VERSION "HNNBNNNYNNNNNNNNNNNNNNNNNNNNNNNNNNNNNNNNNN/4/%%%/4/'%**4NNN///"

NS_ :

BS_ :

BU_:  Airbag BAP_Tester ICAS1_Gateway ICAS1_KommunikationsServer LE1 LE2 Motor_BEV Schaltbetaetigung

BO_ 319 PreCrash_02: 8 Airbag
 SG_ PreCrash_Charisma_FahrPr  : 12|4@1+ (1.000000,0.000000) [0.000000|15.000000] "" ICAS1_Gateway
 SG_ PreCrash_Charisma_Status  : 16|2@1+ (1.000000,0.000000) [0.000000|3.000000] "" ICAS1_Gateway
 SG_ PreCrash_Schiebedach_schliessen  : 18|1@1+ (1.000000,0.000000) [0.000000|1.000000] "" ICAS1_Gateway
 SG_ PreCrash_Fenster_schliessen  : 19|1@1+ (1.000000,0.000000) [0.000000|1.000000] "" ICAS1_Gateway
 SG_ PreCrash_Blinken  : 20|3@1+ (1.000000,0.000000) [0.000000|7.000000] "" ICAS1_Gateway
 SG_ SC_PreSense_FCWP  : 23|1@1+ (1.000000,0.000000) [0.000000|1.000000] "" ICAS1_Gateway
 SG_ PreCrash_Tueren_Verriegeln  : 24|1@1+ (1.000000,0.000000) [0.000000|1.000000] "" ICAS1_Gateway
 SG_ PreCrash_FS_Laengsverstellung  : 25|1@1+ (1.000000,0.000000) [0.000000|1.000000] "" ICAS1_Gateway
 SG_ PreCrash_Anforderung_AFR  : 26|3@1+ (1.000000,0.000000) [0.000000|7.000000] "" ICAS1_Gateway
 SG_ SC_PreCrash_LED  : 29|2@1+ (1.000000,0.000000) [0.000000|3.000000] "" ICAS1_Gateway
 SG_ PreCrash_FS_Pneumatik_ansteuern  : 31|1@1+ (1.000000,0.000000) [0.000000|1.000000] "" ICAS1_Gateway
 SG_ PreCrash_BFS_Pneumatik_ansteuern  : 32|1@1+ (1.000000,0.000000) [0.000000|1.000000] "" ICAS1_Gateway
 SG_ PreCrash_Fo_Pneumatik_ansteuern  : 33|1@1+ (1.000000,0.000000) [0.000000|1.000000] "" ICAS1_Gateway
 SG_ PreCrash_FS_Sitzlehne_verfahren  : 34|3@1+ (1.000000,0.000000) [0.000000|7.000000] "" ICAS1_Gateway
 SG_ PreCrash_BFS_Sitzlehne_verfahren  : 37|3@1+ (1.000000,0.000000) [0.000000|7.000000] "" ICAS1_Gateway
 SG_ PreCrash_Fo_Sitzlehne_verfahren  : 40|3@1+ (1.000000,0.000000) [0.000000|7.000000] "" ICAS1_Gateway
 SG_ PreCrash_FS_KSV_verfahren  : 43|4@1+ (1.000000,0.000000) [0.000000|15.000000] "" ICAS1_Gateway
 SG_ PreCrash_BFS_KSV_verfahren  : 47|4@1+ (1.000000,0.000000) [0.000000|15.000000] "" ICAS1_Gateway
 SG_ PreCrash_Fo_KSV_verfahren  : 51|4@1+ (1.000000,0.000000) [0.000000|15.000000] "" ICAS1_Gateway
 SG_ PreCrash_BFS_Laengsverstellung  : 55|1@1+ (1.000000,0.000000) [0.000000|1.000000] "" ICAS1_Gateway
 SG_ SC_PreCrash_Warnung  : 56|4@1+ (1.000000,0.000000) [0.000000|15.000000] "" ICAS1_Gateway ICAS1_KommunikationsServer
 SG_ SC_PreCrash_Texte  : 60|4@1+ (1.000000,0.000000) [0.000000|15.000000] "" ICAS1_Gateway ICAS1_KommunikationsServer

BO_ 1122 PSD_04: 8 ICAS1_Gateway
 SG_ PSD_Segment_ID  : 0|6@1+ (1.000000,0.000000) [2.000000|63.000000] "" Motor_BEV
 SG_ PSD_Vorgaenger_Segment_ID  : 6|6@1+ (1.000000,0.000000) [2.000000|63.000000] "" Motor_BEV
 SG_ PSD_Segmentlaenge  : 12|7@1+ (2.000000,0.000000) [0.000000|254.000000] "Unit_Meter" Motor_BEV
 SG_ PSD_Strassenkategorie  : 19|3@1+ (1.000000,0.000000) [0.000000|7.000000] "" Motor_BEV
 SG_ PSD_Endkruemmung  : 22|8@1+ (1.000000,0.000000) [0.000000|254.000000] "Unit_None" Motor_BEV
 SG_ PSD_Endkruemmung_Vorz  : 30|1@1+ (1.000000,0.000000) [0.000000|1.000000] "" Motor_BEV
 SG_ PSD_Idenditaets_ID  : 31|6@1+ (1.000000,0.000000) [2.000000|63.000000] "" Vector__XXX
 SG_ PSD_ADAS_Qualitaet  : 37|1@1+ (1.000000,0.000000) [0.000000|1.000000] "" Motor_BEV
 SG_ PSD_wahrscheinlichster_Pfad  : 38|1@1+ (1.000000,0.000000) [0.000000|1.000000] "" Motor_BEV
 SG_ PSD_Geradester_Pfad  : 39|1@1+ (1.000000,0.000000) [0.000000|1.000000] "" Motor_BEV
 SG_ PSD_Fahrspuren_Anzahl  : 40|3@1+ (1.000000,0.000000) [0.000000|7.000000] "" Motor_BEV
 SG_ PSD_Bebauung  : 43|1@1+ (1.000000,0.000000) [0.000000|1.000000] "" Motor_BEV
 SG_ PSD_Segment_Komplett  : 44|1@1+ (1.000000,0.000000) [0.000000|1.000000] "" Motor_BEV
 SG_ PSD_Rampe  : 45|2@1+ (1.000000,0.000000) [0.000000|3.000000] "" Motor_BEV
 SG_ PSD_Anfangskruemmung  : 47|8@1+ (1.000000,0.000000) [0.000000|254.000000] "" Motor_BEV
 SG_ PSD_Anfangskruemmung_Vorz  : 55|1@1+ (1.000000,0.000000) [0.000000|1.000000] "" Motor_BEV
 SG_ PSD_Abzweigerichtung  : 56|1@1+ (1.000000,0.000000) [0.000000|1.000000] "" Motor_BEV
 SG_ PSD_Abzweigewinkel  : 57|7@1+ (1.417323,0.000000) [0.000000|180.000021] "" Motor_BEV

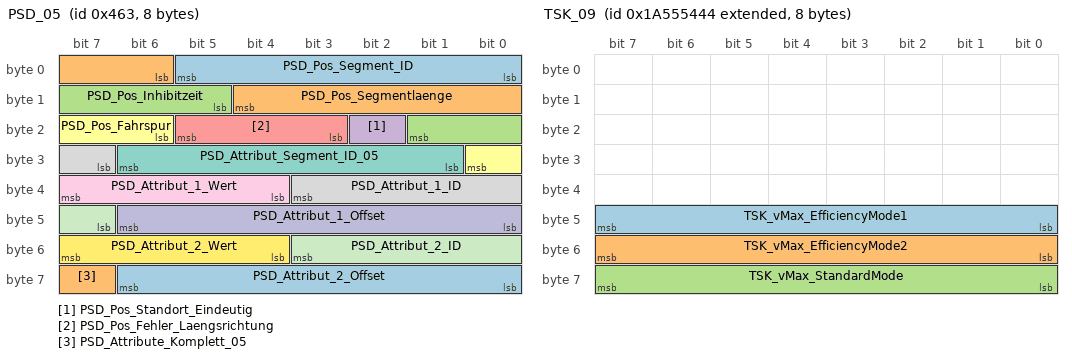
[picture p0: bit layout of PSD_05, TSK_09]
BO_ 1123 PSD_05: 8 ICAS1_Gateway
 SG_ PSD_Pos_Segment_ID  : 0|6@1+ (1.000000,0.000000) [2.000000|63.000000] "" Motor_BEV
 SG_ PSD_Pos_Segmentlaenge  : 6|7@1+ (2.000000,0.000000) [0.000000|254.000000] "Unit_Meter" Motor_BEV
 SG_ PSD_Pos_Inhibitzeit  : 13|5@1+ (10.000000,0.000000) [0.000000|310.000000] "Unit_MilliSecon" Motor_BEV
 SG_ PSD_Pos_Standort_Eindeutig  : 18|1@1+ (1.000000,0.000000) [0.000000|1.000000] "" Motor_BEV
 SG_ PSD_Pos_Fehler_Laengsrichtung  : 19|3@1+ (1.000000,0.000000) [0.000000|7.000000] "" Motor_BEV
 SG_ PSD_Pos_Fahrspur  : 22|3@1+ (1.000000,0.000000) [0.000000|7.000000] "" Motor_BEV
 SG_ PSD_Attribut_Segment_ID_05  : 25|6@1+ (1.000000,0.000000) [2.000000|63.000000] "" Motor_BEV
 SG_ PSD_Attribut_1_ID  : 31|5@1+ (1.000000,0.000000) [1.000000|31.000000] "" Motor_BEV
 SG_ PSD_Attribut_1_Wert  : 36|4@1+ (1.000000,0.000000) [0.000000|15.000000] "" Motor_BEV
 SG_ PSD_Attribut_1_Offset  : 40|7@1+ (2.000000,0.000000) [0.000000|254.000000] "Unit_Meter" Motor_BEV
 SG_ PSD_Attribut_2_ID  : 47|5@1+ (1.000000,0.000000) [1.000000|31.000000] "" Motor_BEV
 SG_ PSD_Attribut_2_Wert  : 52|4@1+ (1.000000,0.000000) [0.000000|15.000000] "" Motor_BEV
 SG_ PSD_Attribut_2_Offset  : 56|7@1+ (2.000000,0.000000) [0.000000|254.000000] "Unit_Meter" Motor_BEV
 SG_ PSD_Attribute_Komplett_05  : 63|1@1+ (1.000000,0.000000) [0.000000|1.000000] "" Motor_BEV

BO_ 1124 PSD_06: 8 ICAS1_Gateway
 SG_ PSD_06_Mux M : 0|3@1+ (1.000000,0.000000) [0.000000|7.000000] "" Motor_BEV
 SG_ PSD_Sys_Segment_ID m0 : 3|6@1+ (1.000000,0.000000) [2.000000|63.000000] "" Motor_BEV
 SG_ PSD_Attribut_Segment_ID m1 : 3|6@1+ (1.000000,0.000000) [2.000000|63.000000] "" Motor_BEV
 SG_ PSD_Ges_Segment_ID m2 : 3|6@1+ (1.000000,0.000000) [2.000000|63.000000] "" Motor_BEV
 SG_ PSD_Baum_Laenge_VZ m3 : 3|1@1+ (1.000000,0.000000) [0.000000|1.000000] "" Motor_BEV
 SG_ PSD_Steigung_1_Segment_ID m4 : 3|6@1+ (1.000000,0.000000) [2.000000|63.000000] "" Motor_BEV
 SG_ PSD_Baum_Laenge m3 : 4|25@1+ (0.000010,0.000000) [0.000000|180.000000] "Unit_DegreOfArc" Motor_BEV
 SG_ PSD_Sys_Laendercode m0 : 9|8@1+ (1.000000,0.000000) [0.000000|255.000000] "" Motor_BEV
 SG_ PSD_Attribut_3_ID m1 : 9|5@1+ (1.000000,0.000000) [1.000000|31.000000] "" Motor_BEV
 SG_ PSD_Ges_Offset m2 : 9|7@1+ (2.000000,0.000000) [0.000000|254.000000] "Unit_Meter" Motor_BEV
 SG_ PSD_Steigung_1_A_Steigung m4 : 9|7@1+ (0.120000,0.000000) [0.000000|15.000000] "Unit_PerCent" Motor_BEV
 SG_ PSD_Attribut_3_Offset m1 : 14|7@1+ (2.000000,0.000000) [0.000000|254.000000] "Unit_Meter" Motor_BEV
 SG_ PSD_Ges_Geschwindigkeit m2 : 16|5@1+ (1.000000,0.000000) [0.000000|31.000000] "" Motor_BEV
 SG_ PSD_Steigung_1_A_Vorz m4 : 16|1@1+ (1.000000,0.000000) [0.000000|1.000000] "" Motor_BEV
 SG_ PSD_Sys_Geschwindigkeit_Einheit m0 : 17|1@1+ (1.000000,0.000000) [0.000000|1.000000] "" Motor_BEV
 SG_ PSD_Steigung_1_A_Offset m4 : 17|7@1+ (2.000000,0.000000) [0.000000|254.000000] "Unit_Meter" Motor_BEV
 SG_ PSD_Sys_Verkehrsrichtung m0 : 18|1@1+ (1.000000,0.000000) [0.000000|1.000000] "" Motor_BEV
 SG_ PSD_Sys_Geometrieguete m0 : 19|2@1+ (1.000000,0.000000) [0.000000|3.000000] "" Motor_BEV
 SG_ PSD_Sys_Mapmatchingguete m0 : 21|2@1+ (1.000000,0.000000) [0.000000|3.000000] "" Motor_BEV
 SG_ PSD_Attribut_3_Wert m1 : 21|4@1+ (1.000000,0.000000) [0.000000|15.000000] "" Motor_BEV
 SG_ PSD_Ges_Typ m2 : 21|2@1+ (1.000000,0.000000) [0.000000|3.000000] "" Motor_BEV
 SG_ PSD_Sys_Alter_Karte m0 : 23|3@1+ (1.000000,0.000000) [0.000000|7.000000] "" Motor_BEV
 SG_ PSD_Ges_Spur_Geschw_Begrenzung m2 : 23|6@1+ (1.000000,0.000000) [0.000000|63.000000] "" Motor_BEV
 SG_ PSD_Steigung_1_B_Steigung m4 : 24|7@1+ (0.120000,0.000000) [0.000000|15.000000] "Unit_PerCent" Motor_BEV
 SG_ PSD_Attribut_4_ID m1 : 25|5@1+ (1.000000,0.000000) [1.000000|31.000000] "" Motor_BEV
 SG_ PSD_Sys_Zielfuehrung m0 : 26|1@1+ (1.000000,0.000000) [0.000000|1.000000] "" Motor_BEV
 SG_ PSD_Sys_US_State m0 : 27|6@1+ (1.000000,0.000000) [0.000000|63.000000] "" Motor_BEV
 SG_ PSD_Ges_Geschwindigkeit_Gespann m2 : 29|2@1+ (1.000000,0.000000) [0.000000|3.000000] "" Motor_BEV
 SG_ PSD_Baum_Breite_VZ m3 : 29|1@1+ (1.000000,0.000000) [0.000000|1.000000] "" Motor_BEV
 SG_ PSD_Attribut_4_Wert m1 : 30|4@1+ (1.000000,0.000000) [0.000000|15.000000] "" Motor_BEV
 SG_ PSD_Baum_Breite m3 : 30|24@1+ (0.000010,0.000000) [0.000000|90.000000] "Unit_DegreOfArc" Motor_BEV
 SG_ PSD_Ges_Geschwindigkeit_Witter m2 : 31|2@1+ (1.000000,0.000000) [0.000000|3.000000] "" Motor_BEV
 SG_ PSD_Steigung_1_B_Vorz m4 : 31|1@1+ (1.000000,0.000000) [0.000000|1.000000] "" Motor_BEV
 SG_ PSD_Steigung_1_B_Offset m4 : 32|7@1+ (2.000000,0.000000) [0.000000|254.000000] "Unit_Meter" Motor_BEV
 SG_ PSD_Sys_Quali_Geometrien m0 : 33|3@1+ (1.000000,0.000000) [0.000000|7.000000] "Unit_None" Vector__XXX
 SG_ PSD_Ges_Geschwindigkeit_Tag_Anf m2 : 33|3@1+ (1.000000,0.000000) [0.000000|7.000000] "" Motor_BEV
 SG_ PSD_Attribut_4_Offset m1 : 34|7@1+ (2.000000,0.000000) [0.000000|254.000000] "Unit_Meter" Motor_BEV
 SG_ PSD_Sys_Quali_Ortsinfo m0 : 36|2@1+ (1.000000,0.000000) [0.000000|3.000000] "Unit_None" Vector__XXX
 SG_ PSD_Ges_Geschwindigkeit_Tag_Ende m2 : 36|3@1+ (1.000000,0.000000) [0.000000|7.000000] "" Motor_BEV
 SG_ PSD_Sys_Quali_verfuegbar m0 : 38|1@1+ (1.000000,0.000000) [0.000000|1.000000] "" Vector__XXX
 SG_ PSD_Sys_Zielfuehrung_geaendert m0 : 39|1@1+ (1.000000,0.000000) [0.000000|1.000000] "" Motor_BEV
 SG_ PSD_Ges_Geschwindigkeit_Std_Anf m2 : 39|5@1+ (1.000000,0.000000) [0.000000|24.000000] "Unit_Hours" Motor_BEV
 SG_ PSD_Steigung_1_Attribute_kompl m4 : 39|1@1+ (1.000000,0.000000) [0.000000|1.000000] "" Motor_BEV
 SG_ PSD_Sys_Geometrieguete_erweitert m0 : 40|8@1+ (1.000000,0.000000) [0.000000|255.000000] "" Vector__XXX
 SG_ PSD_Steigung_2_Segment_ID m4 : 40|6@1+ (1.000000,0.000000) [2.000000|63.000000] "" Motor_BEV
 SG_ PSD_Attribut_5_ID m1 : 41|5@1+ (1.000000,0.000000) [1.000000|31.000000] "" Motor_BEV
 SG_ PSD_Ges_Geschwindigkeit_Std_Ende m2 : 44|5@1+ (1.000000,0.000000) [0.000000|24.000000] "Unit_Hours" Motor_BEV
 SG_ PSD_Attribut_5_Offset m1 : 46|7@1+ (2.000000,0.000000) [0.000000|254.000000] "Unit_Meter" Motor_BEV
 SG_ PSD_Steigung_2_Steigung m4 : 46|7@1+ (0.120000,0.000000) [0.000000|15.000000] "Unit_PerCent" Motor_BEV
 SG_ PSD_Sys_Quali_sonstige_Attribute m0 : 48|3@1+ (1.000000,0.000000) [0.000000|7.000000] "Unit_None" Vector__XXX
 SG_ PSD_Ges_Ueberholverbot m2 : 49|2@1+ (1.000000,0.000000) [0.000000|3.000000] "" Vector__XXX
 SG_ PSD_Sys_Quali_Steigungen m0 : 51|3@1+ (1.000000,0.000000) [0.000000|7.000000] "" Vector__XXX
 SG_ PSD_Ges_Wechselverkehrszeichen m2 : 51|3@1+ (1.000000,0.000000) [0.000000|7.000000] "" Vector__XXX
 SG_ PSD_Attribut_5_Wert m1 : 53|4@1+ (1.000000,0.000000) [0.000000|15.000000] "" Motor_BEV
 SG_ PSD_Steigung_2_Vorz m4 : 53|1@1+ (1.000000,0.000000) [0.000000|1.000000] "" Motor_BEV
 SG_ PSD_Sys_Quali_Strassenkennz m0 : 54|3@1+ (1.000000,0.000000) [0.000000|7.000000] "Unit_None" Vector__XXX
 SG_ PSD_Wechselverkehrszeichen_Typ m2 : 54|2@1+ (1.000000,0.000000) [0.000000|3.000000] "" Vector__XXX
 SG_ PSD_Baum_Ausrichtung m3 : 54|10@1+ (0.351562,0.000000) [0.000000|359.648438] "Unit_DegreOfArc" Vector__XXX
 SG_ PSD_Steigung_2_Offset m4 : 54|7@1+ (2.000000,0.000000) [0.000000|254.000000] "Unit_Meter" Motor_BEV
 SG_ PSD_Ges_Gesetzlich_Kategorie m2 : 56|3@1+ (1.000000,0.000000) [0.000000|7.000000] "" Motor_BEV
 SG_ PSD_Sys_Quali_Tempolimits m0 : 57|3@1+ (1.000000,0.000000) [0.000000|7.000000] "Unit_None" Vector__XXX
 SG_ PSD_Attribute_Komplett_06 m1 : 57|1@1+ (1.000000,0.000000) [0.000000|1.000000] "" Motor_BEV
 SG_ PSD_Ges_Gesetzlich_Zusatz m2 : 59|2@1+ (1.000000,0.000000) [0.000000|3.000000] "" Motor_BEV
 SG_ PSD_Sys_Quali_Vorfahrtsregelung m0 : 60|3@1+ (1.000000,0.000000) [0.000000|7.000000] "Unit_None" Vector__XXX
 SG_ PSD_Ges_Verkehrszeichen_Quelle m2 : 61|2@1+ (1.000000,0.000000) [0.000000|3.000000] "" Motor_BEV
 SG_ PSD_Steigung_2_Attribute_kompl m4 : 61|1@1+ (1.000000,0.000000) [0.000000|1.000000] "" Motor_BEV
 SG_ PSD_Ges_Attribute_Komplett m2 : 63|1@1+ (1.000000,0.000000) [0.000000|1.000000] "" Motor_BEV

BO_ 591 RDR1_Objekte_02: 64 ICAS1_Gateway
 SG_ RDR1_relevanter_Fehler  : 12|1@1+ (1.000000,0.000000) [0.000000|1.000000] "" Motor_BEV
 SG_ RDR1_Blindheit_erkannt  : 13|1@1+ (1.000000,0.000000) [0.000000|1.000000] "" Motor_BEV
 SG_ RDR1_relev_Nichtverfuegbarkeit  : 14|1@1+ (1.000000,0.000000) [0.000000|1.000000] "" Motor_BEV
 SG_ RDR1_Obj_01_Nummer  : 16|6@1+ (1.000000,0.000000) [0.000000|63.000000] "" Vector__XXX
 SG_ RDR1_Obj_02_Nummer  : 22|6@1+ (1.000000,0.000000) [0.000000|63.000000] "" Vector__XXX
 SG_ RDR1_Obj_03_Nummer  : 28|6@1+ (1.000000,0.000000) [0.000000|63.000000] "" Vector__XXX
 SG_ RDR1_Obj_04_Nummer  : 34|6@1+ (1.000000,0.000000) [0.000000|63.000000] "" Vector__XXX
 SG_ RDR1_Obj_05_Nummer  : 40|6@1+ (1.000000,0.000000) [0.000000|63.000000] "" Vector__XXX
 SG_ RDR1_Obj_06_Nummer  : 46|6@1+ (1.000000,0.000000) [0.000000|63.000000] "" Vector__XXX
 SG_ RDR1_Verkehrssinn  : 52|2@1+ (1.000000,0.000000) [0.000000|3.000000] "" Vector__XXX
 SG_ RDR1_Objekte_02_Datenalter  : 54|10@1+ (0.000977,0.000000) [0.000000|0.998047] "Unit_Secon" Vector__XXX
 SG_ RDR1_Obj_01_dx_v  : 64|12@1+ (0.062500,0.000000) [0.000000|255.937500] "Unit_Meter" Motor_BEV
 SG_ RDR1_Obj_01_dy_v  : 76|10@1+ (0.062500,-32.000000) [-32.000000|31.937500] "Unit_Meter" Motor_BEV
 SG_ RDR1_Obj_01_vx_v  : 86|10@1+ (0.250000,-128.000000) [-128.000000|127.750000] "Unit_MeterPerSecon" Motor_BEV
 SG_ RDR1_Obj_02_dx_v  : 96|12@1+ (0.062500,0.000000) [0.000000|255.937500] "Unit_Meter" Vector__XXX
 SG_ RDR1_Obj_02_dy_v  : 108|10@1+ (0.062500,-32.000000) [-32.000000|31.937500] "Unit_Meter" Vector__XXX
 SG_ RDR1_Obj_02_vx_v  : 118|10@1+ (0.250000,-128.000000) [-128.000000|127.750000] "Unit_MeterPerSecon" Vector__XXX
 SG_ RDR1_Obj_03_dx_v  : 128|12@1+ (0.062500,0.000000) [0.000000|255.937500] "Unit_Meter" Vector__XXX
 SG_ RDR1_Obj_03_dy_v  : 140|10@1+ (0.062500,-32.000000) [-32.000000|31.937500] "Unit_Meter" Vector__XXX
 SG_ RDR1_Obj_03_vx_v  : 150|10@1+ (0.250000,-128.000000) [-128.000000|127.750000] "Unit_MeterPerSecon" Vector__XXX
 SG_ RDR1_Obj_04_dx_v  : 160|12@1+ (0.062500,0.000000) [0.000000|255.937500] "Unit_Meter" Motor_BEV
 SG_ RDR1_Obj_04_dy_v  : 172|10@1+ (0.062500,-32.000000) [-32.000000|31.937500] "Unit_Meter" Vector__XXX
 SG_ RDR1_Obj_04_vx_v  : 182|10@1+ (0.250000,-128.000000) [-128.000000|127.750000] "Unit_MeterPerSecon" Motor_BEV
 SG_ RDR1_Obj_05_dx_v  : 192|12@1+ (0.062500,0.000000) [0.000000|255.937500] "Unit_Meter" Vector__XXX
 SG_ RDR1_Obj_05_dy_v  : 204|10@1+ (0.062500,-32.000000) [-32.000000|31.937500] "Unit_Meter" Vector__XXX
 SG_ RDR1_Obj_05_vx_v  : 214|10@1+ (0.250000,-128.000000) [-128.000000|127.750000] "Unit_MeterPerSecon" Vector__XXX
 SG_ RDR1_Obj_06_dx_v  : 224|12@1+ (0.062500,0.000000) [0.000000|255.937500] "Unit_Meter" Vector__XXX
 SG_ RDR1_Obj_06_dy_v  : 236|10@1+ (0.062500,-32.000000) [-32.000000|31.937500] "Unit_Meter" Vector__XXX
 SG_ RDR1_Obj_06_vx_v  : 246|10@1+ (0.250000,-128.000000) [-128.000000|127.750000] "Unit_MeterPerSecon" Vector__XXX
 SG_ RDR1_Obj_01_ax_v  : 256|8@1+ (0.125000,-16.000000) [-16.000000|15.750000] "Unit_MeterPerSeconSquar" Motor_BEV
 SG_ RDR1_Obj_01_ax_StdA  : 264|6@1+ (0.125000,0.000000) [0.000000|7.750000] "Unit_MeterPerSeconSquar" Motor_BEV
 SG_ RDR1_Obj_01_vx_StdA  : 270|7@1+ (0.031250,0.000000) [0.000000|3.937500] "Unit_MeterPerSecon" Motor_BEV
 SG_ RDR1_Obj_01_dx_StdA  : 277|7@1+ (0.050000,0.000000) [0.000000|6.300000] "Unit_Meter" Motor_BEV
 SG_ RDR1_Obj_01_dy_StdA  : 284|7@1+ (0.062500,0.000000) [0.000000|7.875000] "Unit_Meter" Motor_BEV

BO_ 2033 Request_Airbag_Deployment: 8 ICAS1_Gateway
 SG_ Request_Airbag_Deployment  : 0|64@1+ (1.000000,0.000000) [0.000000|18446744073709551616.000000] "" Airbag

BO_ 2041 Response_Airbag_Deployment: 8 Airbag
 SG_ Response_Airbag_Deployment  : 0|64@1+ (1.000000,0.000000) [0.000000|18446744073709551616.000000] "" ICAS1_Gateway

BO_ 980 SMLS_01: 8 ICAS1_Gateway
 SG_ SMLS_01_CRC  : 0|8@1+ (1.000000,0.000000) [0.000000|255.000000] "" Vector__XXX
 SG_ SMLS_01_BZ  : 8|4@1+ (1.000000,0.000000) [0.000000|15.000000] "" Vector__XXX
 SG_ BH_Blinker_li  : 12|1@1+ (1.000000,0.000000) [0.000000|1.000000] "" Motor_BEV
 SG_ BH_Blinker_re  : 13|1@1+ (1.000000,0.000000) [0.000000|1.000000] "" Motor_BEV
 SG_ BH_Lichthupe  : 14|1@1+ (1.000000,0.000000) [0.000000|1.000000] "" Vector__XXX
 SG_ BH_Fernlicht  : 15|1@1+ (1.000000,0.000000) [0.000000|1.000000] "" Vector__XXX
 SG_ WH_Tipwischen  : 16|1@1+ (1.000000,0.000000) [0.000000|1.000000] "" Vector__XXX
 SG_ WH_Intervall  : 17|1@1+ (1.000000,0.000000) [0.000000|1.000000] "" Vector__XXX
 SG_ WH_WischerStufe1  : 18|1@1+ (1.000000,0.000000) [0.000000|1.000000] "" Vector__XXX
 SG_ WH_WischerStufe2  : 19|1@1+ (1.000000,0.000000) [0.000000|1.000000] "" Vector__XXX
 SG_ WH_Frontwaschen  : 20|1@1+ (1.000000,0.000000) [0.000000|1.000000] "" Vector__XXX
 SG_ WH_Heckintervall  : 21|1@1+ (1.000000,0.000000) [0.000000|1.000000] "" Vector__XXX
 SG_ WH_Heckwaschen  : 22|1@1+ (1.000000,0.000000) [0.000000|1.000000] "" Vector__XXX
 SG_ WH_Intervallstufen  : 23|4@1+ (1.000000,0.000000) [0.000000|15.000000] "" Vector__XXX
 SG_ FAS_Taster  : 27|1@1+ (1.000000,0.000000) [0.000000|1.000000] "" Vector__XXX
 SG_ FAS_Taster_Fehler  : 28|1@1+ (1.000000,0.000000) [0.000000|1.000000] "" Vector__XXX
 SG_ SMLS_Hupe  : 29|1@1+ (1.000000,0.000000) [0.000000|1.000000] "" Vector__XXX
 SG_ LRH_on_off  : 30|2@1+ (1.000000,0.000000) [0.000000|3.000000] "" Vector__XXX
 SG_ LSS_Tastencode  : 32|8@1+ (1.000000,0.000000) [0.000000|255.000000] "" Vector__XXX
 SG_ LRH_aktiv  : 40|1@1+ (1.000000,0.000000) [0.000000|1.000000] "" Vector__XXX
 SG_ SMLS_P_verriegelt  : 41|2@1+ (1.000000,0.000000) [0.000000|3.000000] "" Vector__XXX
 SG_ SMLS_P_verriegelt_plausibel  : 43|1@1+ (1.000000,0.000000) [0.000000|1.000000] "" Vector__XXX
 SG_ WH_SRA  : 44|1@1+ (1.000000,0.000000) [0.000000|1.000000] "" Vector__XXX
 SG_ WH_Wischer_Fehler  : 45|1@1+ (1.000000,0.000000) [0.000000|1.000000] "" Vector__XXX
 SG_ BH_Blinker_Fehler  : 46|1@1+ (1.000000,0.000000) [0.000000|1.000000] "" Vector__XXX
 SG_ SMLS_PTT  : 47|1@1+ (1.000000,0.000000) [0.000000|1.000000] "" Vector__XXX
 SG_ WH_Tipwischen_lang  : 48|1@1+ (1.000000,0.000000) [0.000000|1.000000] "" Vector__XXX

BO_ 2464153718 SOK_FoD_MO_01_Req_Chal_01: 8 Motor_BEV
 SG_ SOK_FoD_MO_01_Req_Challenge  : 0|64@1+ (1.000000,0.000000) [0.000000|18446744073709551616.000000] "Unit_None" ICAS1_Gateway

BO_ 2464284790 SOK_FoD_MO_01_Resp_Chal_01: 8 ICAS1_Gateway
 SG_ SOK_FoD_MO_01_Resp_Challenge  : 0|64@1+ (1.000000,0.000000) [0.000000|18446744073709551616.000000] "Unit_None" Motor_BEV

BO_ 1413 Systeminfo_01: 8 ICAS1_Gateway
 SG_ SI_Sammel_SG_Fehler  : 0|6@1+ (1.000000,0.000000) [0.000000|60.000000] "" Vector__XXX
 SG_ SI_P_Mode_gueltig  : 6|1@1+ (1.000000,0.000000) [0.000000|1.000000] "" Vector__XXX
 SG_ SI_Diagnose_Aktiv  : 7|1@1+ (1.000000,0.000000) [0.000000|1.000000] "" Vector__XXX
 SG_ SI_QRS_Mode  : 8|1@1+ (1.000000,0.000000) [0.000000|1.000000] "" Airbag Motor_BEV
 SG_ SI_T_Mode  : 9|1@1+ (1.000000,0.000000) [0.000000|1.000000] "" Motor_BEV
 SG_ SI_NWDF  : 10|1@1+ (1.000000,0.000000) [0.000000|1.000000] "" Vector__XXX
 SG_ SI_NWDF_gueltig  : 11|1@1+ (1.000000,0.000000) [0.000000|1.000000] "" Vector__XXX
 SG_ SI_Sammelfehler  : 12|1@1+ (1.000000,0.000000) [0.000000|1.000000] "" Vector__XXX
 SG_ GW_KD_Fehler  : 13|1@1+ (1.000000,0.000000) [0.000000|1.000000] "" Vector__XXX
 SG_ SI_T_Schutz  : 14|1@1+ (1.000000,0.000000) [0.000000|1.000000] "" Motor_BEV
 SG_ SI_P_Mode  : 15|1@1+ (1.000000,0.000000) [0.000000|1.000000] "" Vector__XXX
 SG_ SI_BUS_01  : 16|1@1+ (1.000000,0.000000) [0.000000|1.000000] "" Vector__XXX
 SG_ SI_BUS_02  : 17|1@1+ (1.000000,0.000000) [0.000000|1.000000] "" Vector__XXX
 SG_ SI_BUS_03  : 18|1@1+ (1.000000,0.000000) [0.000000|1.000000] "" Vector__XXX
 SG_ SI_BUS_04  : 19|1@1+ (1.000000,0.000000) [0.000000|1.000000] "" Vector__XXX
 SG_ SI_BUS_05  : 20|1@1+ (1.000000,0.000000) [0.000000|1.000000] "" Vector__XXX
 SG_ SI_BUS_06  : 21|1@1+ (1.000000,0.000000) [0.000000|1.000000] "" Vector__XXX
 SG_ SI_BUS_07  : 22|1@1+ (1.000000,0.000000) [0.000000|1.000000] "" Vector__XXX
 SG_ SI_BUS_08  : 23|1@1+ (1.000000,0.000000) [0.000000|1.000000] "" Vector__XXX
 SG_ SI_BUS_09  : 24|1@1+ (1.000000,0.000000) [0.000000|1.000000] "" Vector__XXX
 SG_ SI_BUS_10  : 25|1@1+ (1.000000,0.000000) [0.000000|1.000000] "" Vector__XXX
 SG_ SI_BUS_11  : 26|1@1+ (1.000000,0.000000) [0.000000|1.000000] "" Vector__XXX
 SG_ SI_BUS_12  : 27|1@1+ (1.000000,0.000000) [0.000000|1.000000] "" Vector__XXX
 SG_ SI_BUS_13  : 28|1@1+ (1.000000,0.000000) [0.000000|1.000000] "" Vector__XXX
 SG_ SI_BUS_14  : 29|1@1+ (1.000000,0.000000) [0.000000|1.000000] "" Vector__XXX
 SG_ SI_BUS_15  : 30|1@1+ (1.000000,0.000000) [0.000000|1.000000] "" Vector__XXX
 SG_ SI_Bus_Identifikation  : 32|8@1+ (1.000000,0.000000) [0.000000|255.000000] "" Vector__XXX
 SG_ SI_CAB_V10  : 40|24@1+ (1.000000,0.000000) [0.000000|16777215.000000] "" Vector__XXX

BO_ 2589283396 TSK_09: 8 Motor_BEV
 SG_ TSK_vMax_EfficiencyMode1  : 40|8@1+ (1.000000,0.000000) [0.000000|253.000000] "Unit_KiloMeterPerHour" ICAS1_Gateway
 SG_ TSK_vMax_EfficiencyMode2  : 48|8@1+ (1.000000,0.000000) [0.000000|253.000000] "Unit_KiloMeterPerHour" ICAS1_Gateway
 SG_ TSK_vMax_StandardMode  : 56|8@1+ (1.000000,0.000000) [0.000000|253.000000] "Unit_KiloMeterPerHour" ICAS1_Gateway

BO_ 1019 TSK_Ausrollkurve_01: 8 Motor_BEV
 SG_ TSK_Ausrollkurve_Schub_Reku_01 m0 : 0|7@1+ (2.000000,0.000000) [0.000000|252.000000] "Unit_KiloMeterPerHour" ICAS1_Gateway
 SG_ TSK_Ausrollkurve_Schub_Reku_05 m1 : 0|7@1+ (2.000000,0.000000) [0.000000|252.000000] "Unit_KiloMeterPerHour" ICAS1_Gateway
 SG_ TSK_Ausrollkurve_Schub_Reku_09 m2 : 0|7@1+ (2.000000,0.000000) [0.000000|252.000000] "Unit_KiloMeterPerHour" ICAS1_Gateway
 SG_ TSK_Ausrollkurve_Schub_Reku_13 m3 : 0|7@1+ (2.000000,0.000000) [0.000000|252.000000] "Unit_KiloMeterPerHour" ICAS1_Gateway
 SG_ TSK_Ausrollkurve_Schub_Reku_17 m4 : 0|7@1+ (2.000000,0.000000) [0.000000|252.000000] "Unit_KiloMeterPerHour" ICAS1_Gateway
 SG_ TSK_Ausrollkurve_Schub_Reku_02 m0 : 7|7@1+ (2.000000,0.000000) [0.000000|252.000000] "Unit_KiloMeterPerHour" ICAS1_Gateway
 SG_ TSK_Ausrollkurve_Schub_Reku_06 m1 : 7|7@1+ (2.000000,0.000000) [0.000000|252.000000] "Unit_KiloMeterPerHour" ICAS1_Gateway
 SG_ TSK_Ausrollkurve_Schub_Reku_10 m2 : 7|7@1+ (2.000000,0.000000) [0.000000|252.000000] "Unit_KiloMeterPerHour" ICAS1_Gateway
 SG_ TSK_Ausrollkurve_Schub_Reku_14 m3 : 7|7@1+ (2.000000,0.000000) [0.000000|252.000000] "Unit_KiloMeterPerHour" ICAS1_Gateway
 SG_ TSK_Ausrollkurve_Schub_Reku_18 m4 : 7|7@1+ (2.000000,0.000000) [0.000000|252.000000] "Unit_KiloMeterPerHour" ICAS1_Gateway
 SG_ TSK_Ausrollkurve_Schub_Reku_03 m0 : 14|7@1+ (2.000000,0.000000) [0.000000|252.000000] "Unit_KiloMeterPerHour" ICAS1_Gateway
 SG_ TSK_Ausrollkurve_Schub_Reku_07 m1 : 14|7@1+ (2.000000,0.000000) [0.000000|252.000000] "Unit_KiloMeterPerHour" ICAS1_Gateway
 SG_ TSK_Ausrollkurve_Schub_Reku_11 m2 : 14|7@1+ (2.000000,0.000000) [0.000000|252.000000] "Unit_KiloMeterPerHour" ICAS1_Gateway
 SG_ TSK_Ausrollkurve_Schub_Reku_15 m3 : 14|7@1+ (2.000000,0.000000) [0.000000|252.000000] "Unit_KiloMeterPerHour" ICAS1_Gateway
 SG_ TSK_Ausrollkurve_Schub_Reku_19 m4 : 14|7@1+ (2.000000,0.000000) [0.000000|252.000000] "Unit_KiloMeterPerHour" ICAS1_Gateway
 SG_ TSK_Ausrollkurve_Schub_Reku_04 m0 : 21|7@1+ (2.000000,0.000000) [0.000000|252.000000] "Unit_KiloMeterPerHour" ICAS1_Gateway
 SG_ TSK_Ausrollkurve_Schub_Reku_08 m1 : 21|7@1+ (2.000000,0.000000) [0.000000|252.000000] "Unit_KiloMeterPerHour" ICAS1_Gateway
 SG_ TSK_Ausrollkurve_Schub_Reku_12 m2 : 21|7@1+ (2.000000,0.000000) [0.000000|252.000000] "Unit_KiloMeterPerHour" ICAS1_Gateway
 SG_ TSK_Ausrollkurve_Schub_Reku_16 m3 : 21|7@1+ (2.000000,0.000000) [0.000000|252.000000] "Unit_KiloMeterPerHour" ICAS1_Gateway
 SG_ TSK_Ausrollkurve_Schub_Reku_20 m4 : 21|7@1+ (2.000000,0.000000) [0.000000|252.000000] "Unit_KiloMeterPerHour" ICAS1_Gateway
 SG_ TSK_Ausrollkurve_Segeln_01 m0 : 28|7@1+ (2.000000,0.000000) [0.000000|252.000000] "Unit_KiloMeterPerHour" ICAS1_Gateway
 SG_ TSK_Ausrollkurve_Segeln_05 m1 : 28|7@1+ (2.000000,0.000000) [0.000000|252.000000] "Unit_KiloMeterPerHour" ICAS1_Gateway
 SG_ TSK_Ausrollkurve_Segeln_09 m2 : 28|7@1+ (2.000000,0.000000) [0.000000|252.000000] "Unit_KiloMeterPerHour" ICAS1_Gateway
 SG_ TSK_Ausrollkurve_Segeln_13 m3 : 28|7@1+ (2.000000,0.000000) [0.000000|252.000000] "Unit_KiloMeterPerHour" ICAS1_Gateway
 SG_ TSK_Ausrollkurve_Segeln_17 m4 : 28|7@1+ (2.000000,0.000000) [0.000000|252.000000] "Unit_KiloMeterPerHour" ICAS1_Gateway
 SG_ TSK_Ausrollkurve_Segeln_02 m0 : 35|7@1+ (2.000000,0.000000) [0.000000|252.000000] "Unit_KiloMeterPerHour" ICAS1_Gateway
 SG_ TSK_Ausrollkurve_Segeln_06 m1 : 35|7@1+ (2.000000,0.000000) [0.000000|252.000000] "Unit_KiloMeterPerHour" ICAS1_Gateway
 SG_ TSK_Ausrollkurve_Segeln_10 m2 : 35|7@1+ (2.000000,0.000000) [0.000000|252.000000] "Unit_KiloMeterPerHour" ICAS1_Gateway
 SG_ TSK_Ausrollkurve_Segeln_14 m3 : 35|7@1+ (2.000000,0.000000) [0.000000|252.000000] "Unit_KiloMeterPerHour" ICAS1_Gateway
 SG_ TSK_Ausrollkurve_Segeln_18 m4 : 35|7@1+ (2.000000,0.000000) [0.000000|252.000000] "Unit_KiloMeterPerHour" ICAS1_Gateway
 SG_ TSK_Ausrollkurve_Segeln_03 m0 : 42|7@1+ (2.000000,0.000000) [0.000000|252.000000] "Unit_KiloMeterPerHour" ICAS1_Gateway
 SG_ TSK_Ausrollkurve_Segeln_07 m1 : 42|7@1+ (2.000000,0.000000) [0.000000|252.000000] "Unit_KiloMeterPerHour" ICAS1_Gateway
 SG_ TSK_Ausrollkurve_Segeln_11 m2 : 42|7@1+ (2.000000,0.000000) [0.000000|252.000000] "Unit_KiloMeterPerHour" ICAS1_Gateway
 SG_ TSK_Ausrollkurve_Segeln_15 m3 : 42|7@1+ (2.000000,0.000000) [0.000000|252.000000] "Unit_KiloMeterPerHour" ICAS1_Gateway
 SG_ TSK_Ausrollkurve_Segeln_19 m4 : 42|7@1+ (2.000000,0.000000) [0.000000|252.000000] "Unit_KiloMeterPerHour" ICAS1_Gateway
 SG_ TSK_Ausrollkurve_Segeln_04 m0 : 49|7@1+ (2.000000,0.000000) [0.000000|252.000000] "Unit_KiloMeterPerHour" ICAS1_Gateway
 SG_ TSK_Ausrollkurve_Segeln_08 m1 : 49|7@1+ (2.000000,0.000000) [0.000000|252.000000] "Unit_KiloMeterPerHour" ICAS1_Gateway
 SG_ TSK_Ausrollkurve_Segeln_12 m2 : 49|7@1+ (2.000000,0.000000) [0.000000|252.000000] "Unit_KiloMeterPerHour" ICAS1_Gateway
 SG_ TSK_Ausrollkurve_Segeln_16 m3 : 49|7@1+ (2.000000,0.000000) [0.000000|252.000000] "Unit_KiloMeterPerHour" ICAS1_Gateway
 SG_ TSK_Ausrollkurve_Segeln_20 m4 : 49|7@1+ (2.000000,0.000000) [0.000000|252.000000] "Unit_KiloMeterPerHour" ICAS1_Gateway
 SG_ TSK_Ausrollkurve_Mux M : 56|3@1+ (1.000000,0.000000) [0.000000|7.000000] "" ICAS1_Gateway
 SG_ TSK_Ausrollkurve_Reku  : 59|1@1+ (1.000000,0.000000) [0.000000|1.000000] "" ICAS1_Gateway
 SG_ TSK_Ausrollkurve_Schrittweite  : 60|1@1+ (1.000000,0.000000) [0.000000|1.000000] "" ICAS1_Gateway
 SG_ TSK_Ausrollkurve_Zaehler  : 61|2@1+ (1.000000,0.000000) [0.000000|3.000000] "" ICAS1_Gateway

BO_ 1716 VIN_01: 8 ICAS1_Gateway
 SG_ VIN_01_MUX M : 0|2@1+ (1.000000,0.000000) [0.000000|3.000000] "" Airbag Motor_BEV
 SG_ KS_Geheimnis_1 m0 : 8|8@1+ (1.000000,0.000000) [0.000000|255.000000] "" Airbag
 SG_ VIN_4 m1 : 8|8@1+ (1.000000,0.000000) [0.000000|255.000000] "" Airbag Motor_BEV
 SG_ VIN_11 m2 : 8|8@1+ (1.000000,0.000000) [0.000000|255.000000] "" Airbag Motor_BEV
 SG_ KS_Geheimnis_2 m0 : 16|8@1+ (1.000000,0.000000) [0.000000|255.000000] "" Airbag
 SG_ VIN_5 m1 : 16|8@1+ (1.000000,0.000000) [0.000000|255.000000] "" Airbag Motor_BEV
 SG_ VIN_12 m2 : 16|8@1+ (1.000000,0.000000) [0.000000|255.000000] "" Airbag Motor_BEV
 SG_ KS_Geheimnis_3 m0 : 24|8@1+ (1.000000,0.000000) [0.000000|255.000000] "" Airbag
 SG_ VIN_6 m1 : 24|8@1+ (1.000000,0.000000) [0.000000|255.000000] "" Airbag Motor_BEV
 SG_ VIN_13 m2 : 24|8@1+ (1.000000,0.000000) [0.000000|255.000000] "" Airbag Motor_BEV
 SG_ KS_Geheimnis_4 m0 : 32|8@1+ (1.000000,0.000000) [0.000000|255.000000] "" Airbag
 SG_ VIN_7 m1 : 32|8@1+ (1.000000,0.000000) [0.000000|255.000000] "" Airbag Motor_BEV
 SG_ VIN_14 m2 : 32|8@1+ (1.000000,0.000000) [0.000000|255.000000] "" Airbag Motor_BEV
 SG_ VIN_1 m0 : 40|8@1+ (1.000000,0.000000) [0.000000|255.000000] "" Airbag Motor_BEV
 SG_ VIN_8 m1 : 40|8@1+ (1.000000,0.000000) [0.000000|255.000000] "" Airbag Motor_BEV
 SG_ VIN_15 m2 : 40|8@1+ (1.000000,0.000000) [0.000000|255.000000] "" Airbag Motor_BEV
 SG_ VIN_2 m0 : 48|8@1+ (1.000000,0.000000) [0.000000|255.000000] "" Airbag Motor_BEV
 SG_ VIN_9 m1 : 48|8@1+ (1.000000,0.000000) [0.000000|255.000000] "" Airbag Motor_BEV
 SG_ VIN_16 m2 : 48|8@1+ (1.000000,0.000000) [0.000000|255.000000] "" Airbag Motor_BEV
 SG_ VIN_3 m0 : 56|8@1+ (1.000000,0.000000) [0.000000|255.000000] "" Airbag Motor_BEV
 SG_ VIN_10 m1 : 56|8@1+ (1.000000,0.000000) [0.000000|255.000000] "" Airbag Motor_BEV
 SG_ VIN_17 m2 : 56|8@1+ (1.000000,0.000000) [0.000000|255.000000] "" Airbag Motor_BEV

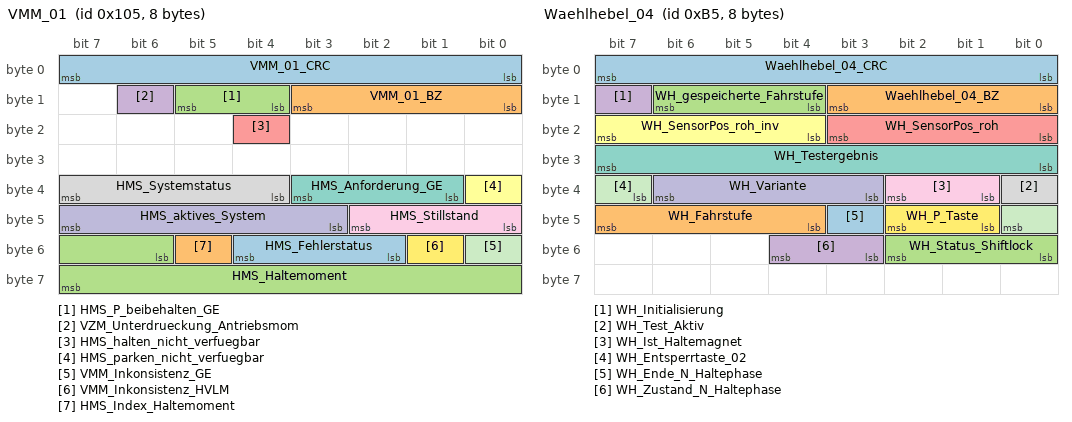
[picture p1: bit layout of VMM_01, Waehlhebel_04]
BO_ 261 VMM_01: 8 ICAS1_Gateway
 SG_ VMM_01_CRC  : 0|8@1+ (1.000000,0.000000) [0.000000|255.000000] "" Motor_BEV
 SG_ VMM_01_BZ  : 8|4@1+ (1.000000,0.000000) [0.000000|15.000000] "" Motor_BEV
 SG_ HMS_P_beibehalten_GE  : 12|2@1+ (1.000000,0.000000) [0.000000|3.000000] "" Vector__XXX
 SG_ VZM_Unterdrueckung_Antriebsmom  : 14|1@1+ (1.000000,0.000000) [0.000000|1.000000] "" Airbag Motor_BEV
 SG_ HMS_halten_nicht_verfuegbar  : 20|1@1+ (1.000000,0.000000) [0.000000|1.000000] "" Vector__XXX
 SG_ HMS_parken_nicht_verfuegbar  : 32|1@1+ (1.000000,0.000000) [0.000000|1.000000] "" Vector__XXX
 SG_ HMS_Anforderung_GE  : 33|3@1+ (1.000000,0.000000) [0.000000|7.000000] "" Vector__XXX
 SG_ HMS_Systemstatus  : 36|4@1+ (1.000000,0.000000) [0.000000|15.000000] "" Motor_BEV
 SG_ HMS_Stillstand  : 40|3@1+ (1.000000,0.000000) [0.000000|7.000000] "" Motor_BEV
 SG_ HMS_aktives_System  : 43|5@1+ (1.000000,0.000000) [0.000000|31.000000] "" Motor_BEV
 SG_ VMM_Inkonsistenz_GE  : 48|1@1+ (1.000000,0.000000) [0.000000|1.000000] "" Motor_BEV
 SG_ VMM_Inkonsistenz_HVLM  : 49|1@1+ (1.000000,0.000000) [0.000000|1.000000] "" Motor_BEV
 SG_ HMS_Fehlerstatus  : 50|3@1+ (1.000000,0.000000) [0.000000|7.000000] "" Vector__XXX
 SG_ HMS_Index_Haltemoment  : 53|1@1+ (1.000000,0.000000) [0.000000|1.000000] "" Motor_BEV
 SG_ HMS_Haltemoment  : 54|10@1+ (10.000000,0.000000) [0.000000|10210.000000] "Unit_NewtoMeter" Motor_BEV

BO_ 313 VMM_02: 32 ICAS1_Gateway
 SG_ VMM_02_CRC  : 0|8@1+ (1.000000,0.000000) [0.000000|255.000000] "" Motor_BEV
 SG_ VMM_02_BZ  : 8|4@1+ (1.000000,0.000000) [0.000000|15.000000] "" Motor_BEV
 SG_ VZM_aktiver_Basisservice  : 12|3@1+ (1.000000,0.000000) [0.000000|7.000000] "" Motor_BEV
 SG_ VZM_Anhalteweg_nicht_verfuegbar  : 15|1@1+ (1.000000,0.000000) [0.000000|1.000000] "" Motor_BEV
 SG_ VZM_Fahrer_bremst  : 16|1@1+ (1.000000,0.000000) [0.000000|1.000000] "" Motor_BEV
 SG_ VZM_QBit_Fahrer_bremst  : 17|1@1+ (1.000000,0.000000) [0.000000|1.000000] "" Motor_BEV
 SG_ VMM_MKB_codiert  : 18|1@1+ (1.000000,0.000000) [0.000000|1.000000] "" Airbag
 SG_ VMM_Inkonsistenz_EBKV  : 19|1@1+ (1.000000,0.000000) [0.000000|1.000000] "" Vector__XXX
 SG_ VMM_Notstopp_Status  : 20|3@1+ (1.000000,0.000000) [0.000000|7.000000] "" Motor_BEV
 SG_ VZM_Warnruck_nicht_verfuegbar  : 23|1@1+ (1.000000,0.000000) [0.000000|1.000000] "" Motor_BEV
 SG_ VZM_Warnruckeln_nicht_verfuegbar  : 24|1@1+ (1.000000,0.000000) [0.000000|1.000000] "" Motor_BEV
 SG_ VZM_Bkd_nicht_verfuegbar  : 25|1@1+ (1.000000,0.000000) [0.000000|1.000000] "" Motor_BEV
 SG_ VMM_Bremslicht_defekt  : 26|1@1+ (1.000000,0.000000) [0.000000|1.000000] "" Motor_BEV
 SG_ VZM_Fahrer_bremst_deutlich  : 27|1@1+ (1.000000,0.000000) [0.000000|1.000000] "" Airbag Motor_BEV
 SG_ VZM_TSK_SRBM_Anf  : 28|1@1+ (1.000000,0.000000) [0.000000|1.000000] "" Motor_BEV
 SG_ VZM_TSK_SRBM_nicht_verfuegbar  : 29|1@1+ (1.000000,0.000000) [0.000000|1.000000] "" Motor_BEV
 SG_ VZM_Verz_Reg_aktiv  : 30|5@1+ (1.000000,0.000000) [0.000000|31.000000] "" Motor_BEV
 SG_ VZM_Verz_Reg_nicht_verfuegbar  : 35|1@1+ (1.000000,0.000000) [0.000000|1.000000] "" Motor_BEV
 SG_ VMM_Inkonsistenz_KAS  : 36|1@1+ (1.000000,0.000000) [0.000000|1.000000] "" Motor_BEV
 SG_ VMM_Bremslicht_unplausibel  : 37|1@1+ (1.000000,0.000000) [0.000000|1.000000] "" Motor_BEV
 SG_ VMM_Inkonsistenz_ACC  : 38|1@1+ (1.000000,0.000000) [0.000000|1.000000] "" Motor_BEV
 SG_ VMM_Inkonsistenz_AWV_PCF  : 39|1@1+ (1.000000,0.000000) [0.000000|1.000000] "" Motor_BEV
 SG_ VMM_Inkonsistenz_ARA  : 40|1@1+ (1.000000,0.000000) [0.000000|1.000000] "" Motor_BEV
 SG_ VMM_Inkonsistenz_ParkAssist  : 41|1@1+ (1.000000,0.000000) [0.000000|1.000000] "" Motor_BEV
 SG_ VMM_Inkonsistenz_FAS_VK  : 42|1@1+ (1.000000,0.000000) [0.000000|1.000000] "" Motor_BEV
 SG_ VMM_Inkonsistenz_NV  : 43|1@1+ (1.000000,0.000000) [0.000000|1.000000] "" Motor_BEV
 SG_ VMM_Inkonsistenz_RCTA  : 44|1@1+ (1.000000,0.000000) [0.000000|1.000000] "" Motor_BEV
 SG_ VMM_Inkonsistenz_TSK  : 45|1@1+ (1.000000,0.000000) [0.000000|1.000000] "" Motor_BEV
 SG_ VMM_Inkonsistenz_MO  : 46|1@1+ (1.000000,0.000000) [0.000000|1.000000] "" Motor_BEV
 SG_ VMM_Inkonsistenz_AEB  : 47|1@1+ (1.000000,0.000000) [0.000000|1.000000] "" Vector__XXX
 SG_ VMM_Fahrer_Bremskraft_bestimmend  : 48|1@1+ (1.000000,0.000000) [0.000000|1.000000] "" Motor_BEV
 SG_ VMM_Inkonsistenz_EA  : 49|1@1+ (1.000000,0.000000) [0.000000|1.000000] "" Motor_BEV
 SG_ VZM_Status_Wegregelung  : 50|2@1+ (1.000000,0.000000) [0.000000|3.000000] "" Motor_BEV
 SG_ VZM_Verz_ASIL_Verfuegbarkeit  : 52|3@1+ (1.000000,0.000000) [0.000000|7.000000] "" Motor_BEV
 SG_ VZM_aktives_System  : 55|5@1+ (1.000000,0.000000) [0.000000|31.000000] "" Airbag Motor_BEV
 SG_ VZM_Verz_Begrenzung  : 60|1@1+ (1.000000,0.000000) [0.000000|1.000000] "" Motor_BEV
 SG_ VZM_Systemstatus  : 61|3@1+ (1.000000,0.000000) [0.000000|7.000000] "" Motor_BEV
 SG_ VZM_SRBM_Soll  : 64|12@1+ (8.000000,0.000000) [0.000000|32744.000000] "Unit_NewtoMeter" Motor_BEV
 SG_ VZM_SRBM_Ist  : 76|12@1+ (8.000000,0.000000) [0.000000|32744.000000] "Unit_NewtoMeter" Motor_BEV
 SG_ VZM_SRBM_max_Gradient  : 88|7@1+ (50.000000,0.000000) [0.000000|6250.000000] "Unit_NewtoMeterPerSecon" Motor_BEV
 SG_ VMM_Inkonsistenz_KAM  : 95|1@1+ (1.000000,0.000000) [0.000000|1.000000] "" Vector__XXX

BO_ 2463978663 VZE_04: 32 ICAS1_Gateway
 SG_ VZE_Anzeigemodus  : 0|2@1+ (1.000000,0.000000) [0.000000|3.000000] "" Vector__XXX
 SG_ VZE_Hinweistext  : 2|3@1+ (1.000000,0.000000) [1.000000|7.000000] "" Motor_BEV
 SG_ VZE_Verkehrszeichen_Einheit  : 8|1@1+ (1.000000,0.000000) [0.000000|1.000000] "" Vector__XXX
 SG_ VZE_Anzeigeunterdrueck_Zeichen_3  : 9|1@1+ (1.000000,0.000000) [0.000000|1.000000] "" Vector__XXX
 SG_ VZE_Anzeigeunterdrueck_Zeichen_2  : 10|1@1+ (1.000000,0.000000) [0.000000|1.000000] "" Vector__XXX
 SG_ VZE_Verkehrszeichen_1  : 11|8@1+ (1.000000,0.000000) [1.000000|255.000000] "" Motor_BEV
 SG_ VZE_Verkehrszeichen_2  : 19|8@1+ (1.000000,0.000000) [1.000000|255.000000] "" Vector__XXX
 SG_ VZE_Verkehrszeichen_3  : 27|8@1+ (1.000000,0.000000) [1.000000|255.000000] "" Vector__XXX
 SG_ VZE_Warnung_Verkehrszeichen_1  : 35|1@1+ (1.000000,0.000000) [0.000000|1.000000] "" Vector__XXX
 SG_ VZE_Warnung_Verkehrszeichen_2  : 36|1@1+ (1.000000,0.000000) [0.000000|1.000000] "" Vector__XXX
 SG_ VZE_Warnung_Verkehrszeichen_3  : 37|1@1+ (1.000000,0.000000) [0.000000|1.000000] "" Vector__XXX
 SG_ VZE_Zusatzschild_1  : 38|4@1+ (1.000000,0.000000) [1.000000|15.000000] "" Vector__XXX
 SG_ VZE_Zusatzschild_2  : 42|4@1+ (1.000000,0.000000) [1.000000|15.000000] "" Vector__XXX
 SG_ VZE_Zusatzschild_3  : 46|4@1+ (1.000000,0.000000) [1.000000|15.000000] "" Vector__XXX
 SG_ VZE_Anzeigeunterdrueck_Zeichen_1  : 50|1@1+ (1.000000,0.000000) [0.000000|1.000000] "" Vector__XXX
 SG_ VZE_Zeichen_01_KameraWied  : 51|1@1+ (1.000000,0.000000) [0.000000|1.000000] "" Motor_BEV
 SG_ VZE_Zeichen_02_KameraWied  : 52|1@1+ (1.000000,0.000000) [0.000000|1.000000] "" Vector__XXX
 SG_ VZE_Zeichen_03_KameraWied  : 53|1@1+ (1.000000,0.000000) [0.000000|1.000000] "" Vector__XXX
 SG_ VZE_Zeichen_01_Kamera  : 54|1@1+ (1.000000,0.000000) [0.000000|1.000000] "" Motor_BEV
 SG_ VZE_Zeichen_01_Karte  : 55|1@1+ (1.000000,0.000000) [0.000000|1.000000] "" Vector__XXX
 SG_ VZE_Zeichen_01_Gesetz  : 56|1@1+ (1.000000,0.000000) [0.000000|1.000000] "" Vector__XXX
 SG_ VZE_Zeichen_02_Kamera  : 57|1@1+ (1.000000,0.000000) [0.000000|1.000000] "" Vector__XXX
 SG_ VZE_Zeichen_02_Karte  : 58|1@1+ (1.000000,0.000000) [0.000000|1.000000] "" Vector__XXX
 SG_ VZE_Zeichen_02_Gesetz  : 59|1@1+ (1.000000,0.000000) [0.000000|1.000000] "" Vector__XXX
 SG_ VZE_Zeichen_03_Kamera  : 60|1@1+ (1.000000,0.000000) [0.000000|1.000000] "" Vector__XXX
 SG_ VZE_Zeichen_03_Karte  : 61|1@1+ (1.000000,0.000000) [0.000000|1.000000] "" Vector__XXX
 SG_ VZE_Zeichen_03_Gesetz  : 62|1@1+ (1.000000,0.000000) [0.000000|1.000000] "" Vector__XXX
 SG_ VZE_Gong  : 63|1@1+ (1.000000,0.000000) [0.000000|1.000000] "" Vector__XXX
 SG_ VZE_Anzeigeunterdrueck_Zeichen_5  : 72|1@1+ (1.000000,0.000000) [0.000000|1.000000] "" Vector__XXX
 SG_ VZE_Zeichen_05_KameraWied  : 73|1@1+ (1.000000,0.000000) [0.000000|1.000000] "" Vector__XXX
 SG_ VZE_Zeichen_05_Kamera  : 74|1@1+ (1.000000,0.000000) [0.000000|1.000000] "" Vector__XXX
 SG_ VZE_Verkehrszeichen_4  : 75|8@1+ (1.000000,0.000000) [1.000000|255.000000] "" Motor_BEV
 SG_ VZE_Verkehrszeichen_5  : 83|8@1+ (1.000000,0.000000) [1.000000|255.000000] "" Motor_BEV
 SG_ VZE_Anhaenger_Vmax  : 91|4@1+ (10.000000,10.000000) [10.000000|140.000000] "Unit_KiloMeterPerHour" Vector__XXX
 SG_ VZE_Zeichen_04_Gesetz  : 95|1@1+ (1.000000,0.000000) [0.000000|1.000000] "" Vector__XXX
 SG_ VZE_Zeichen_04_Kamera  : 96|1@1+ (1.000000,0.000000) [0.000000|1.000000] "" Vector__XXX
 SG_ VZE_Zeichen_04_KameraWied  : 97|1@1+ (1.000000,0.000000) [0.000000|1.000000] "" Vector__XXX
 SG_ VZE_Zeichen_04_Karte  : 98|1@1+ (1.000000,0.000000) [0.000000|1.000000] "" Vector__XXX
 SG_ VZE_Warnung_Verkehrszeichen_4  : 99|1@1+ (1.000000,0.000000) [0.000000|1.000000] "" Vector__XXX
 SG_ VZE_Warnung_Verkehrszeichen_5  : 100|1@1+ (1.000000,0.000000) [0.000000|1.000000] "" Vector__XXX
 SG_ VZE_Zeichen_05_Gesetz  : 101|1@1+ (1.000000,0.000000) [0.000000|1.000000] "" Vector__XXX
 SG_ VZE_Zusatzschild_4  : 102|4@1+ (1.000000,0.000000) [1.000000|15.000000] "" Vector__XXX
 SG_ VZE_Zusatzschild_5  : 106|4@1+ (1.000000,0.000000) [1.000000|15.000000] "" Vector__XXX
 SG_ VZE_Baustelle  : 110|2@1+ (1.000000,0.000000) [0.000000|3.000000] "" Vector__XXX
 SG_ VZE_Zeichen_05_Karte  : 112|1@1+ (1.000000,0.000000) [0.000000|1.000000] "" Vector__XXX
 SG_ VZE_Zeichen_05_Entfernung  : 113|7@1+ (1.000000,0.000000) [1.000000|127.000000] "Unit_Meter" Motor_BEV
 SG_ VZE_Zeichen_05_Entfernung_StdA  : 120|7@1+ (1.000000,0.000000) [1.000000|127.000000] "Unit_Meter" Motor_BEV
 SG_ VZE_Anzeigeunterdrueck_Zeichen_4  : 127|1@1+ (1.000000,0.000000) [0.000000|1.000000] "" Vector__XXX
 SG_ VZE_Verkehrszeichen_6  : 128|8@1+ (1.000000,0.000000) [1.000000|255.000000] "Unit_None" Motor_BEV
 SG_ VZE_Zusatzschild_6  : 136|4@1+ (1.000000,0.000000) [1.000000|15.000000] "" Vector__XXX
 SG_ VZE_Zeichen_06_Entfernung  : 140|7@1+ (1.000000,0.000000) [1.000000|127.000000] "Unit_Meter" Motor_BEV
 SG_ VZE_Zeichen_06_Entfernung_StdA  : 147|7@1+ (1.000000,0.000000) [1.000000|127.000000] "Unit_Meter" Motor_BEV
 SG_ VZE_Umweltinfo_Naesse  : 154|1@1+ (1.000000,0.000000) [0.000000|1.000000] "" Motor_BEV
 SG_ VZE_Umweltinfo_Nebel  : 155|1@1+ (1.000000,0.000000) [0.000000|1.000000] "" Motor_BEV
 SG_ VZE_Umweltinfo_Anhaengerbetrieb  : 156|1@1+ (1.000000,0.000000) [0.000000|1.000000] "" Vector__XXX
 SG_ VZE_Erweiterte_Information  : 157|8@1+ (1.000000,0.000000) [1.000000|255.000000] "Unit_None" Vector__XXX
 SG_ VZE_Tempowarnung_Status  : 165|1@1+ (1.000000,0.000000) [0.000000|1.000000] "" Vector__XXX
 SG_ VZE_Tempowarnung_Einheit  : 166|1@1+ (1.000000,0.000000) [0.000000|1.000000] "" Vector__XXX
 SG_ VZE_Tempowarnung_Offset  : 167|5@1+ (1.000000,0.000000) [1.000000|31.000000] "" Vector__XXX
 SG_ VZE_FoD_Status  : 206|2@1+ (1.000000,0.000000) [0.000000|3.000000] "" Vector__XXX
 SG_ VZE_Anzeige_ZS_1  : 208|4@1+ (1.000000,0.000000) [1.000000|15.000000] "Unit_None" Vector__XXX
 SG_ VZE_Anzeige_ZS_2  : 212|4@1+ (1.000000,0.000000) [1.000000|15.000000] "Unit_None" Vector__XXX
 SG_ VZE_Anzeige_ZS_3  : 216|4@1+ (1.000000,0.000000) [1.000000|15.000000] "Unit_None" Vector__XXX
 SG_ VZE_Hinweistext_03  : 220|4@1+ (1.000000,0.000000) [1.000000|15.000000] "" Vector__XXX
 SG_ VZE_Land  : 224|5@1+ (1.000000,0.000000) [1.000000|31.000000] "" Vector__XXX
 SG_ VZE_Warnung_VZ_1  : 229|1@1+ (1.000000,0.000000) [0.000000|1.000000] "" Vector__XXX
 SG_ VZE_Warnung_VZ_2  : 230|1@1+ (1.000000,0.000000) [0.000000|1.000000] "" Vector__XXX
 SG_ VZE_Warnung_VZ_3  : 231|1@1+ (1.000000,0.000000) [0.000000|1.000000] "" Vector__XXX
 SG_ VZE_Anzeige_VZ_1  : 232|8@1+ (1.000000,0.000000) [1.000000|255.000000] "" Vector__XXX
 SG_ VZE_Anzeige_VZ_2  : 240|8@1+ (1.000000,0.000000) [1.000000|255.000000] "Unit_None" Vector__XXX
 SG_ VZE_Anzeige_VZ_3  : 248|8@1+ (1.000000,0.000000) [1.000000|255.000000] "Unit_None" Vector__XXX

BO_ 181 Waehlhebel_04: 8 ICAS1_Gateway
 SG_ Waehlhebel_04_CRC  : 0|8@1+ (1.000000,0.000000) [0.000000|255.000000] "" Motor_BEV
 SG_ Waehlhebel_04_BZ  : 8|4@1+ (1.000000,0.000000) [0.000000|15.000000] "" Motor_BEV
 SG_ WH_gespeicherte_Fahrstufe  : 12|3@1+ (1.000000,0.000000) [0.000000|7.000000] "" Vector__XXX
 SG_ WH_Initialisierung  : 15|1@1+ (1.000000,0.000000) [0.000000|1.000000] "" Motor_BEV
 SG_ WH_SensorPos_roh  : 16|4@1+ (1.000000,0.000000) [0.000000|15.000000] "" Motor_BEV
 SG_ WH_SensorPos_roh_inv  : 20|4@1+ (1.000000,0.000000) [0.000000|15.000000] "" Motor_BEV
 SG_ WH_Testergebnis  : 24|8@1+ (1.000000,0.000000) [0.000000|255.000000] "" Vector__XXX
 SG_ WH_Test_Aktiv  : 32|1@1+ (1.000000,0.000000) [0.000000|1.000000] "" Vector__XXX
 SG_ WH_Ist_Haltemagnet  : 33|2@1+ (1.000000,0.000000) [0.000000|3.000000] "" Motor_BEV
 SG_ WH_Variante  : 35|4@1+ (1.000000,0.000000) [0.000000|15.000000] "" Motor_BEV
 SG_ WH_Entsperrtaste_02  : 39|2@1+ (1.000000,0.000000) [0.000000|3.000000] "" Motor_BEV
 SG_ WH_P_Taste  : 41|2@1+ (1.000000,0.000000) [0.000000|3.000000] "" Motor_BEV
 SG_ WH_Ende_N_Haltephase  : 43|1@1+ (1.000000,0.000000) [0.000000|1.000000] "" Vector__XXX
 SG_ WH_Fahrstufe  : 44|4@1+ (1.000000,0.000000) [0.000000|15.000000] "" Motor_BEV
 SG_ WH_Status_Shiftlock  : 48|3@1+ (1.000000,0.000000) [0.000000|7.000000] "" Motor_BEV
 SG_ WH_Zustand_N_Haltephase  : 51|2@1+ (1.000000,0.000000) [0.000000|3.000000] "" Vector__XXX

BO_ 2463978687 Waehlhebel_06: 8 ICAS1_Gateway
 SG_ WH_Fehler_Haltemagnet_Status  : 41|1@1+ (1.000000,0.000000) [0.000000|1.000000] "" Motor_BEV
 SG_ WH_Fehler_CRC_SBM  : 42|1@1+ (1.000000,0.000000) [0.000000|1.000000] "" Motor_BEV
 SG_ WH_Fehler_CRC_SBM_Status  : 43|1@1+ (1.000000,0.000000) [0.000000|1.000000] "" Motor_BEV
 SG_ WH_Fehler_Timeout_SBM  : 44|1@1+ (1.000000,0.000000) [0.000000|1.000000] "" Motor_BEV
 SG_ WH_Fehler_Timeout_SBM_Status  : 45|1@1+ (1.000000,0.000000) [0.000000|1.000000] "" Motor_BEV
 SG_ WH_Fehler_Ueberspannung  : 46|1@1+ (1.000000,0.000000) [0.000000|1.000000] "" Motor_BEV
 SG_ WH_Fehler_Ueberspannung_Status  : 47|1@1+ (1.000000,0.000000) [0.000000|1.000000] "" Motor_BEV
 SG_ WH_Fehler_BZ_SBM  : 48|1@1+ (1.000000,0.000000) [0.000000|1.000000] "" Motor_BEV
 SG_ WH_Fehler_BZ_SBM_Status  : 49|1@1+ (1.000000,0.000000) [0.000000|1.000000] "" Motor_BEV
 SG_ WH_Fehler_Unterspannung  : 50|1@1+ (1.000000,0.000000) [0.000000|1.000000] "" Motor_BEV
 SG_ WH_Fehler_Unterspannung_Status  : 51|1@1+ (1.000000,0.000000) [0.000000|1.000000] "" Motor_BEV
 SG_ WH_Fehler_Ausleuchtung  : 52|1@1+ (1.000000,0.000000) [0.000000|1.000000] "" Motor_BEV
 SG_ WH_Fehler_Ausleuchtung_Status  : 53|1@1+ (1.000000,0.000000) [0.000000|1.000000] "" Motor_BEV
 SG_ WH_Fehler_Entsperrtaste  : 54|1@1+ (1.000000,0.000000) [0.000000|1.000000] "" Motor_BEV
 SG_ WH_Fehler_Entsperrtaste_Status  : 55|1@1+ (1.000000,0.000000) [0.000000|1.000000] "" Motor_BEV
 SG_ WH_Fehler_P_Taste  : 56|1@1+ (1.000000,0.000000) [0.000000|1.000000] "" Motor_BEV
 SG_ WH_Fehler_P_Taste_Status  : 57|1@1+ (1.000000,0.000000) [0.000000|1.000000] "" Motor_BEV
 SG_ WH_Fehler_Sensor_einfach  : 58|1@1+ (1.000000,0.000000) [0.000000|1.000000] "" Motor_BEV
 SG_ WH_Fehler_Sensor_einfach_Status  : 59|1@1+ (1.000000,0.000000) [0.000000|1.000000] "" Motor_BEV
 SG_ WH_Fehler_Sensor_mehrfach  : 60|1@1+ (1.000000,0.000000) [0.000000|1.000000] "" Motor_BEV
 SG_ WH_Fehler_Sensor_mehrfach_Status  : 61|1@1+ (1.000000,0.000000) [0.000000|1.000000] "" Motor_BEV
 SG_ WH_Fehler_Shiftlock  : 62|1@1+ (1.000000,0.000000) [0.000000|1.000000] "" Motor_BEV
 SG_ WH_Fehler_Shiftlock_Status  : 63|1@1+ (1.000000,0.000000) [0.000000|1.000000] "" Motor_BEV

BO_ 916 WBA_03: 8 Motor_BEV
 SG_ WBA_03_CRC  : 0|8@1+ (1.000000,0.000000) [0.000000|255.000000] "" ICAS1_Gateway
 SG_ WBA_03_BZ  : 8|4@1+ (1.000000,0.000000) [0.000000|15.000000] "" ICAS1_Gateway
 SG_ WBA_Fahrstufe_02  : 12|4@1+ (1.000000,0.000000) [0.000000|15.000000] "" ICAS1_Gateway ICAS1_KommunikationsServer
 SG_ WBA_ZielFahrstufe  : 16|4@1+ (1.000000,0.000000) [0.000000|15.000000] "" ICAS1_Gateway
 SG_ WBA_GE_Warnung_02  : 20|4@1+ (1.000000,0.000000) [0.000000|15.000000] "" ICAS1_Gateway
 SG_ WBA_eing_Gang_02  : 24|4@1+ (1.000000,0.000000) [0.000000|15.000000] "" ICAS1_Gateway
 SG_ WBA_GE_Texte  : 28|3@1+ (1.000000,0.000000) [0.000000|7.000000] "" ICAS1_Gateway
 SG_ WBA_Segeln_aktiv  : 31|1@1+ (1.000000,0.000000) [0.000000|1.000000] "" ICAS1_Gateway
 SG_ WBA_Schaltschema_02  : 32|3@1+ (1.000000,0.000000) [0.000000|7.000000] "" ICAS1_Gateway
 SG_ WBA_Schaltschema_FS_inaktiv  : 35|2@1+ (1.000000,0.000000) [0.000000|3.000000] "" ICAS1_Gateway
 SG_ WBA_GE_Zusatzwarnungen  : 37|3@1+ (1.000000,0.000000) [0.000000|7.000000] "" ICAS1_Gateway
 SG_ GE_Sollgang  : 40|4@1+ (1.000000,0.000000) [0.000000|15.000000] "" ICAS1_Gateway
 SG_ GE_Tipschaltempf_verfuegbar  : 44|1@1+ (1.000000,0.000000) [0.000000|1.000000] "" ICAS1_Gateway
 SG_ WBA_GE_Texte_02  : 45|3@1+ (1.000000,0.000000) [0.000000|7.000000] "" ICAS1_Gateway
 SG_ WBA_Schaltschema_Tippgasse  : 48|1@1+ (1.000000,0.000000) [0.000000|1.000000] "" ICAS1_Gateway
 SG_ WBA_Schaltschema_Fahreraktion  : 49|1@1+ (1.000000,0.000000) [0.000000|1.000000] "" ICAS1_Gateway
 SG_ WBA_Schaltschema_FS_vorwaerts  : 50|2@1+ (1.000000,0.000000) [0.000000|3.000000] "" ICAS1_Gateway
 SG_ WBA_Shiftlock_Lampe  : 52|1@1+ (1.000000,0.000000) [0.000000|1.000000] "" ICAS1_Gateway
 SG_ WBA_Anforderung_Akustik  : 53|1@1+ (1.000000,0.000000) [0.000000|1.000000] "" ICAS1_Gateway
 SG_ WBA_Blinken  : 54|1@1+ (1.000000,0.000000) [0.000000|1.000000] "" ICAS1_Gateway
 SG_ GE_Wiederstart_Anz_Std  : 55|1@1+ (1.000000,0.000000) [0.000000|1.000000] "" ICAS1_Gateway
 SG_ GE_Stoppverbot_Anz_01  : 56|1@1+ (1.000000,0.000000) [0.000000|1.000000] "" ICAS1_Gateway
 SG_ GE_Stoppverbot_Anz_02  : 57|1@1+ (1.000000,0.000000) [0.000000|1.000000] "" ICAS1_Gateway
 SG_ GE_Stoppverbot_Anz_03  : 58|1@1+ (1.000000,0.000000) [0.000000|1.000000] "" ICAS1_Gateway
 SG_ GE_Stoppverbot_Anz_04  : 59|1@1+ (1.000000,0.000000) [0.000000|1.000000] "" ICAS1_Gateway
 SG_ GE_Stoppverbot_Anz_05  : 60|1@1+ (1.000000,0.000000) [0.000000|1.000000] "" ICAS1_Gateway
 SG_ GE_Stoppverbot_Anz_06  : 61|1@1+ (1.000000,0.000000) [0.000000|1.000000] "" ICAS1_Gateway
 SG_ GE_Stoppverbot_Anz_07  : 62|1@1+ (1.000000,0.000000) [0.000000|1.000000] "" ICAS1_Gateway
 SG_ GE_Stoppverbot_Anz_Std  : 63|1@1+ (1.000000,0.000000) [0.000000|1.000000] "" ICAS1_Gateway

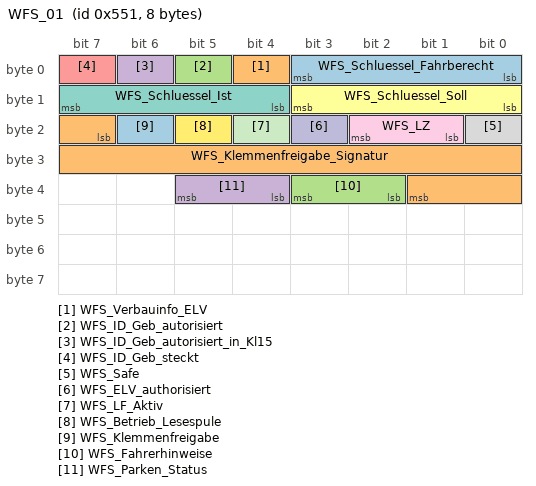
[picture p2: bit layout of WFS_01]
BO_ 1361 WFS_01: 8 ICAS1_Gateway
 SG_ WFS_Schluessel_Fahrberecht  : 0|4@1+ (1.000000,0.000000) [0.000000|15.000000] "" Vector__XXX
 SG_ WFS_Verbauinfo_ELV  : 4|1@1+ (1.000000,0.000000) [0.000000|1.000000] "" Vector__XXX
 SG_ WFS_ID_Geb_autorisiert  : 5|1@1+ (1.000000,0.000000) [0.000000|1.000000] "" Vector__XXX
 SG_ WFS_ID_Geb_autorisiert_in_Kl15  : 6|1@1+ (1.000000,0.000000) [0.000000|1.000000] "" Vector__XXX
 SG_ WFS_ID_Geb_steckt  : 7|1@1+ (1.000000,0.000000) [0.000000|1.000000] "" Vector__XXX
 SG_ WFS_Schluessel_Soll  : 8|4@1+ (1.000000,0.000000) [0.000000|15.000000] "" Vector__XXX
 SG_ WFS_Schluessel_Ist  : 12|4@1+ (1.000000,0.000000) [0.000000|15.000000] "" Vector__XXX
 SG_ WFS_Safe  : 16|1@1+ (1.000000,0.000000) [0.000000|1.000000] "" Vector__XXX
 SG_ WFS_LZ  : 17|2@1+ (1.000000,0.000000) [0.000000|3.000000] "" Vector__XXX
 SG_ WFS_ELV_authorisiert  : 19|1@1+ (1.000000,0.000000) [0.000000|1.000000] "" Vector__XXX
 SG_ WFS_LF_Aktiv  : 20|1@1+ (1.000000,0.000000) [0.000000|1.000000] "" Vector__XXX
 SG_ WFS_Betrieb_Lesespule  : 21|1@1+ (1.000000,0.000000) [0.000000|1.000000] "" Vector__XXX
 SG_ WFS_Klemmenfreigabe  : 22|1@1+ (1.000000,0.000000) [0.000000|1.000000] "" Motor_BEV
 SG_ WFS_Klemmenfreigabe_Signatur  : 23|11@1+ (1.000000,0.000000) [0.000000|2047.000000] "" Vector__XXX
 SG_ WFS_Fahrerhinweise  : 34|2@1+ (1.000000,0.000000) [0.000000|3.000000] "" Vector__XXX
 SG_ WFS_Parken_Status  : 36|2@1+ (1.000000,0.000000) [0.000000|3.000000] "" Vector__XXX

BO_ 2617028096 XCP_Airbag_CRO_01: 64 Vector__XXX
 SG_ XCP_Airbag_CRO_01_Data  : 0|512@1+ (1.000000,0.000000) [0.000000|13407807929942597099574024998205846127479365820592393377723561443721764030073546976801874298166903427690031858186486050853753882811946569946433649006084096.000000] "" Airbag

BO_ 2617028097 XCP_Airbag_DTO_01: 64 Airbag
 SG_ XCP_Airbag_DTO_01_Data  : 0|512@1+ (1.000000,0.000000) [0.000000|13407807929942597099574024998205846127479365820592393377723561443721764030073546976801874298166903427690031858186486050853753882811946569946433649006084096.000000] "" Vector__XXX

BO_ 2617239040 XCP_EMotor_01_CRO_01: 64 Vector__XXX
 SG_ XCP_EMotor_01_CRO_01_Data  : 0|64@1+ (1.000000,0.000000) [0.000000|18446744073709551616.000000] "" LE1

BO_ 2617239041 XCP_EMotor_01_DTO_01: 64 LE1
 SG_ XCP_EMotor_01_DTO_01_Data  : 0|64@1+ (1.000000,0.000000) [0.000000|18446744073709551616.000000] "" Vector__XXX

BO_ 2617239042 XCP_EMotor_01_DTO_02: 64 LE1
 SG_ XCP_EMotor_01_DTO_02_Data  : 0|64@1+ (1.000000,0.000000) [0.000000|18446744073709551616.000000] "" Vector__XXX

BO_ 2617239043 XCP_EMotor_01_DTO_03: 64 LE1
 SG_ XCP_EMotor_01_DTO_03_Data  : 0|64@1+ (1.000000,0.000000) [0.000000|18446744073709551616.000000] "" Vector__XXX

BO_ 2617239044 XCP_EMotor_01_DTO_04: 64 LE1
 SG_ XCP_EMotor_01_DTO_04_Data  : 0|64@1+ (1.000000,0.000000) [0.000000|18446744073709551616.000000] "" Vector__XXX

BO_ 2617122304 XCP_EMotor_02_CRO_01: 64 Vector__XXX
 SG_ XCP_EMotor_02_CRO_01_Data  : 0|64@1+ (1.000000,0.000000) [0.000000|18446744073709551616.000000] "" LE2

BO_ 2617122305 XCP_EMotor_02_DTO_01: 64 LE2
 SG_ XCP_EMotor_02_DTO_01_Data  : 0|64@1+ (1.000000,0.000000) [0.000000|18446744073709551616.000000] "" Vector__XXX

BO_ 2617122306 XCP_EMotor_02_DTO_02: 64 LE2
 SG_ XCP_EMotor_02_DTO_02_Data  : 0|64@1+ (1.000000,0.000000) [0.000000|18446744073709551616.000000] "" Vector__XXX

BO_ 2617122307 XCP_EMotor_02_DTO_03: 64 LE2
 SG_ XCP_EMotor_02_DTO_03_Data  : 0|64@1+ (1.000000,0.000000) [0.000000|18446744073709551616.000000] "" Vector__XXX

BO_ 2617122308 XCP_EMotor_02_DTO_04: 64 LE2
 SG_ XCP_EMotor_02_DTO_04_Data  : 0|64@1+ (1.000000,0.000000) [0.000000|18446744073709551616.000000] "" Vector__XXX

BO_ 2617226768 XCP_Motor_CRO_01: 64 Vector__XXX
 SG_ XCP_Motor_CRO_01_Data  : 0|64@1+ (1.000000,0.000000) [0.000000|18446744073709551616.000000] "" Motor_BEV

BO_ 2617226769 XCP_Motor_DTO_01: 64 Motor_BEV
 SG_ XCP_Motor_DTO_01_Data  : 0|64@1+ (1.000000,0.000000) [0.000000|18446744073709551616.000000] "" Vector__XXX

BO_ 1411 ZV_02: 8 ICAS1_Gateway
 SG_ ZV_verriegeln_Anf  : 0|1@1+ (1.000000,0.000000) [0.000000|1.000000] "" Vector__XXX
 SG_ ZV_STSG_HFS_Anf  : 1|1@1+ (1.000000,0.000000) [0.000000|1.000000] "" Vector__XXX
 SG_ ZV_STSG_HBFS_Anf  : 2|1@1+ (1.000000,0.000000) [0.000000|1.000000] "" Vector__XXX
 SG_ ZV_Anf_Challenge_Auth  : 3|1@1+ (1.000000,0.000000) [0.000000|1.000000] "" Vector__XXX
 SG_ BCM_FH_Freigabe  : 12|1@1+ (1.000000,0.000000) [0.000000|1.000000] "" Vector__XXX
 SG_ BCM_Komfortfkt_Freigabe  : 13|1@1+ (1.000000,0.000000) [0.000000|1.000000] "" Vector__XXX
 SG_ BCM_HSK_Freigabe  : 14|1@1+ (1.000000,0.000000) [0.000000|1.000000] "" Vector__XXX
 SG_ BCM_Verdeck_Freigabe  : 15|1@1+ (1.000000,0.000000) [0.000000|1.000000] "" Vector__XXX
 SG_ ZV_verriegelt_intern_ist  : 16|1@1+ (1.000000,0.000000) [0.000000|1.000000] "" Vector__XXX
 SG_ ZV_verriegelt_extern_ist  : 17|1@1+ (1.000000,0.000000) [0.000000|1.000000] "" Airbag
 SG_ ZV_verriegelt_intern_soll  : 18|1@1+ (1.000000,0.000000) [0.000000|1.000000] "" Vector__XXX
 SG_ ZV_verriegelt_extern_soll  : 19|1@1+ (1.000000,0.000000) [0.000000|1.000000] "" Airbag
 SG_ ZV_gesafet_extern_ist  : 20|1@1+ (1.000000,0.000000) [0.000000|1.000000] "" Vector__XXX
 SG_ ZV_gesafet_extern_soll  : 21|1@1+ (1.000000,0.000000) [0.000000|1.000000] "" Vector__XXX
 SG_ ZV_Einzeltuerentriegelung  : 22|1@1+ (1.000000,0.000000) [0.000000|1.000000] "" Vector__XXX
 SG_ ZV_Heckeinzelentriegelung  : 23|1@1+ (1.000000,0.000000) [0.000000|1.000000] "" Vector__XXX
 SG_ ZV_FT_offen  : 24|1@1+ (1.000000,0.000000) [0.000000|1.000000] "" Motor_BEV
 SG_ ZV_BT_offen  : 25|1@1+ (1.000000,0.000000) [0.000000|1.000000] "" Motor_BEV
 SG_ ZV_HFS_offen  : 26|1@1+ (1.000000,0.000000) [0.000000|1.000000] "" Motor_BEV
 SG_ ZV_HBFS_offen  : 27|1@1+ (1.000000,0.000000) [0.000000|1.000000] "" Motor_BEV
 SG_ ZV_HD_offen  : 28|1@1+ (1.000000,0.000000) [0.000000|1.000000] "" Motor_BEV
 SG_ ZV_HS_offen  : 29|1@1+ (1.000000,0.000000) [0.000000|1.000000] "" Vector__XXX
 SG_ IRUE_aktiv  : 30|1@1+ (1.000000,0.000000) [0.000000|1.000000] "" Vector__XXX
 SG_ DWA_aktiv  : 31|1@1+ (1.000000,0.000000) [0.000000|1.000000] "" Vector__XXX
 SG_ FFB_HDF_Taste  : 34|1@1+ (1.000000,0.000000) [0.000000|1.000000] "" Vector__XXX
 SG_ FFB_Panik_Taste  : 35|1@1+ (1.000000,0.000000) [0.000000|1.000000] "" Vector__XXX
 SG_ FFB_Auf_Taste  : 36|1@1+ (1.000000,0.000000) [0.000000|1.000000] "" Vector__XXX
 SG_ FFB_Zu_Taste  : 37|1@1+ (1.000000,0.000000) [0.000000|1.000000] "" Vector__XXX
 SG_ FFB_CarFinder  : 38|1@1+ (1.000000,0.000000) [0.000000|1.000000] "" Vector__XXX
 SG_ FFB_Komfortoeffnen  : 39|1@1+ (1.000000,0.000000) [0.000000|1.000000] "" Vector__XXX
 SG_ FFB_Komfortschliessen  : 40|1@1+ (1.000000,0.000000) [0.000000|1.000000] "" Vector__XXX
 SG_ FBS_IDG_in_Reichweite  : 41|1@1+ (1.000000,0.000000) [0.000000|1.000000] "" Vector__XXX
 SG_ ZV_Schluessel_Zugang  : 42|4@1+ (1.000000,0.000000) [0.000000|15.000000] "" Vector__XXX
 SG_ ZV_SafeFunktion_aktiv  : 46|1@1+ (1.000000,0.000000) [0.000000|1.000000] "" Vector__XXX
 SG_ FBS_Warn_Schluessel_Batt  : 47|1@1+ (1.000000,0.000000) [0.000000|1.000000] "" Vector__XXX
 SG_ ZV_Oeffnungsmodus  : 48|2@1+ (1.000000,0.000000) [0.000000|3.000000] "" Vector__XXX
 SG_ ZV_ist_Zustand_verfuegbar  : 54|1@1+ (1.000000,0.000000) [0.000000|1.000000] "" Vector__XXX
 SG_ IRUE_Taster_Fkts_LED  : 55|1@1+ (1.000000,0.000000) [0.000000|1.000000] "" Vector__XXX
 SG_ ZV_Tankklappe_offen  : 56|1@1+ (1.000000,0.000000) [0.000000|1.000000] "" Vector__XXX
 SG_ ZV_Rollo_auf  : 57|1@1+ (1.000000,0.000000) [0.000000|1.000000] "" Vector__XXX
 SG_ ZV_Rollo_zu  : 58|1@1+ (1.000000,0.000000) [0.000000|1.000000] "" Vector__XXX
 SG_ ZV_SAD_auf  : 59|1@1+ (1.000000,0.000000) [0.000000|1.000000] "" Vector__XXX
 SG_ ZV_SAD_zu  : 60|1@1+ (1.000000,0.000000) [0.000000|1.000000] "" Vector__XXX
 SG_ ZV_verriegelt_soll  : 62|2@1+ (1.000000,0.000000) [0.000000|3.000000] "" Vector__XXX

CM_ BO_ 980 "AbMQB7.2";
CM_ BO_ 1413 "MQB,MLBevo";
CM_ BO_ 1716 "200msbeiD4undfolgende";
CM_ BO_ 916 "ersetztWBA_02";
CM_ BO_ 2617239042 "abMQB";
CM_ BO_ 2617239043 "abMQB";
CM_ BO_ 2617239044 "abMQB";
CM_ SG_ 319 PreCrash_Charisma_FahrPr "AktuelleingestelltesFahrprogrammderFunktionPreCrash";
CM_ SG_ 319 PreCrash_Charisma_Status "VerfügbarkeitderFunktionPreCrashfürdieAnsteuerungdurchdenCharisma_Koordinator";
CM_ SG_ 319 PreCrash_Schiebedach_schliessen "AnforderungSchiebedachschließendurchdieFunktionPreCrash";
CM_ SG_ 319 PreCrash_Fenster_schliessen "AnforderungSeitenscheibenschließendurchdieFunktionPreCrash";
CM_ SG_ 319 PreCrash_Blinken "SafetyComputerübermitteltBlinkverhaltenbeieinerPreCrash-AuslösungandenBCM2";
CM_ SG_ 319 SC_PreSense_FCWP "MitteilungandasNightVision,aufwelcheArtvonObjekteineWarnungangefordertwird";
CM_ SG_ 319 PreCrash_Tueren_Verriegeln "AnforderungTürenVerriegelndurchdieFunktionPreCrash";
CM_ SG_ 319 PreCrash_FS_Laengsverstellung "AnsteuerungderLaengsverstellungdesFahrersitzesdurchdiePreCrash-Funktionen";
CM_ SG_ 319 PreCrash_Anforderung_AFR "AnforderungenderFunktionPrecrashSeiteanFahrwerksregelung";
CM_ SG_ 319 SC_PreCrash_LED "AnsteuerungLED-LeisteimKombidurchSC";
CM_ SG_ 319 PreCrash_FS_Pneumatik_ansteuern "AnsteuerungdesFahrersitzesdurchdiePreCrash-Funktionen";
CM_ SG_ 319 PreCrash_BFS_Pneumatik_ansteuern "AnsteuerungdesBeifahrersitzesdurchdiePreCrash-Funktionen";
CM_ SG_ 319 PreCrash_Fo_Pneumatik_ansteuern "AnsteuerungderFondsitzedurchdiePreCrash-Funktionen";
CM_ SG_ 319 PreCrash_FS_Sitzlehne_verfahren "AnsteuerungdesFahrersitzesdurchdiePreCrash-Funktionen

Wert 0x06 und 0x07 für vereinfachte Ansteuerung Sitzlehne";
CM_ SG_ 319 PreCrash_BFS_Sitzlehne_verfahren "AnsteuerungdesBeifahrersitzesdurchdiePreCrash-Funktionen

Wert 0x06 und 0x07 für vereinfachte Ansteuerung Sitzlehne";
CM_ SG_ 319 PreCrash_Fo_Sitzlehne_verfahren "AnsteuerungdesFondsitzesdurchdiePreCrash-Funktionen";
CM_ SG_ 319 PreCrash_FS_KSV_verfahren "AnsteuerungderKopfstuetzeFahrerseitedurchdiePreCrash-Funktionen

Signalwert 0x09 für vereinfachte Ansteuerung mit Logik im Sitz-SG (MQB37W)";
CM_ SG_ 319 PreCrash_BFS_KSV_verfahren "AnsteuerungderKopfstuetzeBeifahrerseitedurchdieFunktionPreCrash

Signalwert 0x09 für vereinfachte Ansteuerung mit Logik im Sitz-SG (MQB37W)";
CM_ SG_ 319 PreCrash_Fo_KSV_verfahren "AnsteuerungderKopfstuetzenimFonddurchdiePreCrash-Funktionen";
CM_ SG_ 319 PreCrash_BFS_Laengsverstellung "AnsteuerungderLaengsverstellungdesBeifahrersitzesdurchdiePreCrash-Funktionen";
CM_ SG_ 319 SC_PreCrash_Warnung "SafetyComputerübermitteltWarnungderPreCrashFunktionenanKombi";
CM_ SG_ 319 SC_PreCrash_Texte "SafetyComputerübermitteltSystemstatusderPreCrashFunktionenanKombi";
CM_ SG_ 1122 PSD_Segment_ID "IdentifierdesprädiktivenStreckensegments
";
CM_ SG_ 1122 PSD_Vorgaenger_Segment_ID "AndemStreckensegmentmitdiesemIdentifierschließtsichdasneueSegmentmitderID'PSD_01_Segment_ID'an.
";
CM_ SG_ 1122 PSD_Segmentlaenge "GesamtlängedesprädiktivenStreckensegments";
CM_ SG_ 1122 PSD_Strassenkategorie "KlassifizierungderStraßedesbeschriebenenSegments
";
CM_ SG_ 1122 PSD_Endkruemmung "'EndkrümmungderKlotoidedesübermitteltenStreckensegments.DieAnfangskrümmungdesfolgendenStreckensegmentsentsprichtderEndkrümmungdiesesSegments.Krümmung=1/(1+0.155*x²)[1/m]

";
CM_ SG_ 1122 PSD_Idenditaets_ID "IdentifieraufeinStreckensegment,dassmitdemaktuellübertragenengeometrischidentischist.";
CM_ SG_ 1122 PSD_ADAS_Qualitaet "ADASQualtitätdesStreckensegments.";
CM_ SG_ 1122 PSD_wahrscheinlichster_Pfad "IdentifiziertdenvomNavigationssystemberechnetenwahrscheinlichstenPfaddesFahrzeuges.";
CM_ SG_ 1122 PSD_Geradester_Pfad "SegmentistTeildesgeradestenPfades";
CM_ SG_ 1122 PSD_Fahrspuren_Anzahl "AnzahlderFahrspureninFahrtrichtung
";
CM_ SG_ 1122 PSD_Bebauung "SegementbefindetsichinnerhalbbebautenGebietes";
CM_ SG_ 1122 PSD_Segment_Komplett "Zeigt,oballeAttributefürdasSegmentübertragenwordensind
";
CM_ SG_ 1122 PSD_Anfangskruemmung "StartkrümmungderKlothoidedesübermitteltenabzweigendenStreckensegments.
1/(1+0.155 * x^2) {1/m}'
";
CM_ SG_ 1122 PSD_Anfangskruemmung_Vorz "VorzeichenfürdieStartkrümmungbeiAbzweigungen
";
CM_ SG_ 1122 PSD_Abzweigerichtung "Richtung,inderdieAbzweigungvonderHauptrouteabzweigt
";
CM_ SG_ 1122 PSD_Abzweigewinkel "Winkel,unterdemdieAbzweigungvonderHauptrouteabzweigt.
";
CM_ SG_ 1123 PSD_Pos_Segment_ID "IdentifierdesStreckensegments,aufdemsichdasFahrzeugaktuellbefindet
";
CM_ SG_ 1123 PSD_Pos_Segmentlaenge "VerbleibendeLängedesStreckensegments,aufdemsichdasFahrzeugaktuellbefindet
";
CM_ SG_ 1123 PSD_Pos_Inhibitzeit "ZeitspannezwischenGenerierungderPSDDatenimNavigationssystemundVersandderDatenaufdenMost
";
CM_ SG_ 1123 PSD_Pos_Standort_Eindeutig "IstdiePositiondesFahrzeugseindeutigdemaktuelleSegmentzugeordnet,odergibtesfahrbarealternativeSegmente,diebeiaktellerGPS-PositionebenfallsalsaktuellesSegmentmöglichwären.";
CM_ SG_ 1123 PSD_Pos_Fehler_Laengsrichtung "LaengsfehlerderPositionierung";
CM_ SG_ 1123 PSD_Pos_Fahrspur "Spur,aufdersichdasFahrzeugaktuellbefindet";
CM_ SG_ 1123 PSD_Attribut_Segment_ID_05 "IdentifierdesStreckensegments,fürdasdieweiterenAttributeinderBotschaftgültigsind";
CM_ SG_ 1123 PSD_Attribut_1_ID "IdentifierdeserstenAttributes";
CM_ SG_ 1123 PSD_Attribut_1_Wert "WertdeserstenAttributes";
CM_ SG_ 1123 PSD_Attribut_1_Offset "PositionsoffsetimSegmentfürdiePositiondesAttributs";
CM_ SG_ 1123 PSD_Attribut_2_ID "IdentifierdeszweitenAttributes";
CM_ SG_ 1123 PSD_Attribut_2_Wert "WertdeszweitenAttributes";
CM_ SG_ 1123 PSD_Attribut_2_Offset "PositionsoffsetimSegmentfürdiePositiondesAttributs";
CM_ SG_ 1123 PSD_Attribute_Komplett_05 "Zeigt,oballeAttributefürdasSegmentübertragenwordensind";
CM_ SG_ 1124 PSD_06_Mux "MultiplexZählerfürdiePSD_06-Botschaft.
Die unterschiedlichen Muxe folgen keiner festen Reihenfolge. Je nach Inhalt des PSD-Protokolls an der aktuellen Position werden jeweils die notwendigen PSD6-Botschaften gesendet.";
CM_ SG_ 1124 PSD_Sys_Segment_ID "IdentifierdesprädiktivenStreckensegmentsabdemdieSysteminformationengültigsind.
";
CM_ SG_ 1124 PSD_Attribut_Segment_ID "IdentifierdesStreckensegments,fürdasdieweiterenAttributeinderBotschaftgültigsind";
CM_ SG_ 1124 PSD_Ges_Segment_ID "IdentifierdesprädiktivenStreckensegmentsabdemdieGeschwindigkeitsbegrenzungenundmöglicheEinschränkungengelten.
";
CM_ SG_ 1124 PSD_Baum_Laenge_VZ "VorzeichenWGS84LaengedesFahrzeugsegments";
CM_ SG_ 1124 PSD_Steigung_1_Segment_ID "IdentifierdesprädiktivenStreckensegments,zudemdieerstenbeidenSteigungswertedieserBotschaftgehören";
CM_ SG_ 1124 PSD_Baum_Laenge "WGS84LaengedesFahrzeugsegments";
CM_ SG_ 1124 PSD_Sys_Laendercode "Ländercode
";
CM_ SG_ 1124 PSD_Attribut_3_ID "IdentifierdesdrittenAttributes";
CM_ SG_ 1124 PSD_Ges_Offset "PositionsoffsetimSegmentfürdiePositiondesAttributs";
CM_ SG_ 1124 PSD_Steigung_1_A_Steigung "SteigungdesSegmentsabOffset1A";
CM_ SG_ 1124 PSD_Attribut_3_Offset "PositionsoffsetimSegmentfürdiePositiondesAttributs";
CM_ SG_ 1124 PSD_Steigung_1_A_Vorz "VorzeichenfürSteigung1A";
CM_ SG_ 1124 PSD_Sys_Geschwindigkeit_Einheit "Unterscheidungzwischenkm/hundmiles/h";
CM_ SG_ 1124 PSD_Steigung_1_A_Offset "PositionsoffsetimSegmentfürdiePositionderSteigung1A";
CM_ SG_ 1124 PSD_Sys_Verkehrsrichtung "UnterscheidungzwischenLinksverkehrundRechtsverkehr";
CM_ SG_ 1124 PSD_Sys_Geometrieguete "MaßfürdieGütederKlothoidengeometrie.";
CM_ SG_ 1124 PSD_Sys_Mapmatchingguete "GütedesMapmatchings";
CM_ SG_ 1124 PSD_Attribut_3_Wert "WertdesdrittenAttributes";
CM_ SG_ 1124 PSD_Ges_Typ "TypderGeschwindigkeitsbegrenzung
";
CM_ SG_ 1124 PSD_Sys_Alter_Karte "AlterderKarte";
CM_ SG_ 1124 PSD_Ges_Spur_Geschw_Begrenzung "DefinitionderSpuren,fürdiedasübertrageneGebotgilt";
CM_ SG_ 1124 PSD_Steigung_1_B_Steigung "SteigungdesSegmentsabOffset1B";
CM_ SG_ 1124 PSD_Attribut_4_ID "TypvonAttribut4";
CM_ SG_ 1124 PSD_Sys_Zielfuehrung "ZielfuehrungimNavigationssystem.DamitlässtsichderwahrscheinlichstePfaddesFahrzeugeszuverlässigangeben.";
CM_ SG_ 1124 PSD_Sys_US_State "NamedesUSA-State";
CM_ SG_ 1124 PSD_Ges_Geschwindigkeit_Gespann "GiltdieseEinschränkungderGeschwindigkeitfüralleFahrzeugeoderausschließlichfürPKWmitGespannoderfürLKW,Buss,etc.";
CM_ SG_ 1124 PSD_Baum_Breite_VZ "VorzeichenWGS84BreitedesFahrzeugsegments";
CM_ SG_ 1124 PSD_Attribut_4_Wert "WertvonAttribut4";
CM_ SG_ 1124 PSD_Baum_Breite "WGS84BreitedesFahrzeugsegments";
CM_ SG_ 1124 PSD_Ges_Geschwindigkeit_Witter "WitterungsabhängigkeitderGeschwindigkeitsbegrenzung";
CM_ SG_ 1124 PSD_Steigung_1_B_Vorz "VorzeichenfürSteigung1B";
CM_ SG_ 1124 PSD_Steigung_1_B_Offset "PositionsoffsetimSegmentfürdiePositionderSteigung1B";
CM_ SG_ 1124 PSD_Sys_Quali_Geometrien "QualitätderGeometrienindieserRegion";
CM_ SG_ 1124 PSD_Ges_Geschwindigkeit_Tag_Anf "Wochentag,andemdietäglicheGeschwindigkeitsbegrenzungbeginnt";
CM_ SG_ 1124 PSD_Attribut_4_Offset "OffsetvonAttribut4";
CM_ SG_ 1124 PSD_Sys_Quali_Ortsinfo "QualitätOrtsinformationen(Bebauung,Ortsschild)dieserRegion";
CM_ SG_ 1124 PSD_Ges_Geschwindigkeit_Tag_Ende "Wochentag,andemdietäglicheGeschwindigkeitsbegrenzungendet";
CM_ SG_ 1124 PSD_Sys_Quali_verfuegbar "KarteenthältgültigeQualitätskriterien";
CM_ SG_ 1124 PSD_Sys_Zielfuehrung_geaendert "DieZielführung(Route)hatsichgeänderthatohnedassderFahrereineneueZielführunggestartethat";
CM_ SG_ 1124 PSD_Ges_Geschwindigkeit_Std_Anf "Stunde,zuderdiestündlicheGeschwindigkeitsbegrenzungbeginnt
0h.. 24h";
CM_ SG_ 1124 PSD_Steigung_1_Attribute_kompl "AlleSteigungsdatenfürdiesesSegmentgesendet";
CM_ SG_ 1124 PSD_Sys_Geometrieguete_erweitert "GütederKurvenrepräsentationderKlothoiden";
CM_ SG_ 1124 PSD_Steigung_2_Segment_ID "IdentifierdesprädiktivenStreckensegments,zudemderdritteSteigungswertdieserBotschaftgehört";
CM_ SG_ 1124 PSD_Attribut_5_ID "TypvonAttribut5";
CM_ SG_ 1124 PSD_Ges_Geschwindigkeit_Std_Ende "Stunde,anderdiestündlicheGeschwindigkeitsbegrenzungendet
0h.. 24h";
CM_ SG_ 1124 PSD_Attribut_5_Offset "OffsetvonAttribut5";
CM_ SG_ 1124 PSD_Steigung_2_Steigung "SteigungdesSegmentsabOffset2";
CM_ SG_ 1124 PSD_Sys_Quali_sonstige_Attribute "QualitätsonstigerAttributedieserRegion";
CM_ SG_ 1124 PSD_Sys_Quali_Steigungen "QualitätderSteigungendieserRegion";
CM_ SG_ 1124 PSD_Ges_Wechselverkehrszeichen "AmBeginndesSegmentsisteinWechselverkehrszeichenangebracht.";
CM_ SG_ 1124 PSD_Attribut_5_Wert "WertvonAttribut5";
CM_ SG_ 1124 PSD_Steigung_2_Vorz "VorzeichenfürSteigung2";
CM_ SG_ 1124 PSD_Sys_Quali_Strassenkennz "QualitätStraßenkennzeichnungendieserRegion";
CM_ SG_ 1124 PSD_Wechselverkehrszeichen_Typ "TypdesWechselverkehrszeichen";
CM_ SG_ 1124 PSD_Baum_Ausrichtung "AusrichtungdesFahrzeugsegmentszuNord";
CM_ SG_ 1124 PSD_Steigung_2_Offset "PositionsoffsetimSegmentfürdiePositionderSteigung2";
CM_ SG_ 1124 PSD_Ges_Gesetzlich_Kategorie "KategoriefürdaslegaleGebot";
CM_ SG_ 1124 PSD_Sys_Quali_Tempolimits "QualitätTempolimitsdieserRegion";
CM_ SG_ 1124 PSD_Attribute_Komplett_06 "Zeigt,oballeAttributefürdasSegmentübertragenwordensind
";
CM_ SG_ 1124 PSD_Ges_Gesetzlich_Zusatz "ZusatzfürdaslegaleGebot";
CM_ SG_ 1124 PSD_Sys_Quali_Vorfahrtsregelung "QualitätVorfahrtsregelungendieserRegion";
CM_ SG_ 1124 PSD_Ges_Verkehrszeichen_Quelle "QuellederVerkehrszeicheninformation";
CM_ SG_ 1124 PSD_Steigung_2_Attribute_kompl "AlleSteigungsdatenfürdiesesSegmentgesendet";
CM_ SG_ 1124 PSD_Ges_Attribute_Komplett "Zeigt,oballeAttributefürdasSegmentübertragenwordensind";
CM_ SG_ 591 RDR1_relevanter_Fehler "RDR1-SGerkennteinenFehler,mitFSP-Eintrag.";
CM_ SG_ 591 RDR1_Blindheit_erkannt "Blindheitserkennung";
CM_ SG_ 591 RDR1_relev_Nichtverfuegbarkeit "RDR1-SGerkennteinetemporäreNichtverfügbarkeit,ohneFSP-Eintrag";
CM_ SG_ 591 RDR1_Obj_01_Nummer "InterneObjektnummer(Track)";
CM_ SG_ 591 RDR1_Obj_02_Nummer "InterneObjektnummer(Track)";
CM_ SG_ 591 RDR1_Obj_03_Nummer "InterneObjektnummer(Track)";
CM_ SG_ 591 RDR1_Obj_04_Nummer "InterneObjektnummer(Track)";
CM_ SG_ 591 RDR1_Obj_05_Nummer "InterneObjektnummer(Track)";
CM_ SG_ 591 RDR1_Obj_06_Nummer "InterneObjektnummer(Track)";
CM_ SG_ 591 RDR1_Verkehrssinn "vomRadarerkannterVerkehrssinn";
CM_ SG_ 591 RDR1_Objekte_02_Datenalter "DatenalterderObjekteausBotschaftRDR1_Objekte_02";
CM_ SG_ 591 RDR1_Obj_01_dx_v "x-AbstanddesbezüglichdesEgo-Fzg.-MomentankursesdetektiertenObjektdatenblocks";
CM_ SG_ 591 RDR1_Obj_01_dy_v "y-AbstanddesbezüglichdesEgo-Fzg.-MomentankursesdetektiertenObjektdatenblocks";
CM_ SG_ 591 RDR1_Obj_01_vx_v "Relativgeschwindigkeitinx-RichtungdesbezüglichdesEgo-Fzg.MomentankursesdetektiertenObjektes";
CM_ SG_ 591 RDR1_Obj_02_dx_v "x-AbstanddesbezüglichdesEgo-Fzg.-MomentankursesdetektiertenObjektdatenblocks";
CM_ SG_ 591 RDR1_Obj_02_dy_v "y-AbstanddesbezüglichdesEgo-Fzg.-MomentankursesdetektiertenObjektdatenblocks";
CM_ SG_ 591 RDR1_Obj_02_vx_v "Relativgeschwindigkeitinx-RichtungdesbezüglichdesEgo-Fzg.MomentankursesdetektiertenObjektes";
CM_ SG_ 591 RDR1_Obj_03_dx_v "x-AbstanddesbezüglichdesEgo-Fzg.-MomentankursesdetektiertenObjektdatenblocks";
CM_ SG_ 591 RDR1_Obj_03_dy_v "y-AbstanddesbezüglichdesEgo-Fzg.-MomentankursesdetektiertenObjektdatenblocks";
CM_ SG_ 591 RDR1_Obj_03_vx_v "Relativgeschwindigkeitinx-RichtungdesbezüglichdesEgo-Fzg.MomentankursesdetektiertenObjektes";
CM_ SG_ 591 RDR1_Obj_04_dx_v "x-AbstanddesbezüglichdesEgo-Fzg.-MomentankursesdetektiertenObjektdatenblocks";
CM_ SG_ 591 RDR1_Obj_04_dy_v "y-AbstanddesbezüglichdesEgo-Fzg.-MomentankursesdetektiertenObjektdatenblocks";
CM_ SG_ 591 RDR1_Obj_04_vx_v "Relativgeschwindigkeitinx-RichtungdesbezüglichdesEgo-Fzg.MomentankursesdetektiertenObjektes";
CM_ SG_ 591 RDR1_Obj_05_dx_v "x-AbstanddesbezüglichdesEgo-Fzg.-MomentankursesdetektiertenObjektdatenblocks";
CM_ SG_ 591 RDR1_Obj_05_dy_v "y-AbstanddesbezüglichdesEgo-Fzg.-MomentankursesdetektiertenObjektdatenblocks";
CM_ SG_ 591 RDR1_Obj_05_vx_v "Relativgeschwindigkeitinx-RichtungdesbezüglichdesEgo-Fzg.MomentankursesdetektiertenObjektes";
CM_ SG_ 591 RDR1_Obj_06_dx_v "x-AbstanddesbezüglichdesEgo-Fzg.-MomentankursesdetektiertenObjektdatenblocks";
CM_ SG_ 591 RDR1_Obj_06_dy_v "y-AbstanddesbezüglichdesEgo-Fzg.-MomentankursesdetektiertenObjektdatenblocks";
CM_ SG_ 591 RDR1_Obj_06_vx_v "Relativgeschwindigkeitinx-RichtungdesbezüglichdesEgo-Fzg.MomentankursesdetektiertenObjektes";
CM_ SG_ 591 RDR1_Obj_01_ax_v "Relativbeschleunigunginx-RichtungdesbezüglichdesEgo-Fzg.MomentankursesdetektiertenObjektes";
CM_ SG_ 591 RDR1_Obj_01_ax_StdA "StandardabweichungderRelativbeschleunigunginx-RichtungdesbezüglichdesEgo-Fzg.MomentankursesdetektiertenObjektes";
CM_ SG_ 591 RDR1_Obj_01_vx_StdA "StandardabweichungderRelativgeschwindigkeitinx-RichtungdesbezüglichdesEgo-Fzg.MomentankursesdetektiertenObjektes";
CM_ SG_ 591 RDR1_Obj_01_dx_StdA "Standardabweichungdesx-AbstandsdesbezüglichdesEgo-Fzg.-MomentankursesdetektiertenObjektdatenblocks";
CM_ SG_ 591 RDR1_Obj_01_dy_StdA "Standardabweichungdesy-AbstandsdesbezüglichdesEgo-Fzg.-MomentankursesdetektiertenObjektdatenblocks";
CM_ SG_ 2033 Request_Airbag_Deployment "RequestfürdieDisposalDiagnose(ISO26021)";
CM_ SG_ 2041 Response_Airbag_Deployment "ResponsefürdieDisposalDiagnose(ISO26021)";
CM_ SG_ 980 SMLS_01_CRC "FürMLB:
'Berechnung siehe Lastenheft 'Kommunikationsabsicherung für FlexRay und CAN''

Ab MQB und MLBevo:
'Berechnung siehe Lastenheft 'End-to-End Kommunikationsabsicherung''

Endwerte siehe Begleitdokument 'S-PDU Kennungsfolgen'";
CM_ SG_ 980 SMLS_01_BZ "4bitBotschaftszaehler,wirdmitjederSendebotschaftinkrementiert";
CM_ SG_ 980 BH_Blinker_li "BlinkerhebelRichtunglinks
";
CM_ SG_ 980 BH_Blinker_re "BlinkerhebelRichtungrechts
";
CM_ SG_ 980 BH_Lichthupe "BetaetigungLichthupe
";
CM_ SG_ 980 BH_Fernlicht "BetaetigungFernlicht
";
CM_ SG_ 980 WH_Tipwischen "Wischerhebel:Tippwischen

MQB A0/ PQ26: Bei Verbau LSS (kein SMLS): gespiegelter Wert zu Signal WH_WischerStufe1";
CM_ SG_ 980 WH_Intervall "Wischerhebel:StellungIntervall
";
CM_ SG_ 980 WH_WischerStufe1 "Wischerhebel:StufeWischen1
";
CM_ SG_ 980 WH_WischerStufe2 "Wischerhebel:StufeWischen2
";
CM_ SG_ 980 WH_Frontwaschen "Wischerhebel:StellungWischWaschvorne
";
CM_ SG_ 980 WH_Heckintervall "Wischerhebel:StellungHeckintervall
";
CM_ SG_ 980 WH_Heckwaschen "Wischerhebel:StellungWischWaschhinten
";
CM_ SG_ 980 WH_Intervallstufen "Wischerhebel:StellungIntervallstufen";
CM_ SG_ 980 FAS_Taster "BetaetigungFASTaster
";
CM_ SG_ 980 FAS_Taster_Fehler "FehlerstatusFASTaster
";
CM_ SG_ 980 SMLS_Hupe "BetaetigungHupe
";
CM_ SG_ 980 LRH_on_off "StatusLenkradheizung";
CM_ SG_ 980 LSS_Tastencode "0x00=Nokeypressed/keyreleased
0x01 = Menu
0x02 = Menu Up / Next Screen
0x03 = Menu Down / Previous Screen
0x04 = Up
0x05 = Down
0x06 = Up / Down ThumbWheel
0x07 = OK (ThumbWheel-Button)
0x08 = Cancel / Escape
0x09..0x0F = reserved for furt";
CM_ SG_ 980 LRH_aktiv "Signalgibtan,obeinHeizstromdurchdieLenkradheizungfließt.EsdientderAuswertungdurchdasEnergiemanagement.";
CM_ SG_ 980 SMLS_P_verriegelt "SignalstelltdenStatusdesSignalsP-verriegeltaufdenFahrzeugbuszurVerfügung.Nutzersindz.B.dieELV,diedasSignalfürdieVerriegelungbenötigtunddieFunktionVerlassenswarnung,diedenFahrerbeimVerrollendesFahrzeugswarnt.";
CM_ SG_ 980 SMLS_P_verriegelt_plausibel "SignalstelltdenPlausibilisierungstatusdesSignalsp_verriegeltaufdenFahrzeugbuszurVerfügung.EinePlausibilitätmussexpliziterkanntwerden.Initialwird'unplausibel'gesendet.EinplausiblesSignalwirderkannt,wennp_verriegeltplausibelgeg";
CM_ SG_ 980 WH_SRA "Scheinwerferreinigungsanlage

derzeit nur bei PAG umgesetzt";
CM_ SG_ 980 WH_Wischer_Fehler "Anzeige,obamLenkstockschaltereinFehleranliegt.
Notwendig aufgrund ASIL-Einstufung";
CM_ SG_ 980 BH_Blinker_Fehler "Anzeige,obamLenkstockschaltereinFehleranliegt.
Notwendig aufgrund ASIL-Einstufung";
CM_ SG_ 980 SMLS_PTT "BetaetigungPTT";
CM_ SG_ 980 WH_Tipwischen_lang "Wischerhebel:Tippwischenlang
(dient zur Auswertung für die Unterscheidung Tippwischen oder Serviceposition Wischer)";
CM_ SG_ 2464153718 SOK_FoD_MO_01_Req_Challenge "ChallengeimRahmendesSOKChallenge-ResponseProtokolls.

Geschützte Funktion: Function on Demand";
CM_ SG_ 2464284790 SOK_FoD_MO_01_Resp_Challenge "ChallengeimRahmendesSOKChallenge-ResponseProtokolls.

Geschützte Funktion: Function on Demand";
CM_ SG_ 1413 SI_Sammel_SG_Fehler "AnzahldergesetztenKD-FehlerdirektangeschlossenerSteuergerätederDK3undDK4gemäß80127.
Hinweis: Ein Subbusmaster stellt nur die gesammelte Information der an ihn angeschlossenen Steuergeräte der DK3 und DK4 zur Verfügung.

Für ServiceKey Auswe";
CM_ SG_ 1413 SI_P_Mode_gueltig "zeigtan,obessichumeinFahrzeugmitzentraleroderdezentralerSteu-erungdesProduktionsmodeshandelt
Siehe Q-LAH Produktionsmode (LAH.DUM.907.AS)";
CM_ SG_ 1413 SI_Diagnose_Aktiv "GibtanobDiagnose-BotschaftenempfangenwerdenundsomiteineDiagnoseaktivist.
MQB: Gibt an ob Diagnose-Bus Botschaften empfangen werden und somit eine Diagnose aktiv ist.";
CM_ SG_ 1413 SI_T_Mode "0x0:Transportmodusnichtaktiv
0x1: Transportmodus aktiv";
CM_ SG_ 1413 SI_NWDF "Netzwerk-DiagnoseFreigebezurzentralenAktivierungderNetzwerkdiagnose";
CM_ SG_ 1413 SI_NWDF_gueltig "GültigkeitsbitzuSI_NWDFgemäßLastenheft:ZentraleAktivierungNetzwerkdiagnose";
CM_ SG_ 1413 SI_Sammelfehler "SammelfehlermeldungzurAnzeigeimKombi-sieheSpez.Sammelfehlermeldung
Hinweis: Einzelne Steuergeräte können zur Anpassung an den Produktionsprozess im Gateway auskodiert werden!";
CM_ SG_ 1413 GW_KD_Fehler "KundendienstfehlerbitGatewayzurAnzeigeeinesimGatewayabgelegtenFehlerspeichereintrages.";
CM_ SG_ 1413 SI_T_Schutz "Transportschutz-Signal,dasbeiTransportmodusundMotorlaufaktivbleibt
0x0: Transportschutz nicht aktiv
0x1: Transportschutz aktiv";
CM_ SG_ 1413 SI_P_Mode "ZentraleSteuerungdesProduktionsmodesgemäßQ-LAH-Produktionsmode(LAH.DUM.907.AS)";
CM_ SG_ 1413 SI_BUS_01 "MQB/MQB_A0/PQ26:ACAN
MQB2020: ACAN(FD)
MLBevo: HCAN
MEB: ACAN(FD)";
CM_ SG_ 1413 SI_BUS_02 "MQB/MQBA0Standard+,High:FCAN
MQB2020: FCAN(FD)
MLBevo: Frei
MEB: FCAN(FD)";
CM_ SG_ 1413 SI_BUS_03 "MQB/MQBA0/PQ26:KCAN
MQB2020: KCAN
MLBevo: KCAN
MEB: KCAN";
CM_ SG_ 1413 SI_BUS_04 "MQB/MQBA0Standard+,High:ICAN
MQB2020: ICAN
MLBevo: ICAN
MEB: ABCAN(FD)";
CM_ SG_ 1413 SI_BUS_05 "MQB/MQBA0/PQ26:DiagCAN
MQB2020: DiagCAN(FD)
MLBevo: DiagCAN
MEB: DiagCAN(FD)";
CM_ SG_ 1413 SI_BUS_06 "MQB/MQBA0/PQ26:ECAN
MQB2020: FASCAN(FD)
MLBevo: ECAN
MEB: FASCAN(FD)";
CM_ SG_ 1413 SI_BUS_07 "MQB:LIN1(Energie)
MQB2020: LIN1 (Energie)
MLBevo: LIN1 (Energie)";
CM_ SG_ 1413 SI_BUS_08 "MQB:LIN2(MFL)
MQB2020: LIN2 (MFL)
MLBevo: LIN2 (MFL)";
CM_ SG_ 1413 SI_BUS_09 "MQB:LIN3(unbelegt)
MQB2020: LIN3 (Uhr/FES)
MLBevo: LIN3 (Energie2)";
CM_ SG_ 1413 SI_BUS_10 "MLBevo:Flexray

MQB2020: MCAN";
CM_ SG_ 1413 SI_BUS_11 "MLBevo:Ethernet";
CM_ SG_ 1413 SI_BUS_12 "MQB:unbelegt
MLBevo: K2CAN";
CM_ SG_ 1413 SI_BUS_13 "MQB:unbelegt
MLBevo: DCAN
MEB: CCAN";
CM_ SG_ 1413 SI_BUS_14 "MQB/MQBA0:unbelegt
MQB2020: HCAN
MLBevo: CCAN
MEB: EVCAN(FD)";
CM_ SG_ 1413 SI_BUS_15 "MQB:frei
MQB2020: frei
MLBevo: frei
MEB: AFSCAN";
CM_ SG_ 1413 SI_Bus_Identifikation "DasSignalidentifiziertdenBuseindeutig.DasSignalistkonstantaufjedemBus.
Der Signalwert entspricht dem Wert 'Busnummer' aus der VW80127 Gateway_component_list_databus_identification (0x2A2D) 'Bus-Identifier'.";
CM_ SG_ 1413 SI_CAB_V10 "CAB=Clusteraktivbits(V10)";
CM_ SG_ 2589283396 TSK_vMax_EfficiencyMode1 "GlobalesLimitimEffizienz1Fahrprofil/Fahrmodus(e.g.'ECO').";
CM_ SG_ 2589283396 TSK_vMax_EfficiencyMode2 "GlobalesLimitimEfficiency2Fahrprofil/Fahrprogramm(e.g.'ECO+'oder'Rangeplus').";
CM_ SG_ 2589283396 TSK_vMax_StandardMode "GlobalesLimitimStandardFahrprofil/FahrprogrammModus(e.g.'normal'oder'comfort').";
CM_ SG_ 1019 TSK_Ausrollkurve_Schub_Reku_01 "DiesesSignalsendetdieStützstelle1derSchub-/Rekuausrollkurve.";
CM_ SG_ 1019 TSK_Ausrollkurve_Schub_Reku_05 "DiesesSignalsendetdieStützstelle5derSchub-/Rekuausrollkurve.";
CM_ SG_ 1019 TSK_Ausrollkurve_Schub_Reku_09 "DiesesSignalsendetdieStützstelle9derSchub-/Rekuausrollkurve.";
CM_ SG_ 1019 TSK_Ausrollkurve_Schub_Reku_13 "DiesesSignalsendetdieStützstelle13derSchub-/Rekuausrollkurve.";
CM_ SG_ 1019 TSK_Ausrollkurve_Schub_Reku_17 "DiesesSignalsendetdieStützstelle17derSchub-/Rekuausrollkurve.";
CM_ SG_ 1019 TSK_Ausrollkurve_Schub_Reku_02 "DiesesSignalsendetdieStützstelle2derSchub-/Rekuausrollkurve.";
CM_ SG_ 1019 TSK_Ausrollkurve_Schub_Reku_06 "DiesesSignalsendetdieStützstelle6derSchub-/Rekuausrollkurve.";
CM_ SG_ 1019 TSK_Ausrollkurve_Schub_Reku_10 "DiesesSignalsendetdieStützstelle10derSchub-/Rekuausrollkurve.";
CM_ SG_ 1019 TSK_Ausrollkurve_Schub_Reku_14 "DiesesSignalsendetdieStützstelle14derSchub-/Rekuausrollkurve.";
CM_ SG_ 1019 TSK_Ausrollkurve_Schub_Reku_18 "DiesesSignalsendetdieStützstelle18derSchub-/Rekuausrollkurve.";
CM_ SG_ 1019 TSK_Ausrollkurve_Schub_Reku_03 "DiesesSignalsendetdieStützstelle3derSchub-/Rekuausrollkurve.";
CM_ SG_ 1019 TSK_Ausrollkurve_Schub_Reku_07 "DiesesSignalsendetdieStützstelle7derSchub-/Rekuausrollkurve.";
CM_ SG_ 1019 TSK_Ausrollkurve_Schub_Reku_11 "DiesesSignalsendetdieStützstelle11derSchub-/Rekuausrollkurve.";
CM_ SG_ 1019 TSK_Ausrollkurve_Schub_Reku_15 "DiesesSignalsendetdieStützstelle15derSchub-/Rekuausrollkurve.";
CM_ SG_ 1019 TSK_Ausrollkurve_Schub_Reku_19 "DiesesSignalsendetdieStützstelle19derSchub-/Rekuausrollkurve.";
CM_ SG_ 1019 TSK_Ausrollkurve_Schub_Reku_04 "DiesesSignalsendetdieStützstelle4derSchub-/Rekuausrollkurve.";
CM_ SG_ 1019 TSK_Ausrollkurve_Schub_Reku_08 "DiesesSignalsendetdieStützstelle8derSchub-/Rekuausrollkurve.";
CM_ SG_ 1019 TSK_Ausrollkurve_Schub_Reku_12 "DiesesSignalsendetdieStützstelle12derSchub-/Rekuausrollkurve.";
CM_ SG_ 1019 TSK_Ausrollkurve_Schub_Reku_16 "DiesesSignalsendetdieStützstelle16derSchub-/Rekuausrollkurve.";
CM_ SG_ 1019 TSK_Ausrollkurve_Schub_Reku_20 "DiesesSignalsendetdieStützstelle20derSchub-/Rekuausrollkurve.";
CM_ SG_ 1019 TSK_Ausrollkurve_Segeln_01 "DiesesSignalsendetdieStützstelle1derSegelausrollkurve.";
CM_ SG_ 1019 TSK_Ausrollkurve_Segeln_05 "DiesesSignalsendetdieStützstelle5derSegelausrollkurve.";
CM_ SG_ 1019 TSK_Ausrollkurve_Segeln_09 "DiesesSignalsendetdieStützstelle9derSegelausrollkurve.";
CM_ SG_ 1019 TSK_Ausrollkurve_Segeln_13 "DiesesSignalsendetdieStützstelle13derSegelausrollkurve.";
CM_ SG_ 1019 TSK_Ausrollkurve_Segeln_17 "DiesesSignalsendetdieStützstelle17derSegelausrollkurve.";
CM_ SG_ 1019 TSK_Ausrollkurve_Segeln_02 "DiesesSignalsendetdieStützstelle2derSegelausrollkurve.";
CM_ SG_ 1019 TSK_Ausrollkurve_Segeln_06 "DiesesSignalsendetdieStützstelle6derSegelausrollkurve.";
CM_ SG_ 1019 TSK_Ausrollkurve_Segeln_10 "DiesesSignalsendetdieStützstelle10derSegelausrollkurve.";
CM_ SG_ 1019 TSK_Ausrollkurve_Segeln_14 "DiesesSignalsendetdieStützstelle14derSegelausrollkurve.";
CM_ SG_ 1019 TSK_Ausrollkurve_Segeln_18 "DiesesSignalsendetdieStützstelle18derSegelausrollkurve.";
CM_ SG_ 1019 TSK_Ausrollkurve_Segeln_03 "DiesesSignalsendetdieStützstelle3derSegelausrollkurve.";
CM_ SG_ 1019 TSK_Ausrollkurve_Segeln_07 "DiesesSignalsendetdieStützstelle7derSegelausrollkurve.";
CM_ SG_ 1019 TSK_Ausrollkurve_Segeln_11 "DiesesSignalsendetdieStützstelle11derSegelausrollkurve.";
CM_ SG_ 1019 TSK_Ausrollkurve_Segeln_15 "DiesesSignalsendetdieStützstelle15derSegelausrollkurve.";
CM_ SG_ 1019 TSK_Ausrollkurve_Segeln_19 "DiesesSignalsendetdieStützstelle19derSegelausrollkurve.";
CM_ SG_ 1019 TSK_Ausrollkurve_Segeln_04 "DiesesSignalsendetdieStützstelle4derSegelausrollkurve.";
CM_ SG_ 1019 TSK_Ausrollkurve_Segeln_08 "DiesesSignalsendetdieStützstelle8derSegelausrollkurve.";
CM_ SG_ 1019 TSK_Ausrollkurve_Segeln_12 "DiesesSignalsendetdieStützstelle12derSegelausrollkurve.";
CM_ SG_ 1019 TSK_Ausrollkurve_Segeln_16 "DiesesSignalsendetdieStützstelle16derSegelausrollkurve.";
CM_ SG_ 1019 TSK_Ausrollkurve_Segeln_20 "DiesesSignalsendetdieStützstelle20derSegelausrollkurve.";
CM_ SG_ 1019 TSK_Ausrollkurve_Mux "DiesesSignaldientalsMultiplexzählerfürdieSegel-bzw.Schub-/RekuAusrollkurve";
CM_ SG_ 1019 TSK_Ausrollkurve_Reku "DiesesSignalzeigtan,obbeiderSchub-/RekuausrollkurveaktuellRekuperationberücksichtigtwird.";
CM_ SG_ 1019 TSK_Ausrollkurve_Schrittweite "DiesesSignaldientdientzurUmschaltungderStützstellenschrittweitederSegel-bzw.Schub-/Rekuausrollkurve";
CM_ SG_ 1019 TSK_Ausrollkurve_Zaehler "DiesesSignalermöglichtdieUnterscheidungderAusrollkurven.EswirdnachdervollständigenÜbertragungeinerKennlinieinkrementiert.";
CM_ SG_ 1716 VIN_01_MUX "Achtung:
Die Botschaft ist nicht linear gemultiplext!!!
Sondern 0,1,0,2,0, usw.";
CM_ SG_ 1716 VIN_4 "Initwert:
0x2D bei Fahrzeugen mit Wegfahrsperrengeneration >= 5
0x58 bei Fahrzeugen mit Wegfahrsperrengeneration < 5 (z.B. WFS-4)";
CM_ SG_ 1716 VIN_11 "Initwert:
0x2D bei Fahrzeugen mit Wegfahrsperrengeneration >= 5
0x58 bei Fahrzeugen mit Wegfahrsperrengeneration < 5 (z.B. WFS-4)";
CM_ SG_ 1716 VIN_5 "Initwert:
0x2D bei Fahrzeugen mit Wegfahrsperrengeneration >= 5
0x58 bei Fahrzeugen mit Wegfahrsperrengeneration < 5 (z.B. WFS-4)";
CM_ SG_ 1716 VIN_12 "Initwert:
0x2D bei Fahrzeugen mit Wegfahrsperrengeneration >= 5
0x58 bei Fahrzeugen mit Wegfahrsperrengeneration < 5 (z.B. WFS-4)";
CM_ SG_ 1716 VIN_6 "Initwert:
0x2D bei Fahrzeugen mit Wegfahrsperrengeneration >= 5
0x58 bei Fahrzeugen mit Wegfahrsperrengeneration < 5 (z.B. WFS-4)";
CM_ SG_ 1716 VIN_13 "Initwert:
0x2D bei Fahrzeugen mit Wegfahrsperrengeneration >= 5
0x58 bei Fahrzeugen mit Wegfahrsperrengeneration < 5 (z.B. WFS-4)";
CM_ SG_ 1716 VIN_7 "Initwert:
0x2D bei Fahrzeugen mit Wegfahrsperrengeneration >= 5
0x58 bei Fahrzeugen mit Wegfahrsperrengeneration < 5 (z.B. WFS-4)";
CM_ SG_ 1716 VIN_14 "Initwert:
0x2D bei Fahrzeugen mit Wegfahrsperrengeneration >= 5
0x58 bei Fahrzeugen mit Wegfahrsperrengeneration < 5 (z.B. WFS-4)";
CM_ SG_ 1716 VIN_1 "Initwert:
0x2D bei Fahrzeugen mit Wegfahrsperrengeneration >= 5
0x58 bei Fahrzeugen mit Wegfahrsperrengeneration < 5 (z.B. WFS-4)";
CM_ SG_ 1716 VIN_8 "Initwert:
0x2D bei Fahrzeugen mit Wegfahrsperrengeneration >= 5
0x58 bei Fahrzeugen mit Wegfahrsperrengeneration < 5 (z.B. WFS-4)";
CM_ SG_ 1716 VIN_15 "Initwert:
0x2D bei Fahrzeugen mit Wegfahrsperrengeneration >= 5
0x58 bei Fahrzeugen mit Wegfahrsperrengeneration < 5 (z.B. WFS-4)";
CM_ SG_ 1716 VIN_2 "Initwert:
0x2D bei Fahrzeugen mit Wegfahrsperrengeneration >= 5
0x58 bei Fahrzeugen mit Wegfahrsperrengeneration < 5 (z.B. WFS-4)";
CM_ SG_ 1716 VIN_9 "Initwert:
0x2D bei Fahrzeugen mit Wegfahrsperrengeneration >= 5
0x58 bei Fahrzeugen mit Wegfahrsperrengeneration < 5 (z.B. WFS-4)";
CM_ SG_ 1716 VIN_16 "Initwert:
0x2D bei Fahrzeugen mit Wegfahrsperrengeneration >= 5
0x58 bei Fahrzeugen mit Wegfahrsperrengeneration < 5 (z.B. WFS-4)";
CM_ SG_ 1716 VIN_3 "Initwert:
0x2D bei Fahrzeugen mit Wegfahrsperrengeneration >= 5
0x58 bei Fahrzeugen mit Wegfahrsperrengeneration < 5 (z.B. WFS-4)";
CM_ SG_ 1716 VIN_10 "Initwert:
0x2D bei Fahrzeugen mit Wegfahrsperrengeneration >= 5
0x58 bei Fahrzeugen mit Wegfahrsperrengeneration < 5 (z.B. WFS-4)";
CM_ SG_ 1716 VIN_17 "Initwert:
0x2D bei Fahrzeugen mit Wegfahrsperrengeneration >= 5
0x58 bei Fahrzeugen mit Wegfahrsperrengeneration < 5 (z.B. WFS-4)";
CM_ SG_ 261 VMM_01_CRC "FürMLB:
Berechnung siehe Lastenheft 'Kommunikationsabsicherung für FlexRay und CAN'
Ab MQB und MLBevo:
Berechnung siehe Lastenheft 'End-to-End Kommunikationsabsicherung'

Endwerte siehe Begleitdokument 'S-PDU Kennungsfolgen'";
CM_ SG_ 261 VMM_01_BZ "4bitBotschaftszähler,wirdmitjederSendebotschaftinkrementiert";
CM_ SG_ 261 HMS_P_beibehalten_GE "FordertdasGetriebeaufinStellung'P'zubleiben.";
CM_ SG_ 261 VZM_Unterdrueckung_Antriebsmom "MitdiesemSignalwirddemTSKsignalisiertobeinpositivesAntriebsmomentangefordertwerdenkann.IneinerNotbremsungistdaspositiveAntriebsmomentzuunterdrücken.";
CM_ SG_ 261 HMS_halten_nicht_verfuegbar "RueckmeldungHMS-Teilfunktion'Halten'nichtverfuegbar.";
CM_ SG_ 261 HMS_parken_nicht_verfuegbar "RueckmeldungHMS-Teilfunktionen'Parken'nichtverfuegbar.";
CM_ SG_ 261 HMS_Anforderung_GE "FordertvomGetriebebestimmteSchaltstellungenan.";
CM_ SG_ 261 HMS_Systemstatus "ZeigtdenaktuellenSystemstatusdesHMSan.";
CM_ SG_ 261 HMS_Stillstand "DasSignalzeigt,basierendaufdenvierESP-Raddrehzahlinformatioen,gefiltertund/oderentprelltmehrstufigdenFahrzeuggeschwindigkeitszustandan.";
CM_ SG_ 261 HMS_aktives_System "Zeigtan,vonwelchemSystemdieAnforderunggeradeumgesetztwird.";
CM_ SG_ 261 VMM_Inkonsistenz_GE "Zeigtan,obdieKommunikationunddieAnforderungenplausibelsind.";
CM_ SG_ 261 VMM_Inkonsistenz_HVLM "RückmeldungInkonsistenzHVLM";
CM_ SG_ 261 HMS_Fehlerstatus "ZeigtdenFehlerstatusdesHaltemanagementsystemsHMSan.
Details zu den Werten 3/4:
3=Systemeinschränkung, Parken EPB oder GSG nicht möglich
4=Systemstörung bzw. Parken EPB und GSG nicht möglich  ";
CM_ SG_ 261 HMS_Index_Haltemoment "Zeigtan,obdasSummen-HMS_HaltemomenteinBremsmoment(bergab)odereinAntriebsmoment(bergauf)darstellt.";
CM_ SG_ 261 HMS_Haltemoment "ZeigtinAbhängigkeitvonHMS_Index_HaltemomentdasnotwendigeSummen-Radmomentan(bergab:Bremsmoment;bergauf:Antriebsmoment),dasmindestensnotwendigistumdasFahrzeuganderaktuellenNeigungzuhalten.";
CM_ SG_ 313 VMM_02_CRC "FürMLB:
Berechnung siehe Lastenheft 'Kommunikationsabsicherung für FlexRay und CAN'
Ab MQB und MLBevo:
Berechnung siehe Lastenheft 'End-to-End Kommunikationsabsicherung'

Endwerte siehe Begleitdokument 'S-PDU Kennungsfolgen'";
CM_ SG_ 313 VMM_02_BZ "4bitBotschaftszähler,wirdmitjederSendebotschaftinkrementiert";
CM_ SG_ 313 VZM_aktiver_Basisservice "IndiesemSignalwirdderaktiveBasisservicedesVerzögerungsmanagementzurückgegeben.";
CM_ SG_ 313 VZM_Anhalteweg_nicht_verfuegbar "RückmeldungobdieAnhaltewegregelungverfügbarist.";
CM_ SG_ 313 VZM_Fahrer_bremst "BitwirdgesetztbeimÜberschreitenderBremsdruckschwelle

Weiterführende Informationen im Lastenheft spezifiziert und in der entsprechenden Fachabteilung zu erfragen.";
CM_ SG_ 313 VZM_QBit_Fahrer_bremst "GültigkeitderBremsdruckschwelleninformationdesSignalsVZM_Fahrer_bremstundVZM_Fahrer_bremst_deutlich
0x1 = Druckschwelleninformation kann noch nicht oder aufgrund eines Fehlers nicht ausgegeben werden";
CM_ SG_ 313 VMM_MKB_codiert "DasSignalkennzeichnetdenCodierstatusdesESC-SGbzgl.derFunktionMultikollisionsbremse.";
CM_ SG_ 313 VMM_Inkonsistenz_EBKV "RückmeldungInkonsistenzEBKV";
CM_ SG_ 313 VMM_Notstopp_Status "StatusdesNotstoppsystems";
CM_ SG_ 313 VZM_Warnruck_nicht_verfuegbar "RückmeldungobeineinfacherWarnruckangefordertwerdenkann.";
CM_ SG_ 313 VZM_Warnruckeln_nicht_verfuegbar "RückmeldungobmehrfacheinWarnruckdurchgeführtwerdenkann.";
CM_ SG_ 313 VZM_Bkd_nicht_verfuegbar "DiesesSignalgibteineRückmeldungobeineBremsenkonditionierung(PrefillundSystemtotzeitminimierung)verfügbarist.";
CM_ SG_ 313 VMM_Bremslicht_defekt "RückmeldungobbeideBremslichterdefektsind.BeigestecktemAnhängerwerdendieAnhängerbremslichterausgewertet.";
CM_ SG_ 313 VZM_Fahrer_bremst_deutlich "RückmeldunganAWVobderFahrerdasBremspedaldeutlichbetätigthat";
CM_ SG_ 313 VZM_TSK_SRBM_Anf "QuittierungfürTSK(SRBM=Summenradbremsmoment)Anforderung";
CM_ SG_ 313 VZM_TSK_SRBM_nicht_verfuegbar "RückmeldungobdaseinSummenradbremsmomentangefordertwerdenkann.";
CM_ SG_ 313 VZM_Verz_Reg_aktiv "RueckmeldungVerzoegerungsregelungaktiv";
CM_ SG_ 313 VZM_Verz_Reg_nicht_verfuegbar "IndiesemSignalwirdausgegebenobeineVerzögerungsregelungverfügbarist.";
CM_ SG_ 313 VMM_Inkonsistenz_KAS "RückmeldungInkonsistenzKAS";
CM_ SG_ 313 VMM_Bremslicht_unplausibel "BremslichtplausibilitätausBasisderCANAnforderung";
CM_ SG_ 313 VMM_Inkonsistenz_ACC "RückmeldungInkonsistenzACC";
CM_ SG_ 313 VMM_Inkonsistenz_AWV_PCF "RückmeldungInkonsistenzAWVPCF";
CM_ SG_ 313 VMM_Inkonsistenz_ARA "RückmeldungInkonsistenzARA1.0";
CM_ SG_ 313 VMM_Inkonsistenz_ParkAssist "RückmeldungInkonsistenzderParkendenSysteme";
CM_ SG_ 313 VMM_Inkonsistenz_FAS_VK "RückmeldungInkonsistenzFahrerassistenzsystem";
CM_ SG_ 313 VMM_Inkonsistenz_NV "RückmeldungInkonsistenzNightvision";
CM_ SG_ 313 VMM_Inkonsistenz_RCTA "RückmeldungInkonsistenzdesRCTA";
CM_ SG_ 313 VMM_Inkonsistenz_TSK "RückmeldungInkonsistenzTSK";
CM_ SG_ 313 VMM_Inkonsistenz_MO "RückmeldungInkonsistenzMO";
CM_ SG_ 313 VMM_Inkonsistenz_AEB "RückmeldungInkonsistenzvomAEB";
CM_ SG_ 313 VMM_Fahrer_Bremskraft_bestimmend "DiesesSignalgibteineRückmeldungobderFahrerstärkerbremstalsdieangeforderteBremsung.";
CM_ SG_ 313 VMM_Inkonsistenz_EA "RückmeldungInkonsistenzEA";
CM_ SG_ 313 VZM_Status_Wegregelung "RückmeldungderWegregelungobdieserServiceInaktiv,aktivoderpassivist.
Bei Passiv_Überwachend Bremseingriff durch VZM im Notfall möglich.";
CM_ SG_ 313 VZM_Verz_ASIL_Verfuegbarkeit "DiesesSignalgibtdieRückmeldunginwelchemASILBereichaktuellverzögertwird.";
CM_ SG_ 313 VZM_aktives_System "RückmeldungüberdasaktivanforderndeSystembeidemVerzögerungsmanagement.";
CM_ SG_ 313 VZM_Verz_Begrenzung "RückmeldungangeforderteVerzögerungoderSummenradbremsmomentwirdbegrenztumgesetzt";
CM_ SG_ 313 VZM_Systemstatus "IndiesemSignalwirdderaktuelleSystemstatusdesVerzögerungsmanagmentsausgeben.";
CM_ SG_ 313 VZM_SRBM_Soll "GibtdasangeforderteSummenradbremsmomentaus.";
CM_ SG_ 313 VZM_SRBM_Ist "GibtdasaktuelleSummenradbremsmomentaus.";
CM_ SG_ 313 VZM_SRBM_max_Gradient "RückmeldungaktuellerMaximalgradient";
CM_ SG_ 313 VMM_Inkonsistenz_KAM "RückmeldungInkonsistenzderKamera";
CM_ SG_ 2463978663 VZE_Anzeigemodus "SteuertdieverschiedenenMöglichkeitenderAnzeige.";
CM_ SG_ 2463978663 VZE_Hinweistext "ÜberIndexwirdeinHinweistextbeschrieben,derdurchdasKombidargestelltewerdensoll.

Wertebereich lt. Hashtabelle";
CM_ SG_ 2463978663 VZE_Verkehrszeichen_Einheit "SignalgibtanobdasübertrageneVerkehrszeicheninmphoderkm/hübermitteltwird";
CM_ SG_ 2463978663 VZE_Anzeigeunterdrueck_Zeichen_3 "AnzeigerelevanzdesZeichensinVZE_Verkehrszeichen_3";
CM_ SG_ 2463978663 VZE_Anzeigeunterdrueck_Zeichen_2 "AnzeigerelevanzdesZeichensinVZE_Verkehrszeichen_2";
CM_ SG_ 2463978663 VZE_Verkehrszeichen_1 "DasSignalspiegelteinesderVerkehrszeichen:Geschwindigkeitsgebot,Überholverbot,Aufhebungszeichenwider.

Wertebereich lt. Hashtabelle";
CM_ SG_ 2463978663 VZE_Verkehrszeichen_2 "DasSignalspiegelteinesderVerkehrszeichen:Geschwindigkeitsgebot,Überholverbot,Aufhebungszeichenwider.

Wertebereich lt. Hashtabelle";
CM_ SG_ 2463978663 VZE_Verkehrszeichen_3 "DasSignalspiegelteinesderVerkehrszeichen:Geschwindigkeitsgebot,Überholverbot,Aufhebungszeichenwider.

Wertebereich lt. Hashtabelle";
CM_ SG_ 2463978663 VZE_Warnung_Verkehrszeichen_1 "IstdasSignalgesetzt,soistfürdasVerkehrszeichen1eineWarnungauszugeben.";
CM_ SG_ 2463978663 VZE_Warnung_Verkehrszeichen_2 "IstdasSignalgesetzt,soistfürdasVerkehrszeichen2eineWarnungauszugeben.";
CM_ SG_ 2463978663 VZE_Warnung_Verkehrszeichen_3 "IstdasSignalgesetzt,soistfürdasVerkehrszeichen3eineWarnungauszugeben.";
CM_ SG_ 2463978663 VZE_Zusatzschild_1 "Zusatzsschild,daszuVerkehrszeichen1angezeigtwerdensoll.

Wertebereich lt. Hashtabelle";
CM_ SG_ 2463978663 VZE_Zusatzschild_2 "Zusatzsschild,daszuVerkehrszeichen2angezeigtwerdensoll.

Wertebereich lt. Hashtabelle";
CM_ SG_ 2463978663 VZE_Zusatzschild_3 "Zusatzsschild,daszuVerkehrszeichen3angezeigtwerdensoll.

Wertebereich lt. Hashtabelle";
CM_ SG_ 2463978663 VZE_Anzeigeunterdrueck_Zeichen_1 "SteuerungssignalzurSteuerungderSichtbarkeitvonVerkehrszeichen";
CM_ SG_ 2463978663 VZE_Zeichen_01_KameraWied "DasVZE-TempolimitinVerkehrszeichen1wurdealsWiederholungsschildvonderKameraerkannt.";
CM_ SG_ 2463978663 VZE_Zeichen_02_KameraWied "DasVZE-TempolimitinVerkehrszeichen2wurdealsWiederholungsschildvonderKameraerkannt.";
CM_ SG_ 2463978663 VZE_Zeichen_03_KameraWied "DasVZE-TempolimitinVerkehrszeichen3wurdealsWiederholungsschildvonderKameraerkannt.";
CM_ SG_ 2463978663 VZE_Zeichen_01_Kamera "DasVZE-TempolimitinVerkehrszeichen1wurdevonderKameraerkannt.";
CM_ SG_ 2463978663 VZE_Zeichen_01_Karte "DasVZE-TempolimitinVerkehrszeichen1stammtausdenNavigationskartendaten.";
CM_ SG_ 2463978663 VZE_Zeichen_01_Gesetz "DasVZE-TempolimitinVerkehrszeichen1istdasgesetzlichgeltendeTempolimit(jeLand/Straßenklasse).";
CM_ SG_ 2463978663 VZE_Zeichen_02_Kamera "DasVZE-TempolimitinVerkehrszeichen2wurdevonderKameraerkannt.";
CM_ SG_ 2463978663 VZE_Zeichen_02_Karte "DasVZE-TempolimitinVerkehrszeichen2stammtausdenNavigationskartendaten.";
CM_ SG_ 2463978663 VZE_Zeichen_02_Gesetz "DasVZE-TempolimitinVerkehrszeichen2istdasgesetzlichgeltendeTempolimit(jeLand/Straßenklasse).";
CM_ SG_ 2463978663 VZE_Zeichen_03_Kamera "DasVZE-TempolimitinVerkehrszeichen3wurdevonderKameraerkannt.";
CM_ SG_ 2463978663 VZE_Zeichen_03_Karte "DasVZE-TempolimitinVerkehrszeichen3stammtausdenNavigationskartendaten.";
CM_ SG_ 2463978663 VZE_Zeichen_03_Gesetz "DasVZE-TempolimitinVerkehrszeichen3istdasgesetzlichgeltendeTempolimit(jeLand/Straßenklasse).";
CM_ SG_ 2463978663 VZE_Gong "DasSignalsignalisiertdemKombiinstrumentobbeiderVZE-TempowarnungeinGonggetriggertwerdensoll.";
CM_ SG_ 2463978663 VZE_Anzeigeunterdrueck_Zeichen_5 "AnzeigerelevanzdesZeichensinVZE_Anzeigerelevanz_Zeichen_5";
CM_ SG_ 2463978663 VZE_Zeichen_05_KameraWied "DasVZE-TempolimitwurdealsWiederholungsschildvonderKameraerkannt.";
CM_ SG_ 2463978663 VZE_Zeichen_05_Kamera "DasVZE-TempolimitwurdevonderKameraerkannt.";
CM_ SG_ 2463978663 VZE_Verkehrszeichen_4 "DasSignalspiegelteinesderVerkehrszeichen:Geschwindigkeitsgebot,Überholverbot,Aufhebungszeichenwider.

Wertebereich lt. Hashtabelle";
CM_ SG_ 2463978663 VZE_Verkehrszeichen_5 "DasSignalspiegelteinesderVerkehrszeichen:Geschwindigkeitsgebot,Überholverbot,Aufhebungszeichenwider.

Wertebereich lt. Hashtabelle";
CM_ SG_ 2463978663 VZE_Anhaenger_Vmax "ÜbertragungderausKundeneinstellungundländerspezifischenRegelungen(StVO,Rechtsprechung...)berechnetenlegalenHöchstgeschwindigkeitfürdasGespann.

10+ 0*10 = 10 km/h
10+ 1*10 = 20 km/h
...
10+ 5*10 = 60 km/h
10+ 6*10 = 70 km/h
...
10+ 1";
CM_ SG_ 2463978663 VZE_Zeichen_04_Gesetz "DasVZE-TempolimitistdasgesetzlichgeltendeTempolimit(jeLand/Straßenklasse).";
CM_ SG_ 2463978663 VZE_Zeichen_04_Kamera "DasVZE-TempolimitwurdevonderKameraerkannt.";
CM_ SG_ 2463978663 VZE_Zeichen_04_KameraWied "DasVZE-TempolimitwurdealsWiederholungsschildvonderKameraerkannt.";
CM_ SG_ 2463978663 VZE_Zeichen_04_Karte "DasVZE-TempolimitstammtausdenNavigationskartendaten.";
CM_ SG_ 2463978663 VZE_Warnung_Verkehrszeichen_4 "IstdasSignalgesetzt,soistfürdasVerkehrszeichen4eineWarnungauszugeben.";
CM_ SG_ 2463978663 VZE_Warnung_Verkehrszeichen_5 "IstdasSignalgesetzt,soistfürdasVerkehrszeichen5eineWarnungauszugeben.";
CM_ SG_ 2463978663 VZE_Zeichen_05_Gesetz "DasVZE-TempolimitistdasgesetzlichgeltendeTempolimit(jeLand/Straßenklasse).";
CM_ SG_ 2463978663 VZE_Zusatzschild_4 "Zusatzsschild,daszuVerkehrszeichen4angezeigtwerdensoll.

Wertebereich lt. Hashtabelle";
CM_ SG_ 2463978663 VZE_Zusatzschild_5 "Zusatzsschild,daszuVerkehrszeichen5angezeigtwerdensoll.

Wertebereich lt. Hashtabelle";
CM_ SG_ 2463978663 VZE_Baustelle "DasSignalgibtan,obaktuelleinBaustellenschildvonderVZEerkanntwurde.";
CM_ SG_ 2463978663 VZE_Zeichen_05_Karte "DasVZE-TempolimitstammtausdenNavigationskartendaten.";
CM_ SG_ 2463978663 VZE_Zeichen_05_Entfernung "IndemSignalwirddieEntfernungzumVerkehrszeichen5übertragen";
CM_ SG_ 2463978663 VZE_Zeichen_05_Entfernung_StdA "IndemSignalwirddieStandardabweichungbzgl.derEntfernungzumVerkehrszeichen5übertragen";
CM_ SG_ 2463978663 VZE_Anzeigeunterdrueck_Zeichen_4 "AnzeigerelevanzdesZeichensinVZE_Anzeigerelevanz_Zeichen_4";
CM_ SG_ 2463978663 VZE_Verkehrszeichen_6 "DasSignalspiegelteinesderVerkehrszeichen:Geschwindigkeitsgebot,Überholverbot,Aufhebungszeichenwider.

Wertebereich lt. Hashtabelle";
CM_ SG_ 2463978663 VZE_Zusatzschild_6 "Zusatzsschild,daszuVerkehrszeichen6angezeigtwerdensoll.

Wertebereich lt. Hashtabelle";
CM_ SG_ 2463978663 VZE_Zeichen_06_Entfernung "IndemSignalwirddieEntfernungzumVerkehrszeichen6übertragen";
CM_ SG_ 2463978663 VZE_Zeichen_06_Entfernung_StdA "IndemSignalwirddieStandardabweichungbzgl.derEntfernungzumVerkehrszeichen6übertragen";
CM_ SG_ 2463978663 VZE_Umweltinfo_Naesse "IndemSignalwerdenfürdieVerkehrszeichenerkennungrelevanteUmweltinformationenübertragen.

Info: Nässe";
CM_ SG_ 2463978663 VZE_Umweltinfo_Nebel "IndemSignalwerdenfürdieVerkehrszeichenerkennungrelevanteUmweltinformationenübertragen.

Info: Nebel";
CM_ SG_ 2463978663 VZE_Umweltinfo_Anhaengerbetrieb "IndemSignalwerdenfürdieVerkehrszeichenerkennungrelevanteUmweltinformationenübertragen.

Info: Anhängerbetrieb";
CM_ SG_ 2463978663 VZE_Erweiterte_Information "IndemSignalspiegelterweiterteVerkehrszeicheninformationenwieder(Ortsschild,Autobahnbeginn,Autobahnende)

Wertebereich lt. Hashtabelle";
CM_ SG_ 2463978663 VZE_Tempowarnung_Status "0-Tempowarnungaktiv
1 -  Tempowarnung desktiv";
CM_ SG_ 2463978663 VZE_Tempowarnung_Einheit "0-EinheitWarnoffsetkm/h
1 -  Einheit Warnoffset mph";
CM_ SG_ 2463978663 VZE_Tempowarnung_Offset "dasSignalüberträgtdenimCAR:MenügewähltenOffsetfürdieVZE-TempowarnungandaspACCSteuergerät.DiezugrhörigeEinheitwirdimSignalVZE_Tempowarnung_Einheitübertragen";
CM_ SG_ 2463978663 VZE_FoD_Status "StatusderVZEfürFoD";
CM_ SG_ 2463978663 VZE_Anzeige_ZS_1 "Zusatzsschild,daszuVerkehrszeichen1angezeigtwerdensoll.

Wertebereich lt. Hashtabelle";
CM_ SG_ 2463978663 VZE_Anzeige_ZS_2 "Zusatzsschild,daszuVerkehrszeichen1angezeigtwerdensoll.

Wertebereich lt. Hashtabelle";
CM_ SG_ 2463978663 VZE_Anzeige_ZS_3 "Zusatzsschild,daszuVerkehrszeichen1angezeigtwerdensoll.

Wertebereich lt. Hashtabelle";
CM_ SG_ 2463978663 VZE_Hinweistext_03 "ÜberIndexwirdeinHinweistextbeschrieben,derdurchdasKombidargestelltewerdensoll.

Wertebereich lt. Hashtabelle";
CM_ SG_ 2463978663 VZE_Land "SteuertdieverschiedenenMöglichkeitenderAnzeige.";
CM_ SG_ 2463978663 VZE_Warnung_VZ_1 "IstdasSignalgesetzt,soistfürdasVerkehrszeichen1eineWarnungauszugeben.";
CM_ SG_ 2463978663 VZE_Warnung_VZ_2 "IstdasSignalgesetzt,soistfürdasVerkehrszeichen1eineWarnungauszugeben.";
CM_ SG_ 2463978663 VZE_Warnung_VZ_3 "IstdasSignalgesetzt,soistfürdasVerkehrszeichen1eineWarnungauszugeben.";
CM_ SG_ 2463978663 VZE_Anzeige_VZ_1 "DasSignalspiegelteinesderVerkehrszeichen:Geschwindigkeitsgebot,Überholverbot,Aufhebungszeichenwider.

Wertebereich lt. Hashtabelle";
CM_ SG_ 2463978663 VZE_Anzeige_VZ_2 "DasSignalspiegelteinesderVerkehrszeichen:Geschwindigkeitsgebot,Überholverbot,Aufhebungszeichenwider.

Wertebereich lt. Hashtabelle";
CM_ SG_ 2463978663 VZE_Anzeige_VZ_3 "DasSignalspiegelteinesderVerkehrszeichen:Geschwindigkeitsgebot,Überholverbot,Aufhebungszeichenwider.

Wertebereich lt. Hashtabelle";
CM_ SG_ 181 Waehlhebel_04_CRC "FürMLB:
'Berechnung siehe Lastenheft 'Kommunikationsabsicherung für FlexRay und CAN''

Ab MQB und MLBevo:
'Berechnung siehe Lastenheft 'End-to-End Kommunikationsabsicherung''

Endwerte siehe Begleitdokument 'S-PDU Kennungsfolgen'";
CM_ SG_ 181 WH_gespeicherte_Fahrstufe "Kurzzeit-FahrstufenspeicherunginAbhängigkeitvonGE_Ist_Fahrstufe.";
CM_ SG_ 181 WH_Initialisierung "DasBitzeigtdemEmpfängeran,dassderWählhebelinderInitialisierungist(z.B.Reset).DasSignalstehtfürmaximal500msabSendebeginnauf1,danachdauerhaftauf0.";
CM_ SG_ 181 WH_SensorPos_roh "ZustandWählhebelposition.WirddasSignalWH_Variantenichtbedient,istdieSignalcodierung
wie im MQB zu verwenden.

MQB:
0=Init
1=Position_1
2=Position_2
3=Position_3
4=nicht_betaetigt
5=Position_D
6=Position_N
7=Position_R
8=Position_P
";
CM_ SG_ 181 WH_SensorPos_roh_inv "ZustandWählhebelposition.WirddasSignalWH_Variantenichtbedient,istdieSignalcodierung
wie im MQB zu verwenden.

MQB:
0=Fehler
1=Position_Tipp_Gasse
2=Position_L
3=Position_S
4=Position_Tipp_-
5=Position_Tipp_+
6=Position_N_ohne_Spotausl";
CM_ SG_ 181 WH_Testergebnis "Ergebnis(Antwort)desControllertestsinitiertdurchTestFreigabeFlag
und Testparameter 1 + 2";
CM_ SG_ 181 WH_Test_Aktiv "DasBitwirdauf1gesetzt,wenneingültigesTestergebnis(Antwort)gesendetwird.";
CM_ SG_ 181 WH_Ist_Haltemagnet "StatusderAnsteuerungdesParksperren-HaltemagnetenimWaehlhebel";
CM_ SG_ 181 WH_Variante "VerwendeteSchaltungs-VarianteimFahrzeug
Beschreibung:

Rastierter Wählhebel
Übermittlung Absolutpositionen P,R,N,D,S,M

Tasten:
Übermittlung Absolutpositionen P,R,N,D

Monostabil_2x2:
Übermittlung Relativpositionen, Entsperrtaste und P-Taste";
CM_ SG_ 181 WH_Entsperrtaste_02 "DasBitzeigtdenentprelltenStatusderEntsperrtasteamWählhebelan,inklusiveFehler-undInit-Zuständen.";
CM_ SG_ 181 WH_P_Taste "DasSignalzeigtdenStatusderP-Tastean.";
CM_ SG_ 181 WH_Ende_N_Haltephase "SignalisiertdemGetriebe/ASGdasEndederN-Haltephase,damitdieParksperreeingelegtwerdenkann.";
CM_ SG_ 181 WH_Fahrstufe "FahrstufenwunschderSchaltbetätigung(berechnetausFahreraktionamBedienelement)";
CM_ SG_ 181 WH_Status_Shiftlock "StatusdesHardware-Shiftlocks(dieSchaltbetätigungkanninPoderNgesperrtwerden)";
CM_ SG_ 181 WH_Zustand_N_Haltephase "SignalisiertdemSchaltbetätigungsmaster(GSGbzw.ASG),inwelchemZustandsichdieN-HaltephaseinderSchaltbetätigungbefindet.AbhängigdavonfordertderSchaltbetätigungsmsterPanoderbehältNbei.";
CM_ SG_ 2463978687 WH_Fehler_Haltemagnet_Status "StatusdesTests'ElektrischerFehlerHaltemagnetansteuerung'";
CM_ SG_ 2463978687 WH_Fehler_CRC_SBM "FehlerderChecksummedesSchaltbetätigungsmasterserkannt";
CM_ SG_ 2463978687 WH_Fehler_CRC_SBM_Status "StatusdesTests'FehlerderChecksummedesSchaltbetätigungsmasterserkannt'";
CM_ SG_ 2463978687 WH_Fehler_Timeout_SBM "TimeoutdesSchaltbetätigungsmasterserkannt";
CM_ SG_ 2463978687 WH_Fehler_Timeout_SBM_Status "StatusdesTests'TimeoutdesSchaltbetätigungsmasterserkannt'";
CM_ SG_ 2463978687 WH_Fehler_Ueberspannung "Ueberspannungsfehlererkannt";
CM_ SG_ 2463978687 WH_Fehler_Ueberspannung_Status "StatusdesTests'Ueberspannungsfehlererkannt'";
CM_ SG_ 2463978687 WH_Fehler_BZ_SBM "FehlerdesBotschaftszählersdesSchaltbetätigungsmasterserkannt";
CM_ SG_ 2463978687 WH_Fehler_BZ_SBM_Status "StatusdesTests'FehlerdesBotschaftszählersdesSchaltbetätigungsmasterserkannt'";
CM_ SG_ 2463978687 WH_Fehler_Unterspannung "Unterspannungsfehlererkannt";
CM_ SG_ 2463978687 WH_Fehler_Unterspannung_Status "StatusdesTests'Unterspannungsfehlererkannt'";
CM_ SG_ 2463978687 WH_Fehler_Ausleuchtung "FehlerinderAusleuchtungderFahrstufeerkannt";
CM_ SG_ 2463978687 WH_Fehler_Ausleuchtung_Status "StatusdesTests'FehlerinderAusleuchtungderFahrstufeerkannt'";
CM_ SG_ 2463978687 WH_Fehler_Entsperrtaste "FehlerderEntsperrtasteerkannt";
CM_ SG_ 2463978687 WH_Fehler_Entsperrtaste_Status "StatusdesTests'FehlerderEntsperrtasteerkannt'";
CM_ SG_ 2463978687 WH_Fehler_P_Taste "FehlerderP-Tasteerkannt";
CM_ SG_ 2463978687 WH_Fehler_P_Taste_Status "StatusdesTests'FehlerderP-Tasteerkannt'";
CM_ SG_ 2463978687 WH_Fehler_Sensor_einfach "EinfacherPositionssensorfehlererkannt";
CM_ SG_ 2463978687 WH_Fehler_Sensor_einfach_Status "StatusdesTests'einfacherPositionssensorfehlererkannt'";
CM_ SG_ 2463978687 WH_Fehler_Sensor_mehrfach "MehrfacherPositionssensorfehlererkannt";
CM_ SG_ 2463978687 WH_Fehler_Sensor_mehrfach_Status "StatusdesTests'mehrfacherPositionssensorfehlererkannt'";
CM_ SG_ 2463978687 WH_Fehler_Shiftlock "FehlerHardware-Shiftlockerkannt";
CM_ SG_ 2463978687 WH_Fehler_Shiftlock_Status "StatusdesTests'FehlerHardware-Shiftlockerkannt'";
CM_ SG_ 916 WBA_03_CRC "FürMLB:
'Berechnung siehe Lastenheft 'Kommunikationsabsicherung für FlexRay und CAN''

Ab MQB und MLBevo:
'Berechnung siehe Lastenheft 'End-to-End Kommunikationsabsicherung''

Endwerte siehe Begleitdokument 'S-PDU Kennungsfolgen'";
CM_ SG_ 916 WBA_Fahrstufe_02 "BeiAutomatgetriebenwirdindiesemSignaldieaktuelleanzuzeigendeFahrstufeausgegeben.

Die Signalkodierungen 0x9, 0xA und 0xB werden im MSS-R8NF und MQB-A1/B/A2 verwendet.

Die Signalkodierungen 0xC und 0xD werden nur im MQB-A1/B/A2 verwendet.
";
CM_ SG_ 916 WBA_ZielFahrstufe "Zielfahrprogramm(Darstellung),fürgetipptesS/E/MmitneuemWählhebelimMQB";
CM_ SG_ 916 WBA_GE_Warnung_02 "PrioritätswarnungenGetriebe";
CM_ SG_ 916 WBA_eing_Gang_02 "DasAutomatikgetriebegibtdenaktuelleingelegtenGangaus.
Besonderheiten:
0x0 = marktabhängig wird auf Ganganzeige zur Fahrstufe komplett verzichtet
0xA = kurzzeitige Unterdrückung der Ganganzeige (z. B. Segeln, Zwischenstellung, etc.)";
CM_ SG_ 916 WBA_GE_Texte "FahrerhinweisefürdasKombi";
CM_ SG_ 916 WBA_Segeln_aktiv "GetriebegehtindenSegelbetrieb";
CM_ SG_ 916 WBA_Schaltschema_02 "Basis-LayoutdesSchaltschemaszurAnzeigeimKombiinstrument";
CM_ SG_ 916 WBA_Schaltschema_FS_inaktiv "Gibtan,welcheFahrstufeninnerhalbvonWBA_Schaltschema_02aktuellnichterreichbarsind(z.B.aufgrundzuhoherFahrzeuggeschwindigkeitoderfehlenderFahrbereitschaft).";
CM_ SG_ 916 WBA_GE_Zusatzwarnungen "PrioritaetswarnungenGetriebeanKombi
Audi MLB Wertebereich 0 bis 3
VW MQB Projekte verwenden nur den Wertebereich 0 bis 2
VW MQB Getriebefehler werden über das Signal  GE_Warnungen_02 gesendet.";
CM_ SG_ 916 GE_Sollgang "SignalisiertdenSollgang,indengetipptwerdensoll.AbhängigvomSignal'WBA_eing_Gang_02'unddemSollgangkanndanndasKombidieHochschaltempfehlunginTipdarstellen.";
CM_ SG_ 916 GE_Tipschaltempf_verfuegbar "Signalisierung,obeineHochschaltempfehlungimTipmodusverfügbaristodernicht.";
CM_ SG_ 916 WBA_GE_Texte_02 "FahrerhinweisefürdasKombi";
CM_ SG_ 916 WBA_Schaltschema_Tippgasse "ZeigtdenVerbaueinerTippgassezurAnzeigeimSchaltschemaan.";
CM_ SG_ 916 WBA_Schaltschema_Fahreraktion "SignalisiertFahreraktionanderSchaltbetaetigung";
CM_ SG_ 916 WBA_Schaltschema_FS_vorwaerts "Zeigtan,welchederzweiVorwärtsfahrstufenaktivistundobindieinaktivegeschaltetwerdenkann.";
CM_ SG_ 916 WBA_Shiftlock_Lampe "SignalisiertdemKombi,dassdieShiftlock-Lampe(grünes'Bremsetreten'Symbol)anzuzeigenist.

Anmerkung: Signal ist nur von Kombis auszuwerten, die die Shiftlock-Info über Soft- oder Hard-LED und nicht als reine Textmeldung anzeigen.";
CM_ SG_ 916 WBA_Anforderung_Akustik "AnforderungeinesSignaltonsbeiAnwahlderFahrstufeR";
CM_ SG_ 916 WBA_Blinken "DiesesBitsteuertdieFehlerlampeanoderwirdzumBlinkenderWBA-Anzeigegenutzt-nurfallsWBA_Senderkennung=00(GSG)
";
CM_ SG_ 916 GE_Wiederstart_Anz_Std "DiesesSignalgibtdiedetaillierteBegründungfüreinenWiederstartvomGetriebesteuergerätan.";
CM_ SG_ 916 GE_Stoppverbot_Anz_01 "DiesesSignalgibtdiedetaillierteBegründungfüreinStoppverbotvomGetriebesteuergerätan.";
CM_ SG_ 916 GE_Stoppverbot_Anz_02 "DiesesSignalgibtdiedetaillierteBegründungfüreinStoppverbotvomGetriebesteuergerätan.";
CM_ SG_ 916 GE_Stoppverbot_Anz_03 "DiesesSignalgibtdiedetaillierteBegründungfüreinStoppverbotvomGetriebesteuergerätan.";
CM_ SG_ 916 GE_Stoppverbot_Anz_04 "DiesesSignalgibtdiedetaillierteBegründungfüreinStoppverbotvomGetriebesteuergerätan.";
CM_ SG_ 916 GE_Stoppverbot_Anz_05 "DiesesSignalgibtdiedetaillierteBegründungfüreinStoppverbotvomGetriebesteuergerätan.";
CM_ SG_ 916 GE_Stoppverbot_Anz_06 "DiesesSignalgibtdiedetaillierteBegründungfüreinStoppverbotvomGetriebesteuergerätan.";
CM_ SG_ 916 GE_Stoppverbot_Anz_07 "DiesesSignalgibtdiedetaillierteBegründungfüreinStoppverbotvomGetriebesteuergerätan.";
CM_ SG_ 916 GE_Stoppverbot_Anz_Std "DiesesSignalgibtdiedetaillierteBegründungfüreinStoppverbotvomGetriebesteuergerätan.";
CM_ SG_ 1361 WFS_Schluessel_Fahrberecht "SchlüsselnummerFahrberechtigung
0 = ungueltig, xxxx = Schluessel-Nr.";
CM_ SG_ 1361 WFS_Verbauinfo_ELV "InfoüberdieKonfigurationderELVimWFS-Master";
CM_ SG_ 1361 WFS_ID_Geb_autorisiert "AuthorisierungSchluessel(ID-Geber)
";
CM_ SG_ 1361 WFS_ID_Geb_autorisiert_in_Kl15 "AuthorisierungdesSchlüsselsimaktivenKlemme-15-Zyklus";
CM_ SG_ 1361 WFS_ID_Geb_steckt "Schluessel(ID-Geber)imZuendschloss
";
CM_ SG_ 1361 WFS_Schluessel_Soll "SollwertderzulernendenSchluessel";
CM_ SG_ 1361 WFS_Schluessel_Ist "IstwertdergelerntenSchluessel";
CM_ SG_ 1361 WFS_Safe "StatusWFS
";
CM_ SG_ 1361 WFS_LZ "AnforderungausLastenheftWFSV
";
CM_ SG_ 1361 WFS_ELV_authorisiert "AuthorisierungderelektrischenLenkungsverriegelunganderWFS";
CM_ SG_ 1361 WFS_LF_Aktiv "LFSchluesselkommunikation
";
CM_ SG_ 1361 WFS_Betrieb_Lesespule "SchlüsselkommunikationüberdieLesespule";
CM_ SG_ 1361 WFS_Klemmenfreigabe "FreigabevonderWFSzumEinschaltenderKlemme15undKlemmeS";
CM_ SG_ 1361 WFS_Klemmenfreigabe_Signatur "SignaturzurKlemmenfreigabedurchdieWFS";
CM_ SG_ 1361 WFS_Fahrerhinweise "Meldungen,Fahrer-undWarnhinweisederWegfahrsperre";
CM_ SG_ 1361 WFS_Parken_Status "SchnittstellezwischenWFSundZFASfürdasPilotierteParkenuminRichtungZFASdenStatusderWFSimBCM2zukommunizieren";
CM_ SG_ 2617226768 XCP_Motor_CRO_01_Data "INCA->MSG";
CM_ SG_ 2617226769 XCP_Motor_DTO_01_Data "MSG->INCA";
CM_ SG_ 1411 ZV_verriegeln_Anf "GesammelteexterneZV-VerriegelungsanforderungdesKunden(z.B.zurAktivierungderAnzeigedesLadezustandsüberAussenlicht).";
CM_ SG_ 1411 ZV_STSG_HFS_Anf "DieZVforderteinenLaufbzw.StoppderSchiebetüran.";
CM_ SG_ 1411 ZV_STSG_HBFS_Anf "DieZVforderteinenLaufbzw.StoppderSchiebetüran.";
CM_ SG_ 1411 ZV_Anf_Challenge_Auth "AnforderunganallebeteiligtenSteuergerätedieChallengeandenZV-Masterzusenden.";
CM_ SG_ 1411 BCM_FH_Freigabe "FunktionsfreigabeFensterheber";
CM_ SG_ 1411 BCM_Komfortfkt_Freigabe "globaleFreigabederKomfortfunktion";
CM_ SG_ 1411 BCM_HSK_Freigabe "Handschuhkastenfreigabe";
CM_ SG_ 1411 BCM_Verdeck_Freigabe "FreigabeVerdeckbetrieb
";
CM_ SG_ 1411 ZV_verriegelt_intern_ist "Istzustand:VerriegelungFahrzeuginnen
";
CM_ SG_ 1411 ZV_verriegelt_extern_ist "Istzustand:VerriegelungFahrzeugaussen
";
CM_ SG_ 1411 ZV_verriegelt_intern_soll "Sollzustand:VerriegelungFahrzeuginnen
";
CM_ SG_ 1411 ZV_verriegelt_extern_soll "Sollzustand:VerriegelungFahrzeugaussen
";
CM_ SG_ 1411 ZV_gesafet_extern_ist "Istzustand:Fahrzeugaussengesafet
";
CM_ SG_ 1411 ZV_gesafet_extern_soll "Sollzustand:Fahrzeuggesafetextern
";
CM_ SG_ 1411 ZV_Einzeltuerentriegelung "EinzeltürentriegelungZV
";
CM_ SG_ 1411 ZV_Heckeinzelentriegelung "Heckdeckeleinzelentriegelung";
CM_ SG_ 1411 ZV_FT_offen "gespiegeltesBitFT_Tuer_geoeffnetTSG_FT_1Botschaft";
CM_ SG_ 1411 ZV_BT_offen "gespiegeltesBitBT_Tuer_geoeffnetTSG_BT_1Botschaft";
CM_ SG_ 1411 ZV_HFS_offen "gespiegeltesBitHFS_Tuer_geoeffnetTSG_HFS_1Botschaft";
CM_ SG_ 1411 ZV_HBFS_offen "gespiegeltesBitHBFS_Tuer_geoeffnetTSG_HBFS_1Botschaft";
CM_ SG_ 1411 ZV_HD_offen "StatusHeckdeckel
";
CM_ SG_ 1411 ZV_HS_offen "StatusHeckscheibe
";
CM_ SG_ 1411 IRUE_aktiv "StatusInnenraumüberwachung
";
CM_ SG_ 1411 DWA_aktiv "StatusDWA
";
CM_ SG_ 1411 FFB_HDF_Taste "HDFTasteamFunkschluessel
";
CM_ SG_ 1411 FFB_Panik_Taste "PanikTasteFunkschluessel
";
CM_ SG_ 1411 FFB_Auf_Taste "Auf-TasteFunkschluessel

";
CM_ SG_ 1411 FFB_Zu_Taste "Zu-TasteFunkschluessel
";
CM_ SG_ 1411 FFB_CarFinder "CarFinderFunktion(Blinkenohnezuentriegeln)";
CM_ SG_ 1411 FFB_Komfortoeffnen "KomfortoeffnenFunk
";
CM_ SG_ 1411 FFB_Komfortschliessen "KomfortschliessenFunk
";
CM_ SG_ 1411 FBS_IDG_in_Reichweite "FürelektrischbetätigteTürenundKlappenmussfüreineBetätigungüberFunkeineReichweitenbegrenzungeingeführtwerden.DieseBitzeigtan,dasssichderFunkschlüsselinnerhalbdergefordertenReichweitebefindet";
CM_ SG_ 1411 ZV_Schluessel_Zugang "aktuelleFunkschlüsselnummer";
CM_ SG_ 1411 ZV_SafeFunktion_aktiv "StatusübermittlungobdieSafeFunktionimFzg.aktivist.DasKombibenötigtdasSignal,umdenTextSafelockaktivanzuzeigen.";
CM_ SG_ 1411 FBS_Warn_Schluessel_Batt "KombiPrioWarnungSchluesselBatterie
'Bitte Schlüsselbatterie wechseln!'";
CM_ SG_ 1411 ZV_Oeffnungsmodus "KonfigurierterOeffnungsmodusfuerZV:
0 = globale Oeffnung (alle Tueren)
1 = ZV mit Einzeltuerentriegelung (FFB - nur Fahrertuer, Kessy - nur bediente Tuer)
2 = ZV individuell selektive Oeffnung (FFB - Fahrerseite, Kessy - bediente Tuer + Fahrertuer)";
CM_ SG_ 1411 ZV_ist_Zustand_verfuegbar "VerfügbarkeitIST-ZustandZV

";
CM_ SG_ 1411 IRUE_Taster_Fkts_LED "AnforderungFunktions-LEDIRUE-Taster(LEDwirdvomTSGangesteuert)
MQB: Bei Verbau eines einzelnen Taster zur Deaktivierung von IRUE und NGS wird dieses Signal zur Ansteuerung der Funktions-LED gesendet.";
CM_ SG_ 1411 ZV_Tankklappe_offen "ÖffnungsstatusderTankklappe";
CM_ SG_ 1411 ZV_Rollo_auf "KomfortöffnendesDachrollos";
CM_ SG_ 1411 ZV_Rollo_zu "KomfortschließendesDachrollos";
CM_ SG_ 1411 ZV_SAD_auf "KomfortöffnendesSchiebeausstelldaches";
CM_ SG_ 1411 ZV_SAD_zu "KomfortschließendesSchiebeausstelldaches";
CM_ SG_ 1411 ZV_verriegelt_soll "FahrzeugGesamtverriegelungsstatusSollzustandfürLadestecker-undLadeklappenverriegelung.";
BA_DEF_ BO_ "DiagRequest" ENUM "No", "Yes";
BA_DEF_ BO_ "DiagResponse" ENUM "No", "Yes";
BA_DEF_ BO_ "DiagState" ENUM "No", "Yes";
BA_DEF_ BO_ "GenMsgChkConstant" HEX 0 4095;
BA_DEF_ BO_ "GenMsgCycleTime" INT 0 65535;
BA_DEF_ BO_ "GenMsgCycleTimeFast" INT 0 65535;
BA_DEF_ BO_ "GenMsgDelayTime" INT 0 100000;
BA_DEF_ BO_ "GenMsgILSupport" ENUM "No", "Yes";
BA_DEF_ BO_ "GenMsgNrOfRepetition" INT 0 100;
BA_DEF_ BO_ "GenMsgPDUConstants" STRING;
BA_DEF_ BO_ "GenMsgSendType" ENUM "Cyclic", "not_used", "not_used", "not_used", "not_used", "not_used", "not_used", "IfActive", "NoMsgSendType";
BA_DEF_ BO_ "GenMsgStartDelayTime" INT 0 100000;
BA_DEF_ BO_ "NmMessage" ENUM "No", "Yes";
BA_DEF_ BO_ "NmhMessage" ENUM "No", "Yes";
BA_DEF_ BO_ "MsgType" ENUM "Application", "NM", "NMH", "TP2.0", "ISO-TP", "BAP", "EID", "KS";
BA_DEF_ BO_ "VAGTP20_API" HEX 0 255;
BA_DEF_ BO_ "VAGTP20_DynConnection" ENUM "No", "Yes";
BA_DEF_ BO_ "VAGTP20_DynSetup" ENUM "No", "Yes";
BA_DEF_ BO_ "VAGTP20_StatConnection" ENUM "No", "Yes";
BA_DEF_ BO_ "CANFD_BRS" ENUM "0", "1";
BA_DEF_ BO_ "VFrameFormat" ENUM "StandardCAN", "ExtendedCAN", "reserved", "reserved", "reserved", "reserved", "reserved", "reserved", "reserved", "reserved", "reserved", "reserved", "reserved", "reserved", "StandardCAN_FD", "ExtendedCAN_FD";
BA_DEF_ SG_ "GenSigSendType" ENUM "Cyclic", "OnWrite", "OnWriteWithRepetition", "OnChange", "OnChangeWithRepetition", "IfActive", "IfActiveWithRepetition", "NoSigSendType", "OnChangeAndIfActive", "OnChangeAndIfActiveWithRepetition";
BA_DEF_ SG_ "GenSigFuncType" ENUM "NoFunction", "MsgCounter", "CRC-8", "XOR", "XOR-2", "DatedBit", "SW-Kl15", "CHK", "Constant", "Protocol", "CRC-8-SAE_J1850";
BA_DEF_ SG_ "GenSigSwitchedByIgnition" ENUM "No", "Yes";
BA_DEF_DEF_  "DiagRequest" "No";
BA_DEF_DEF_  "DiagResponse" "No";
BA_DEF_DEF_  "DiagState" "No";
BA_DEF_DEF_  "GenMsgChkConstant" 0;
BA_DEF_DEF_  "GenMsgCycleTime" 0;
BA_DEF_DEF_  "GenMsgCycleTimeFast" 0;
BA_DEF_DEF_  "GenMsgDelayTime" 0;
BA_DEF_DEF_  "GenMsgILSupport" "No";
BA_DEF_DEF_  "GenMsgNrOfRepetition" 0;
BA_DEF_DEF_  "GenMsgPDUConstants" "";
BA_DEF_DEF_  "GenMsgSendType" "NoMsgSendType";
BA_DEF_DEF_  "GenMsgStartDelayTime" 0;
BA_DEF_DEF_  "NmMessage" "No";
BA_DEF_DEF_  "NmhMessage" "No";
BA_DEF_DEF_  "MsgType" "Application";
BA_DEF_DEF_  "VAGTP20_API" 0;
BA_DEF_DEF_  "VAGTP20_DynConnection" "No";
BA_DEF_DEF_  "VAGTP20_DynSetup" "No";
BA_DEF_DEF_  "VAGTP20_StatConnection" "No";
BA_DEF_DEF_  "CANFD_BRS" "1";
BA_DEF_DEF_  "VFrameFormat" "StandardCAN";
BA_DEF_DEF_  "GenSigSendType" "NoSigSendType";
BA_DEF_DEF_  "GenSigFuncType" "NoFunction";
BA_DEF_DEF_  "GenSigSwitchedByIgnition" "Yes";
BA_ "GenMsgCycleTime" BO_ 319 200;
BA_ "GenMsgDelayTime" BO_ 319 20;
BA_ "GenMsgILSupport" BO_ 319 "Yes";
BA_ "GenMsgSendType" BO_ 319 "Cyclic";
BA_ "CANFD_BRS" BO_ 319 "0";
BA_ "GenMsgCycleTime" BO_ 1122 150;
BA_ "GenMsgILSupport" BO_ 1122 "Yes";
BA_ "GenMsgSendType" BO_ 1122 "Cyclic";
BA_ "VFrameFormat" BO_ 1122 "StandardCAN_FD";
BA_ "GenMsgCycleTime" BO_ 1123 150;
BA_ "GenMsgILSupport" BO_ 1123 "Yes";
BA_ "GenMsgSendType" BO_ 1123 "Cyclic";
BA_ "VFrameFormat" BO_ 1123 "StandardCAN_FD";
BA_ "GenMsgCycleTime" BO_ 1124 150;
BA_ "GenMsgILSupport" BO_ 1124 "Yes";
BA_ "GenMsgSendType" BO_ 1124 "Cyclic";
BA_ "VFrameFormat" BO_ 1124 "StandardCAN_FD";
BA_ "GenMsgCycleTime" BO_ 591 40;
BA_ "GenMsgILSupport" BO_ 591 "Yes";
BA_ "GenMsgSendType" BO_ 591 "Cyclic";
BA_ "VFrameFormat" BO_ 591 "StandardCAN_FD";
BA_ "DiagRequest" BO_ 2033 "Yes";
BA_ "MsgType" BO_ 2033 "ISO-TP";
BA_ "CANFD_BRS" BO_ 2033 "0";
BA_ "DiagResponse" BO_ 2041 "Yes";
BA_ "MsgType" BO_ 2041 "ISO-TP";
BA_ "CANFD_BRS" BO_ 2041 "0";
BA_ "GenMsgCycleTime" BO_ 980 1000;
BA_ "GenMsgCycleTimeFast" BO_ 980 100;
BA_ "GenMsgDelayTime" BO_ 980 50;
BA_ "GenMsgILSupport" BO_ 980 "Yes";
BA_ "GenMsgNrOfRepetition" BO_ 980 5;
BA_ "GenMsgPDUConstants" BO_ 980 "0xc3,0x79,0xbf,0xdb,0xe9,0x11,0x46,0x86,0x69,0xb6,0x9b,0x29,0x15,0x9c,0x45,0x0d";
BA_ "GenMsgSendType" BO_ 980 "Cyclic";
BA_ "VFrameFormat" BO_ 980 "StandardCAN_FD";
BA_ "GenMsgDelayTime" BO_ 2464153718 50;
BA_ "GenMsgILSupport" BO_ 2464153718 "Yes";
BA_ "VFrameFormat" BO_ 2464153718 "ExtendedCAN_FD";
BA_ "GenMsgDelayTime" BO_ 2464284790 50;
BA_ "GenMsgILSupport" BO_ 2464284790 "Yes";
BA_ "VFrameFormat" BO_ 2464284790 "ExtendedCAN_FD";
BA_ "GenMsgCycleTime" BO_ 1413 1000;
BA_ "GenMsgDelayTime" BO_ 1413 10;
BA_ "GenMsgILSupport" BO_ 1413 "Yes";
BA_ "GenMsgSendType" BO_ 1413 "Cyclic";
BA_ "VFrameFormat" BO_ 1413 "StandardCAN_FD";
BA_ "GenMsgCycleTime" BO_ 2589283396 500;
BA_ "GenMsgILSupport" BO_ 2589283396 "Yes";
BA_ "GenMsgSendType" BO_ 2589283396 "Cyclic";
BA_ "VFrameFormat" BO_ 2589283396 "ExtendedCAN_FD";
BA_ "GenMsgCycleTime" BO_ 1019 80;
BA_ "GenMsgILSupport" BO_ 1019 "Yes";
BA_ "GenMsgSendType" BO_ 1019 "Cyclic";
BA_ "VFrameFormat" BO_ 1019 "StandardCAN_FD";
BA_ "GenMsgCycleTime" BO_ 1716 200;
BA_ "GenMsgILSupport" BO_ 1716 "Yes";
BA_ "GenMsgSendType" BO_ 1716 "Cyclic";
BA_ "VFrameFormat" BO_ 1716 "StandardCAN_FD";
BA_ "GenMsgCycleTime" BO_ 261 20;
BA_ "GenMsgILSupport" BO_ 261 "Yes";
BA_ "GenMsgPDUConstants" BO_ 261 "0xde,0x0e,0xa7,0x1d,0xc3,0x83,0xbd,0x82,0x8c,0xa2,0x0c,0x7b,0x4d,0x3c,0x58,0x79";
BA_ "GenMsgSendType" BO_ 261 "Cyclic";
BA_ "VFrameFormat" BO_ 261 "StandardCAN_FD";
BA_ "GenMsgCycleTime" BO_ 313 20;
BA_ "GenMsgILSupport" BO_ 313 "Yes";
BA_ "GenMsgPDUConstants" BO_ 313 "0xed,0x03,0x1c,0x13,0xc6,0x23,0x78,0x7a,0x8b,0x40,0x14,0x51,0xbf,0x68,0x32,0xba";
BA_ "GenMsgSendType" BO_ 313 "Cyclic";
BA_ "VFrameFormat" BO_ 313 "StandardCAN_FD";
BA_ "GenMsgCycleTime" BO_ 2463978663 200;
BA_ "GenMsgDelayTime" BO_ 2463978663 40;
BA_ "GenMsgILSupport" BO_ 2463978663 "Yes";
BA_ "GenMsgSendType" BO_ 2463978663 "Cyclic";
BA_ "VFrameFormat" BO_ 2463978663 "ExtendedCAN_FD";
BA_ "GenMsgChkConstant" BO_ 181 228;
BA_ "GenMsgCycleTime" BO_ 181 10;
BA_ "GenMsgILSupport" BO_ 181 "Yes";
BA_ "GenMsgPDUConstants" BO_ 181 "0xe4,0xe4,0xe4,0xe4,0xe4,0xe4,0xe4,0xe4,0xe4,0xe4,0xe4,0xe4,0xe4,0xe4,0xe4,0xe4";
BA_ "GenMsgSendType" BO_ 181 "Cyclic";
BA_ "VFrameFormat" BO_ 181 "StandardCAN_FD";
BA_ "GenMsgCycleTime" BO_ 2463978687 1000;
BA_ "GenMsgDelayTime" BO_ 2463978687 100;
BA_ "GenMsgILSupport" BO_ 2463978687 "Yes";
BA_ "GenMsgSendType" BO_ 2463978687 "Cyclic";
BA_ "VFrameFormat" BO_ 2463978687 "ExtendedCAN_FD";
BA_ "GenMsgCycleTime" BO_ 916 160;
BA_ "GenMsgDelayTime" BO_ 916 10;
BA_ "GenMsgILSupport" BO_ 916 "Yes";
BA_ "GenMsgPDUConstants" BO_ 916 "0x47,0x94,0x92,0x6a,0x67,0xb5,0x0d,0x38,0xe3,0x8a,0x5d,0xb4,0x54,0xab,0xae,0x27";
BA_ "GenMsgSendType" BO_ 916 "Cyclic";
BA_ "VFrameFormat" BO_ 916 "StandardCAN_FD";
BA_ "GenMsgCycleTime" BO_ 1361 200;
BA_ "GenMsgDelayTime" BO_ 1361 50;
BA_ "GenMsgILSupport" BO_ 1361 "Yes";
BA_ "GenMsgSendType" BO_ 1361 "Cyclic";
BA_ "VFrameFormat" BO_ 1361 "StandardCAN_FD";
BA_ "MsgType" BO_ 2617028096 "EID";
BA_ "VFrameFormat" BO_ 2617028096 "ExtendedCAN_FD";
BA_ "MsgType" BO_ 2617028097 "EID";
BA_ "VFrameFormat" BO_ 2617028097 "ExtendedCAN_FD";
BA_ "MsgType" BO_ 2617239040 "EID";
BA_ "VFrameFormat" BO_ 2617239040 "ExtendedCAN_FD";
BA_ "MsgType" BO_ 2617239041 "EID";
BA_ "VFrameFormat" BO_ 2617239041 "ExtendedCAN_FD";
BA_ "MsgType" BO_ 2617239042 "EID";
BA_ "VFrameFormat" BO_ 2617239042 "ExtendedCAN_FD";
BA_ "MsgType" BO_ 2617239043 "EID";
BA_ "VFrameFormat" BO_ 2617239043 "ExtendedCAN_FD";
BA_ "MsgType" BO_ 2617239044 "EID";
BA_ "VFrameFormat" BO_ 2617239044 "ExtendedCAN_FD";
BA_ "MsgType" BO_ 2617122304 "EID";
BA_ "VFrameFormat" BO_ 2617122304 "ExtendedCAN_FD";
BA_ "MsgType" BO_ 2617122305 "EID";
BA_ "VFrameFormat" BO_ 2617122305 "ExtendedCAN_FD";
BA_ "MsgType" BO_ 2617122306 "EID";
BA_ "VFrameFormat" BO_ 2617122306 "ExtendedCAN_FD";
BA_ "MsgType" BO_ 2617122307 "EID";
BA_ "VFrameFormat" BO_ 2617122307 "ExtendedCAN_FD";
BA_ "MsgType" BO_ 2617122308 "EID";
BA_ "VFrameFormat" BO_ 2617122308 "ExtendedCAN_FD";
BA_ "MsgType" BO_ 2617226768 "EID";
BA_ "VFrameFormat" BO_ 2617226768 "ExtendedCAN_FD";
BA_ "MsgType" BO_ 2617226769 "EID";
BA_ "VFrameFormat" BO_ 2617226769 "ExtendedCAN_FD";
BA_ "GenMsgCycleTime" BO_ 1411 200;
BA_ "GenMsgCycleTimeFast" BO_ 1411 50;
BA_ "GenMsgDelayTime" BO_ 1411 20;
BA_ "GenMsgILSupport" BO_ 1411 "Yes";
BA_ "GenMsgNrOfRepetition" BO_ 1411 3;
BA_ "GenMsgSendType" BO_ 1411 "Cyclic";
BA_ "VFrameFormat" BO_ 1411 "StandardCAN_FD";
BA_ "GenMsgCycleTime" BO_ 319 200;
BA_ "GenMsgDelayTime" BO_ 319 20;
BA_ "GenMsgILSupport" BO_ 319 "Yes";
BA_ "GenMsgSendType" BO_ 319 "Cyclic";
BA_ "CANFD_BRS" BO_ 319 "0";
BA_ "GenMsgCycleTime" BO_ 1122 150;
BA_ "GenMsgILSupport" BO_ 1122 "Yes";
BA_ "GenMsgSendType" BO_ 1122 "Cyclic";
BA_ "VFrameFormat" BO_ 1122 "StandardCAN_FD";
BA_ "GenMsgCycleTime" BO_ 1123 150;
BA_ "GenMsgILSupport" BO_ 1123 "Yes";
BA_ "GenMsgSendType" BO_ 1123 "Cyclic";
BA_ "VFrameFormat" BO_ 1123 "StandardCAN_FD";
BA_ "GenMsgCycleTime" BO_ 1124 150;
BA_ "GenMsgILSupport" BO_ 1124 "Yes";
BA_ "GenMsgSendType" BO_ 1124 "Cyclic";
BA_ "VFrameFormat" BO_ 1124 "StandardCAN_FD";
BA_ "GenMsgCycleTime" BO_ 591 40;
BA_ "GenMsgILSupport" BO_ 591 "Yes";
BA_ "GenMsgSendType" BO_ 591 "Cyclic";
BA_ "VFrameFormat" BO_ 591 "StandardCAN_FD";
BA_ "DiagRequest" BO_ 2033 "Yes";
BA_ "MsgType" BO_ 2033 "ISO-TP";
BA_ "CANFD_BRS" BO_ 2033 "0";
BA_ "DiagResponse" BO_ 2041 "Yes";
BA_ "MsgType" BO_ 2041 "ISO-TP";
BA_ "CANFD_BRS" BO_ 2041 "0";
BA_ "GenMsgCycleTime" BO_ 980 1000;
BA_ "GenMsgCycleTimeFast" BO_ 980 100;
BA_ "GenMsgDelayTime" BO_ 980 50;
BA_ "GenMsgILSupport" BO_ 980 "Yes";
BA_ "GenMsgNrOfRepetition" BO_ 980 5;
BA_ "GenMsgPDUConstants" BO_ 980 "0xc3,0x79,0xbf,0xdb,0xe9,0x11,0x46,0x86,0x69,0xb6,0x9b,0x29,0x15,0x9c,0x45,0x0d";
BA_ "GenMsgSendType" BO_ 980 "Cyclic";
BA_ "VFrameFormat" BO_ 980 "StandardCAN_FD";
BA_ "GenMsgDelayTime" BO_ 2464153718 50;
BA_ "GenMsgILSupport" BO_ 2464153718 "Yes";
BA_ "VFrameFormat" BO_ 2464153718 "ExtendedCAN_FD";
BA_ "GenMsgDelayTime" BO_ 2464284790 50;
BA_ "GenMsgILSupport" BO_ 2464284790 "Yes";
BA_ "VFrameFormat" BO_ 2464284790 "ExtendedCAN_FD";
BA_ "GenMsgCycleTime" BO_ 1413 1000;
BA_ "GenMsgDelayTime" BO_ 1413 10;
BA_ "GenMsgILSupport" BO_ 1413 "Yes";
BA_ "GenMsgSendType" BO_ 1413 "Cyclic";
BA_ "VFrameFormat" BO_ 1413 "StandardCAN_FD";
BA_ "GenMsgCycleTime" BO_ 2589283396 500;
BA_ "GenMsgILSupport" BO_ 2589283396 "Yes";
BA_ "GenMsgSendType" BO_ 2589283396 "Cyclic";
BA_ "VFrameFormat" BO_ 2589283396 "ExtendedCAN_FD";
BA_ "GenMsgCycleTime" BO_ 1019 80;
BA_ "GenMsgILSupport" BO_ 1019 "Yes";
BA_ "GenMsgSendType" BO_ 1019 "Cyclic";
BA_ "VFrameFormat" BO_ 1019 "StandardCAN_FD";
BA_ "GenMsgCycleTime" BO_ 1716 200;
BA_ "GenMsgILSupport" BO_ 1716 "Yes";
BA_ "GenMsgSendType" BO_ 1716 "Cyclic";
BA_ "VFrameFormat" BO_ 1716 "StandardCAN_FD";
BA_ "GenMsgCycleTime" BO_ 261 20;
BA_ "GenMsgILSupport" BO_ 261 "Yes";
BA_ "GenMsgPDUConstants" BO_ 261 "0xde,0x0e,0xa7,0x1d,0xc3,0x83,0xbd,0x82,0x8c,0xa2,0x0c,0x7b,0x4d,0x3c,0x58,0x79";
BA_ "GenMsgSendType" BO_ 261 "Cyclic";
BA_ "VFrameFormat" BO_ 261 "StandardCAN_FD";
BA_ "GenMsgCycleTime" BO_ 313 20;
BA_ "GenMsgILSupport" BO_ 313 "Yes";
BA_ "GenMsgPDUConstants" BO_ 313 "0xed,0x03,0x1c,0x13,0xc6,0x23,0x78,0x7a,0x8b,0x40,0x14,0x51,0xbf,0x68,0x32,0xba";
BA_ "GenMsgSendType" BO_ 313 "Cyclic";
BA_ "VFrameFormat" BO_ 313 "StandardCAN_FD";
BA_ "GenMsgCycleTime" BO_ 2463978663 200;
BA_ "GenMsgDelayTime" BO_ 2463978663 40;
BA_ "GenMsgILSupport" BO_ 2463978663 "Yes";
BA_ "GenMsgSendType" BO_ 2463978663 "Cyclic";
BA_ "VFrameFormat" BO_ 2463978663 "ExtendedCAN_FD";
BA_ "GenMsgChkConstant" BO_ 181 228;
BA_ "GenMsgCycleTime" BO_ 181 10;
BA_ "GenMsgILSupport" BO_ 181 "Yes";
BA_ "GenMsgPDUConstants" BO_ 181 "0xe4,0xe4,0xe4,0xe4,0xe4,0xe4,0xe4,0xe4,0xe4,0xe4,0xe4,0xe4,0xe4,0xe4,0xe4,0xe4";
BA_ "GenMsgSendType" BO_ 181 "Cyclic";
BA_ "VFrameFormat" BO_ 181 "StandardCAN_FD";
BA_ "GenMsgCycleTime" BO_ 2463978687 1000;
BA_ "GenMsgDelayTime" BO_ 2463978687 100;
BA_ "GenMsgILSupport" BO_ 2463978687 "Yes";
BA_ "GenMsgSendType" BO_ 2463978687 "Cyclic";
BA_ "VFrameFormat" BO_ 2463978687 "ExtendedCAN_FD";
BA_ "GenMsgCycleTime" BO_ 916 160;
BA_ "GenMsgDelayTime" BO_ 916 10;
BA_ "GenMsgILSupport" BO_ 916 "Yes";
BA_ "GenMsgPDUConstants" BO_ 916 "0x47,0x94,0x92,0x6a,0x67,0xb5,0x0d,0x38,0xe3,0x8a,0x5d,0xb4,0x54,0xab,0xae,0x27";
BA_ "GenMsgSendType" BO_ 916 "Cyclic";
BA_ "VFrameFormat" BO_ 916 "StandardCAN_FD";
BA_ "GenMsgCycleTime" BO_ 1361 200;
BA_ "GenMsgDelayTime" BO_ 1361 50;
BA_ "GenMsgILSupport" BO_ 1361 "Yes";
BA_ "GenMsgSendType" BO_ 1361 "Cyclic";
BA_ "VFrameFormat" BO_ 1361 "StandardCAN_FD";
BA_ "MsgType" BO_ 2617028096 "EID";
BA_ "VFrameFormat" BO_ 2617028096 "ExtendedCAN_FD";
BA_ "MsgType" BO_ 2617028097 "EID";
BA_ "VFrameFormat" BO_ 2617028097 "ExtendedCAN_FD";
BA_ "MsgType" BO_ 2617239040 "EID";
BA_ "VFrameFormat" BO_ 2617239040 "ExtendedCAN_FD";
BA_ "MsgType" BO_ 2617239041 "EID";
BA_ "VFrameFormat" BO_ 2617239041 "ExtendedCAN_FD";
BA_ "MsgType" BO_ 2617239042 "EID";
BA_ "VFrameFormat" BO_ 2617239042 "ExtendedCAN_FD";
BA_ "MsgType" BO_ 2617239043 "EID";
BA_ "VFrameFormat" BO_ 2617239043 "ExtendedCAN_FD";
BA_ "MsgType" BO_ 2617239044 "EID";
BA_ "VFrameFormat" BO_ 2617239044 "ExtendedCAN_FD";
BA_ "MsgType" BO_ 2617122304 "EID";
BA_ "VFrameFormat" BO_ 2617122304 "ExtendedCAN_FD";
BA_ "MsgType" BO_ 2617122305 "EID";
BA_ "VFrameFormat" BO_ 2617122305 "ExtendedCAN_FD";
BA_ "MsgType" BO_ 2617122306 "EID";
BA_ "VFrameFormat" BO_ 2617122306 "ExtendedCAN_FD";
BA_ "MsgType" BO_ 2617122307 "EID";
BA_ "VFrameFormat" BO_ 2617122307 "ExtendedCAN_FD";
BA_ "MsgType" BO_ 2617122308 "EID";
BA_ "VFrameFormat" BO_ 2617122308 "ExtendedCAN_FD";
BA_ "MsgType" BO_ 2617226768 "EID";
BA_ "VFrameFormat" BO_ 2617226768 "ExtendedCAN_FD";
BA_ "MsgType" BO_ 2617226769 "EID";
BA_ "VFrameFormat" BO_ 2617226769 "ExtendedCAN_FD";
BA_ "GenMsgCycleTime" BO_ 1411 200;
BA_ "GenMsgCycleTimeFast" BO_ 1411 50;
BA_ "GenMsgDelayTime" BO_ 1411 20;
BA_ "GenMsgILSupport" BO_ 1411 "Yes";
BA_ "GenMsgNrOfRepetition" BO_ 1411 3;
BA_ "GenMsgSendType" BO_ 1411 "Cyclic";
BA_ "VFrameFormat" BO_ 1411 "StandardCAN_FD";
VAL_ 319 PreCrash_Charisma_FahrPr 0 "keine_Funktion" 1 "Programm_1" 2 "Programm_2" 3 "Programm_3" 4 "Programm_4" 5 "Programm_5" 6 "Programm_6" 7 "Programm_7" 8 "Programm_8" 9 "Programm_9" 10 "Programm_10" 11 "Programm_11" 12 "Programm_12" 13 "Programm_13" 14 "Programm_14" 15 "Programm_15";
VAL_ 319 PreCrash_Charisma_Status 0 "Init" 1 "verfuegbar" 2 "nicht_verfuegbar" 3 "asynchron_durch_Fahrerwunsch";
VAL_ 319 PreCrash_Schiebedach_schliessen 0 "keine_Schliessung" 1 "Schliessung_angefordert";
VAL_ 319 PreCrash_Fenster_schliessen 0 "keine_Schliessung" 1 "Schliessung_angefordert";
VAL_ 319 PreCrash_Blinken 0 "keine_Blinkanforderung" 1 "Warnblinken" 2 "RECAS_Blinken" 3 "Notbremsblinken";
VAL_ 319 SC_PreSense_FCWP 0 "Warnung_gilt_fuer_Objekte" 1 "Warnung_gitl_fuer_Fussgaenger";
VAL_ 319 PreCrash_Tueren_Verriegeln 0 "keine_Anforderung" 1 "Tueren_Verriegeln";
VAL_ 319 PreCrash_FS_Laengsverstellung 0 "nicht_angefordert" 1 "angefordert";
VAL_ 319 PreCrash_Anforderung_AFR 0 "keine_Anforderung" 1 "linke_Seite" 2 "rechte_Seite" 3 "Vorderachse" 4 "Hinterachse" 5 "Vorwarnung" 7 "Init";
VAL_ 319 SC_PreCrash_LED 0 "keine_Anzeige" 1 "Stufe_1_glimmen" 2 "Stufe_2_leuchten" 3 "Stufe_3_blinken";
VAL_ 319 PreCrash_FS_Pneumatik_ansteuern 0 "keine_Anforderung" 1 "Pneumatik_ansteuern";
VAL_ 319 PreCrash_BFS_Pneumatik_ansteuern 0 "keine_Anforderung" 1 "Pneumatik_ansteuern";
VAL_ 319 PreCrash_Fo_Pneumatik_ansteuern 0 "keine_Anforderung" 1 "Pneumatik_ansteuern";
VAL_ 319 PreCrash_FS_Sitzlehne_verfahren 0 "keine_Anforderung" 1 "Sitzlehne_in_pos_x-Richtung_verfahren(vor)" 2 "Sitzlehne_in_neg_x-Richtung_verfahren(zurueck)" 3 "Sitzlehnenkopf_in_pos_x-Richtung_verfahren(vor)" 4 "Sitzlehnenkopf_in_neg_x-Richtung_verfahren(zurueck)" 6 "Lehnenverstellung_ansteuern" 7 "Lehnenkopfverstellung_ansteuern";
VAL_ 319 PreCrash_BFS_Sitzlehne_verfahren 0 "keine_Anforderung" 1 "Sitzlehne_in_pos_x-Richtung_verfahren(vor)" 2 "Sitzlehne_in_neg_x-Richtung_verfahren(zurueck)" 3 "Sitzlehnenkopf_in_pos_x-Richtung_verfahren(vor)" 4 "Sitzlehnenkopf_in_neg_x-Richtung_verfahren(zurueck)" 6 "Lehnenverstellung_ansteuern" 7 "Lehnenkopfverstellung_ansteuern";
VAL_ 319 PreCrash_Fo_Sitzlehne_verfahren 0 "keine_Anforderung" 1 "Sitzlehne_in_pos_x-Richtung_verfahren(vor)" 2 "Sitzlehne_in_neg_x-Richtung_verfahren(zurueck)" 3 "Sitzlehnenkopf_in_pos_x-Richtung_verfahren(vor)" 4 "Sitzlehnenkopf_in_neg_x-Richtung_verfahren(zurueck)";
VAL_ 319 PreCrash_FS_KSV_verfahren 0 "keine_Anforderung" 1 "in_pos_x-Richtung_verfahren" 2 "in_neg_x-Richung_verfahren" 3 "in_pos_z-Richtung_verfahren" 4 "in_neg_z-Richtung_verfahren" 5 "in_pos_x-Richtung_und_neg_z-Richtung_verfahren" 6 "in_pos_x_Richtung_und_pos_z-Richtung_verfahren" 7 "in_neg_x-Richtung_und_neg_z-Richtung_verfahren" 8 "in_neg_x-Richtung_und_pos_z-Richtung_verfahren" 9 "Kopfstuetze_ansteuern";
VAL_ 319 PreCrash_BFS_KSV_verfahren 0 "keine_Anforderung" 1 "in_pos_x-Richtung_verfahren" 2 "in_neg_x-Richung_verfahren" 3 "in_pos_z-Richtung_verfahren" 4 "in_neg_z-Richtung_verfahren" 5 "in_pos_x-Richtung_und_neg_z-Richtung_verfahren" 6 "in_pos_x_Richtung_und_pos_z-Richtung_verfahren" 7 "in_neg_x-Richtung_und_neg_z-Richtung_verfahren" 8 "in_neg_x-Richtung_und_pos_z-Richtung_verfahren" 9 "Kopfstuetze_ansteuern";
VAL_ 319 PreCrash_Fo_KSV_verfahren 0 "keine_Anforderung" 1 "in_pos_x-Richtung_verfahren" 2 "in_neg_x-Richung_verfahren" 3 "in_pos_z-Richtung_verfahren" 4 "in_neg_z-Richtung_verfahren" 5 "in_pos_x-Richtung_und_neg_z-Richtung_verfahren" 6 "in_pos_x_Richtung_und_pos_z-Richtung_verfahren" 7 "in_neg_x-Richtung_und_neg_z-Richtung_verfahren" 8 "in_neg_x-Richtung_und_pos_z-Richtung_verfahren";
VAL_ 319 PreCrash_BFS_Laengsverstellung 0 "nicht_angefordert" 1 "angefordert";
VAL_ 319 SC_PreCrash_Warnung 0 "keine_Anzeige" 1 "latente_Vorwarnung" 2 "Vorwarnung" 3 "Akutwarnung" 4 "Eingriff" 5 "Fahreruebernahmeaufforderung" 6 "Abbiegewarnung" 7 "Basiseingriff" 8 "Heckeingriff";
VAL_ 319 SC_PreCrash_Texte 0 "keine_Anzeige" 1 "Systemstoerung" 2 "keine_Sensorsicht" 3 "Demomodus" 4 "System_aus" 5 "Anhaengerbetrieb" 6 "ESC_aus" 7 "zurzeit_eingeschraenkt" 8 "zurzeit_eingeschraenkt_ESP_Aus" 9 "Initialisierung";
VAL_ 1122 PSD_Segment_ID 0 "keine Segmentinformationen vorhanden" 1 "Fehlerwert";
VAL_ 1122 PSD_Vorgaenger_Segment_ID 0 "keine Segmentinformation vorhanden" 1 "Fehlerwert";
VAL_ 1122 PSD_Strassenkategorie 0 "Rest_Feldweg_Schotterweg_Privatweg" 1 "Ortsstraße" 2 "Kreisstraße" 3 "Landstraße" 4 "Bundesstraße" 5 "Autobahn" 7 "Init";
VAL_ 1122 PSD_Endkruemmung 255 "Gerade";
VAL_ 1122 PSD_Endkruemmung_Vorz 0 "Kruemmung_positiv" 1 "Kruemmung_negativ";
VAL_ 1122 PSD_Idenditaets_ID 0 "keine_Segment_Informationen_vorhanden" 1 "Fehler";
VAL_ 1122 PSD_ADAS_Qualitaet 0 "keine_ADAS_Qualitaet" 1 "ADAS_Qualitaet";
VAL_ 1122 PSD_wahrscheinlichster_Pfad 0 "Pfad_mit_geringer_Wahrscheinlichkeit" 1 "wahrscheinlichster_Pfad";
VAL_ 1122 PSD_Geradester_Pfad 0 "nicht_geradester_PFad" 1 "geradester_Pfad";
VAL_ 1122 PSD_Fahrspuren_Anzahl 0 "Einbahnstrasse_in_falsche_Richtung" 1 "eine_Fahrspur" 2 "zwei_Fahrspuren" 3 "drei_Fahrspuren" 4 "vier_Fahrspuren" 5 "fuenf_Fahrspuren" 6 "sechs_Fahrspuren" 7 "mehr_als_sechs_Fahrspuren";
VAL_ 1122 PSD_Bebauung 0 "ausserhalb_bebauten_Gebietes" 1 "innerhalb_bebauten_Gebietes";
VAL_ 1122 PSD_Segment_Komplett 0 "Segment_Attribute_nicht_komplett" 1 "Segment_Attribute_komplett";
VAL_ 1122 PSD_Rampe 0 "Strasse_mit_Gegenverkehr" 1 "Auffahrt_Einbahnstr" 2 "Abfahrt_Einbahnstr" 3 "Einbahnstrasse";
VAL_ 1122 PSD_Anfangskruemmung 255 "Gerade";
VAL_ 1122 PSD_Anfangskruemmung_Vorz 0 "positiv" 1 "negativ";
VAL_ 1122 PSD_Abzweigerichtung 0 "rects_abzweigende_Strasse" 1 "links_abzweigende_Strasse";
VAL_ 1123 PSD_Pos_Segment_ID 0 "keine Position gegeben" 1 "Fehlerwert";
VAL_ 1123 PSD_Pos_Standort_Eindeutig 0 "mehrdeutiger_Standort" 1 "eindeutiger_Standort";
VAL_ 1123 PSD_Pos_Fehler_Laengsrichtung 0 "Init" 1 "< 2m" 2 "< 5m" 3 "< 10m" 4 "< 20m" 5 "< 50m" 6 "> 50m" 7 "Off-Road";
VAL_ 1123 PSD_Pos_Fahrspur 0 "unbekannt" 1 "Erste_Spur_von_rechts" 2 "Zweite_Spur_von_rechts" 3 "Dritte_Spur_von_rechts" 4 "Vierte_Spur_von_rechts" 5 "Fuenfte_Spur_von_rechts" 6 "Sechte_Spur_von_rechts" 7 "Siebte_oder_weitere_Spur_von_rechts";
VAL_ 1123 PSD_Attribut_Segment_ID_05 0 "keine_Segment_Information" 1 "Fehler";
VAL_ 1123 PSD_Attribut_1_ID 0 "keine_Information";
VAL_ 1123 PSD_Attribut_2_ID 0 "keine_Information";
VAL_ 1123 PSD_Attribute_Komplett_05 0 "Attribute_nicht_komplett" 1 "Attribute_komplett";
VAL_ 1124 PSD_06_Mux 0 "Init";
VAL_ 1124 PSD_Sys_Segment_ID 0 "keine Segmentinformationen vorhanden" 1 "nicht zulaessig";
VAL_ 1124 PSD_Attribut_Segment_ID 0 "keine_Segment_Information_vorhanden" 1 "Fehler";
VAL_ 1124 PSD_Ges_Segment_ID 0 "keine Segmentinformationen vorhanden" 1 "nicht zulaessig";
VAL_ 1124 PSD_Baum_Laenge_VZ 0 "Ost" 1 "West";
VAL_ 1124 PSD_Steigung_1_Segment_ID 0 "keine_Segment_Information_vorhanden" 1 "Fehler";
VAL_ 1124 PSD_Baum_Laenge 33554431 "keine_GPS_Information";
VAL_ 1124 PSD_Attribut_3_ID 0 "keine_Information";
VAL_ 1124 PSD_Steigung_1_A_Steigung 126 "mehr_als_15_Prozent" 127 "Steigung_unbekannt";
VAL_ 1124 PSD_Ges_Geschwindigkeit 0 "Kein Geschwindigkeitsgebot" 1 "0 km/h < v_max <  5 km/h" 2 "5 km/h < v_max < 10km/h" 3 "10 km/h < v_max < 15 km/h" 4 "15 km/h < v_max < 20 km/h" 5 "20 km/h < v_max < 25 km/h" 6 "25 km/h < v_max < 30 km/h" 7 "30 km/h < v_max < 35 km/h" 8 "35 km/h < v_max < 40 km/h" 9 "40 km/h < v_max < 45 km/h" 10 "45 km/h < v_max < 50 km/h" 11 "50 km/h < v_max < 60 km/h" 12 "60 km/h < v_max < 70 km/h" 13 "70 km/h < v_max < 80 km/h" 14 "80 km/h < v_max < 90 km/h" 15 "90 km/h < v_max < 100 km/h" 16 "100 km/h < v_max < 110 km/h" 17 "110 km/h < v_max < 120 km/h" 18 " 120 km/h < v_max < 130 km/h" 19 "130 km/h < v_max < 140 km/h" 20 "140 km/h < v_max < 150 km/h" 21 "150 km/h < v_max < 160 km/h" 22 "160 km/h < v_max" 23 "Geschwindigkeitsgebot aufgehoben" 24 "..0x1F ungültig";
VAL_ 1124 PSD_Steigung_1_A_Vorz 0 "Gefaelle" 1 "Steigung";
VAL_ 1124 PSD_Sys_Geschwindigkeit_Einheit 0 "km/h" 1 "mph";
VAL_ 1124 PSD_Sys_Verkehrsrichtung 0 "Rechtsverkehr" 1 "Linksverkehr";
VAL_ 1124 PSD_Sys_Geometrieguete 0 "Geringe_Guete" 1 "tbd" 2 "tbd" 3 "Hohe_Guete";
VAL_ 1124 PSD_Sys_Mapmatchingguete 0 "geringe_Guete" 1 "res" 2 "res" 3 "hohe_Guete";
VAL_ 1124 PSD_Ges_Typ 0 "Geschw_Klasse_des_Kartendatensuppliers" 1 "Explizit_abgeleiteten_Begrenzung" 2 "Durch_Gesetzg_vorgeg_allgem_Gebot_fuer_uebertr_Rahmenbed" 3 "Init";
VAL_ 1124 PSD_Sys_Alter_Karte 0 "kleiner_1_Jahr" 1 "1_Jahr" 2 "2_Jahre" 3 "3_Jahre" 4 "4_Jahre" 5 "5_Jahre" 6 "6_Jahre" 7 "groesser_7_Jahre";
VAL_ 1124 PSD_Ges_Spur_Geschw_Begrenzung 0 "Gebot_fuer_alle_spuren_gueltig";
VAL_ 1124 PSD_Steigung_1_B_Steigung 126 "mehr_als_15_Prozent" 127 "Steigung_unbekannt";
VAL_ 1124 PSD_Attribut_4_ID 0 "keine_Information";
VAL_ 1124 PSD_Sys_Zielfuehrung 0 "Zielfuehrung nicht aktiv" 1 "Zielfuehrung aktiv";
VAL_ 1124 PSD_Sys_US_State 0 "kein_US_State" 1 "Alabama" 2 "Alaska" 3 "Arkansas" 4 "Arizona" 5 "California" 6 "Colorado" 7 "Conneticut" 8 "District_of_Columbia" 9 "Delaware" 10 "Florida" 11 "Georgia" 12 "Hawaii" 13 "Idaho" 14 "Illinois" 15 "Iowa" 16 "Indiana" 17 "Kansas" 18 "Kentucky" 19 "Louisiana" 20 "Massachusetts" 21 "Maryland" 22 "Maine" 23 "Michigan" 24 "Minnesota" 25 "Missouri" 26 "Mississippi" 27 "Montana" 28 "North_Carolina" 29 "North_Dakota" 30 "Nebraska" 31 "Nevada" 32 "New_Hampshire" 33 "New_Jersey" 34 "New_Mexico" 35 "New_York" 36 "Ohio" 37 "Oklahoma" 38 "Oregon" 39 "Pennsylvania" 40 "Puerto_Rico" 41 "Rhode_Island" 42 "South_Carolina" 43 "South_Dakota" 44 "Tennessee" 45 "Texas" 46 "Utah" 47 "Virginia" 48 "Virgin_Islands" 49 "Vermont" 50 "Washington" 51 "Wisconsin" 52 "West_Virginia" 53 "Wyoming";
VAL_ 1124 PSD_Ges_Geschwindigkeit_Gespann 0 "alle Fahrzeuge" 1 "PKW mit Gespann" 2 "LKW, Busse, etc.";
VAL_ 1124 PSD_Baum_Breite_VZ 0 "Nord" 1 "Sued";
VAL_ 1124 PSD_Ges_Geschwindigkeit_Witter 0 "Witterungsunabhängig" 1 "Nässe, Regen, Niederschlag" 2 "Glätte" 3 "Nebel";
VAL_ 1124 PSD_Steigung_1_B_Vorz 0 "Gefaelle" 1 "Steigung";
VAL_ 1124 PSD_Ges_Geschwindigkeit_Tag_Anf 0 "kein Beginn definiert" 1 "Montag" 2 "Dienstag" 3 "Mittwoch" 4 "Donnerstag" 5 "Freitag" 6 "Samstag" 7 "Sonntag";
VAL_ 1124 PSD_Ges_Geschwindigkeit_Tag_Ende 0 "kein Ende definiert" 1 "Montag" 2 "Dienstag" 3 "Mittwoch" 4 "Donnerstag" 5 "Freitag" 6 "Samstag" 7 "Sonntag";
VAL_ 1124 PSD_Sys_Quali_verfuegbar 0 "Qualitaetskriterien_nicht_verfuegbar" 1 "Qualitaetskriterien_verfuegbar";
VAL_ 1124 PSD_Sys_Zielfuehrung_geaendert 0 "Zielfuehrung_nicht_geaendert" 1 "Zielfuehrung_geaendert";
VAL_ 1124 PSD_Ges_Geschwindigkeit_Std_Anf 25 "kein Beginn für stundenweise Einschränkungen";
VAL_ 1124 PSD_Steigung_1_Attribute_kompl 0 "Steigungen_nicht_komplett" 1 "Steigungen_komplett";
VAL_ 1124 PSD_Sys_Geometrieguete_erweitert 0 "Init";
VAL_ 1124 PSD_Steigung_2_Segment_ID 0 "keine_Segment_Information_vorhanden" 1 "Fehler";
VAL_ 1124 PSD_Attribut_5_ID 0 "keine_Information";
VAL_ 1124 PSD_Ges_Geschwindigkeit_Std_Ende 25 "kein Ende für stundenweise Einschränkungen";
VAL_ 1124 PSD_Steigung_2_Steigung 126 "mehr_als_15_Prozent" 127 "Steigung_unbekannt";
VAL_ 1124 PSD_Ges_Ueberholverbot 0 "kein Überholverbot" 1 "alle Fahrzeuge" 2 "Überholverbot für PKW mit Gespann" 3 "Überholverbot für LKW, Busse, etc.";
VAL_ 1124 PSD_Ges_Wechselverkehrszeichen 0 "Kein Wechselverkehrszeichen" 1 "Wechselverkehrszeichen links" 2 "Wechselverkehrszeichen rechts" 3 "Wechselverkehrszeichen links und rechts" 4 "Wechselverkerhszeichen über der Fahrbahn";
VAL_ 1124 PSD_Steigung_2_Vorz 0 "Gefaelle" 1 "Steigung";
VAL_ 1124 PSD_Wechselverkehrszeichen_Typ 0 "kein_Wechselverkehrszeichen" 1 "LED_Wechselverkehrszeichen" 2 "nicht_LED_Wechselverkehrszeichen";
VAL_ 1124 PSD_Ges_Gesetzlich_Kategorie 0 "kein_legales_Verbot" 1 "innerorts" 2 "ausserorts" 3 "Autobahn";
VAL_ 1124 PSD_Attribute_Komplett_06 0 "Attribute_nicht_komplett" 1 "Attribute_komplett";
VAL_ 1124 PSD_Ges_Gesetzlich_Zusatz 0 "kein_Zusatz_zu_legalem_Gebot" 1 "Anhaenger_Klasse_1" 2 "Anhaenger_Klasse_2";
VAL_ 1124 PSD_Ges_Verkehrszeichen_Quelle 0 "VZA_kein_Onlinedienst" 1 "nur_VZA" 2 "nur_VZO" 3 "VZA_und_VZO";
VAL_ 1124 PSD_Steigung_2_Attribute_kompl 0 "Steigungen_nicht_komplett" 1 "Steigungen_komplett";
VAL_ 1124 PSD_Ges_Attribute_Komplett 0 "Attribute_nicht_komplett" 1 "Attribute_komplett";
VAL_ 591 RDR1_relevanter_Fehler 0 "kein_relevanter_Fehler" 1 "relevanter_Fehler";
VAL_ 591 RDR1_Blindheit_erkannt 0 "keine_Blindheit_erkannt" 1 "Blindheit_erkannt";
VAL_ 591 RDR1_relev_Nichtverfuegbarkeit 0 "verfuegbar" 1 "nicht_verfuegbar";
VAL_ 591 RDR1_Verkehrssinn 0 "init" 1 "Linksverkehr" 2 "Rechtsverkehr" 3 "Unbekannt";
VAL_ 591 RDR1_Objekte_02_Datenalter 1023 "Daten_aelter_als_Maximum";
VAL_ 591 RDR1_Obj_01_ax_v 255 "Init";
VAL_ 591 RDR1_Obj_01_ax_StdA 63 "Init";
VAL_ 591 RDR1_Obj_01_vx_StdA 127 "Init";
VAL_ 591 RDR1_Obj_01_dx_StdA 127 "Init";
VAL_ 591 RDR1_Obj_01_dy_StdA 127 "Init";
VAL_ 980 BH_Blinker_li 0 "nicht_betaetigt" 1 "Blinkerhebel_Richtung_links_betaetigt";
VAL_ 980 BH_Blinker_re 0 "nicht_betaetigt" 1 "Blinkerhebel_Richtung_rechts_betaetigt";
VAL_ 980 BH_Lichthupe 0 "nicht_betaetigt" 1 "Blinkerhebel in Richtung Lichthupe betaetigt";
VAL_ 980 BH_Fernlicht 0 "nicht_betaetigt" 1 "Blinkerhebel_in_Richtung_Fernlicht_betaetigt";
VAL_ 980 WH_Tipwischen 0 "nicht_betaetigt" 1 "betaetigt";
VAL_ 980 WH_Intervall 0 "aus" 1 "Wischerhebel in Stellung Intervall";
VAL_ 980 WH_WischerStufe1 0 "aus" 1 "Wischerhebel in Stufe Wischen 1";
VAL_ 980 WH_WischerStufe2 0 "aus" 1 "Wischerhebel in Stufe Wischen 2";
VAL_ 980 WH_Frontwaschen 0 "aus" 1 "Wischerhebel in Stellung Wisch Wasch vorne";
VAL_ 980 WH_Heckintervall 0 "nicht_betaetigt" 1 "Wischerhebel in Stellung Heckintervall";
VAL_ 980 WH_Heckwaschen 0 "nicht_betaetigt" 1 "Wischerhebel in Stellung Wisch Wasch hinten";
VAL_ 980 WH_Intervallstufen 0 "Init / Default" 9 "Intervallstufe 3" 1 "Intervallstufe 1" 13 "Intervallstufe 4" 5 "Intervallstufe 2" 15 "Fehler";
VAL_ 980 FAS_Taster 0 "nicht_betaetigt" 1 "betaetigt";
VAL_ 980 FAS_Taster_Fehler 0 "kein_Fehler" 1 "Fehler";
VAL_ 980 SMLS_Hupe 0 "nicht_betaetigt" 1 "Hupe_gedrueckt";
VAL_ 980 LRH_on_off 0 "LRH_aus__keine Anzeige" 1 "LRH_aus" 2 "LRH_ein" 3 "Fehler";
VAL_ 980 LSS_Tastencode 0 "Key_Released__No_Key" 4 "Up" 5 "Down" 7 "OK__ThumbWheel_Button";
VAL_ 980 LRH_aktiv 0 "inaktiv" 1 "aktiv";
VAL_ 980 SMLS_P_verriegelt 0 "Init" 1 "nicht_verriegelt" 2 "verriegelt" 3 "Fehler";
VAL_ 980 SMLS_P_verriegelt_plausibel 0 "unplausibel" 1 "plausibel";
VAL_ 980 WH_SRA 0 "SRA_Aus" 1 "SRA_Ein";
VAL_ 980 WH_Wischer_Fehler 0 "kein_Fehler" 1 "Fehler";
VAL_ 980 BH_Blinker_Fehler 0 "kein_Fehler" 1 "Fehler";
VAL_ 980 SMLS_PTT 0 "nicht_betaetigt" 1 "PTT_gedrueckt";
VAL_ 980 WH_Tipwischen_lang 0 "nicht_betaetigt" 1 "betaetigt";
VAL_ 1413 SI_Sammel_SG_Fehler 61 "Reserviert" 62 "Overflow" 63 "ungueltig";
VAL_ 1413 SI_P_Mode_gueltig 0 "dezentraler_Produktionsmode" 1 "zentraler_Produktionsmode";
VAL_ 1413 SI_Diagnose_Aktiv 0 "inaktiv" 1 "aktiv";
VAL_ 1413 SI_QRS_Mode 0 "QRS_Messmodus_nicht_aktiv" 1 "QRS_Messmodus_aktiv";
VAL_ 1413 SI_T_Mode 0 "Transportmodus_nicht_aktiv" 1 "Transportmodus_aktiv";
VAL_ 1413 SI_NWDF 0 "Ueberwachung_nicht_freigegeben" 1 "Ueberwachung_freigegeben";
VAL_ 1413 SI_NWDF_gueltig 0 "NWDF_wird_nicht_unterstuetzt" 1 "NWDF_wird_unterstuetzt";
VAL_ 1413 SI_Sammelfehler 0 "kein_Sammelfehler" 1 "Sammelfehler";
VAL_ 1413 GW_KD_Fehler 0 "kein_KD_Fehler" 1 "KD_Fehler";
VAL_ 1413 SI_T_Schutz 0 "Transportschutz_nicht_aktiv" 1 "Transportschutz_aktiv";
VAL_ 1413 SI_P_Mode 0 "inaktiv" 1 "aktiv";
VAL_ 1413 SI_BUS_01 0 "keine_Busruhe" 1 "Busruhe";
VAL_ 1413 SI_BUS_02 0 "keine_Busruhe" 1 "Busruhe";
VAL_ 1413 SI_BUS_03 0 "keine_Busruhe" 1 "Busruhe";
VAL_ 1413 SI_BUS_04 0 "keine_Busruhe" 1 "Busruhe";
VAL_ 1413 SI_BUS_05 0 "keine_Busruhe" 1 "Busruhe";
VAL_ 1413 SI_BUS_06 0 "keine_Busruhe" 1 "Busruhe";
VAL_ 1413 SI_BUS_07 0 "keine_Busruhe" 1 "Busruhe";
VAL_ 1413 SI_BUS_08 0 "keine_Busruhe" 1 "Busruhe";
VAL_ 1413 SI_BUS_09 0 "keine_Busruhe" 1 "Busruhe";
VAL_ 1413 SI_BUS_10 0 "keine_Busruhe" 1 "Busruhe";
VAL_ 1413 SI_BUS_11 0 "keine_Busruhe" 1 "Busruhe";
VAL_ 1413 SI_BUS_12 0 "keine_Busruhe" 1 "Busruhe";
VAL_ 1413 SI_BUS_13 0 "keine_Busruhe" 1 "Busruhe";
VAL_ 1413 SI_BUS_14 0 "keine_Busruhe" 1 "Busruhe";
VAL_ 1413 SI_BUS_15 0 "keine_Busruhe" 1 "Busruhe";
VAL_ 1413 SI_Bus_Identifikation 16 "CAN_Diagnose" 17 "CAN_Antrieb" 18 "CAN_Komfort" 19 "CAN_Infotainment" 20 "CAN_Fahrwerk" 21 "CAN_Extended" 22 "CAN_Hybrid" 23 "CAN_Lade" 24 "CAN_Kombi" 25 "CAN_Komfort_2" 26 "CAN_AFS" 97 "VLAN_FAS" 33 "CAN_FahrerAssistenzSysteme" 98 "VLAN_Infotainment" 34 "CAN_Migration" 99 "VLAN_Connect" 35 "CAN_Connect" 100 "VLAN_Komfort" 36 "CAN_AnzeigeBedienung" 101 "VLAN_Antrieb" 37 "CAN_ElectricalVehicle" 104 "VLAN_Gateway" 40 "CAN_Telematik" 105 "VLAN_Remote_FC" 41 "CAN_MFL" 48 "FlexRay_A" 49 "FlexRay_B" 102 "VLAN_Diagnose" 103 "VLAN_Internet" 106 "VLAN_Connect_2";
VAL_ 1413 SI_CAB_V10 32768 "CAB_16_Licht" 16384 "CAB_15_Laden" 128 "CAB_08_MIB" 0 "Init" 64 "CAB_07_Connect" 8192 "CAB_14_VLAN_Infotainment" 32 "CAB_06_Anzeige" 4096 "CAB_13_VLAN_Connect" 16 "CAB_05_Komfort" 8 "CAB_04_Fahrerassistenz" 1 "CAB_01_Antrieb" 2 "CAB_02_Hybrid_Laden" 4 "CAB_03_Fahrwerk" 256 "CAB_09_Standheizung" 1024 "CAB_11_VLAN_Fahrerassistenz";
VAL_ 2589283396 TSK_vMax_EfficiencyMode1 254 "kein_Limit_aktiv" 255 "Init";
VAL_ 2589283396 TSK_vMax_EfficiencyMode2 254 "kein_Limit_aktiv" 255 "Init";
VAL_ 2589283396 TSK_vMax_StandardMode 254 "kein_Limit_aktiv" 255 "Init";
VAL_ 1019 TSK_Ausrollkurve_Schub_Reku_01 127 "Init";
VAL_ 1019 TSK_Ausrollkurve_Schub_Reku_05 127 "Init";
VAL_ 1019 TSK_Ausrollkurve_Schub_Reku_09 127 "Init";
VAL_ 1019 TSK_Ausrollkurve_Schub_Reku_13 127 "Init";
VAL_ 1019 TSK_Ausrollkurve_Schub_Reku_17 127 "Init";
VAL_ 1019 TSK_Ausrollkurve_Schub_Reku_02 127 "Init";
VAL_ 1019 TSK_Ausrollkurve_Schub_Reku_06 127 "Init";
VAL_ 1019 TSK_Ausrollkurve_Schub_Reku_10 127 "Init";
VAL_ 1019 TSK_Ausrollkurve_Schub_Reku_14 127 "Init";
VAL_ 1019 TSK_Ausrollkurve_Schub_Reku_18 127 "Init";
VAL_ 1019 TSK_Ausrollkurve_Schub_Reku_03 127 "Init";
VAL_ 1019 TSK_Ausrollkurve_Schub_Reku_07 127 "Init";
VAL_ 1019 TSK_Ausrollkurve_Schub_Reku_11 127 "Init";
VAL_ 1019 TSK_Ausrollkurve_Schub_Reku_15 127 "Init";
VAL_ 1019 TSK_Ausrollkurve_Schub_Reku_19 127 "Init";
VAL_ 1019 TSK_Ausrollkurve_Schub_Reku_04 127 "Init";
VAL_ 1019 TSK_Ausrollkurve_Schub_Reku_08 127 "Init";
VAL_ 1019 TSK_Ausrollkurve_Schub_Reku_12 127 "Init";
VAL_ 1019 TSK_Ausrollkurve_Schub_Reku_16 127 "Init";
VAL_ 1019 TSK_Ausrollkurve_Schub_Reku_20 127 "Init";
VAL_ 1019 TSK_Ausrollkurve_Segeln_01 127 "Init";
VAL_ 1019 TSK_Ausrollkurve_Segeln_05 127 "Init";
VAL_ 1019 TSK_Ausrollkurve_Segeln_09 127 "Init";
VAL_ 1019 TSK_Ausrollkurve_Segeln_13 127 "Init";
VAL_ 1019 TSK_Ausrollkurve_Segeln_17 127 "Init";
VAL_ 1019 TSK_Ausrollkurve_Segeln_02 127 "Init";
VAL_ 1019 TSK_Ausrollkurve_Segeln_06 127 "Init";
VAL_ 1019 TSK_Ausrollkurve_Segeln_10 127 "Init";
VAL_ 1019 TSK_Ausrollkurve_Segeln_14 127 "Init";
VAL_ 1019 TSK_Ausrollkurve_Segeln_18 127 "Init";
VAL_ 1019 TSK_Ausrollkurve_Segeln_03 127 "Init";
VAL_ 1019 TSK_Ausrollkurve_Segeln_07 127 "Init";
VAL_ 1019 TSK_Ausrollkurve_Segeln_11 127 "Init";
VAL_ 1019 TSK_Ausrollkurve_Segeln_15 127 "Init";
VAL_ 1019 TSK_Ausrollkurve_Segeln_19 127 "Init";
VAL_ 1019 TSK_Ausrollkurve_Segeln_04 127 "Init";
VAL_ 1019 TSK_Ausrollkurve_Segeln_08 127 "Init";
VAL_ 1019 TSK_Ausrollkurve_Segeln_12 127 "Init";
VAL_ 1019 TSK_Ausrollkurve_Segeln_16 127 "Init";
VAL_ 1019 TSK_Ausrollkurve_Segeln_20 127 "Init";
VAL_ 1019 TSK_Ausrollkurve_Reku 0 "Rekuperation_nicht_beruecksichtigt" 1 "Rekuperation_beruecksichtigt";
VAL_ 1019 TSK_Ausrollkurve_Schrittweite 0 "Normale_Schrittweite" 1 "Grosse_Schrittweite";
VAL_ 261 HMS_P_beibehalten_GE 0 "P_nicht_beibehalten" 1 "P_beibehalten" 2 "Init" 3 "Fehler";
VAL_ 261 VZM_Unterdrueckung_Antriebsmom 0 "Pos_Antriebsmoment_moeglich" 1 "Pos_Antriebsmoment_unterdruecken";
VAL_ 261 HMS_halten_nicht_verfuegbar 0 "verfuegbar" 1 "nicht_verfuegbar";
VAL_ 261 HMS_parken_nicht_verfuegbar 0 "verfuegbar" 1 "nicht_verfuegbar";
VAL_ 261 HMS_Anforderung_GE 0 "keine_Anforderung" 1 "P_einlegen";
VAL_ 261 HMS_Systemstatus 0 "keine_Funktion_aktiv" 1 "Halten_aktiv" 2 "Parken_angefordert" 3 "Parken_aktiv" 4 "Parken_beibehalten_aktiv" 5 "Anfahren_aktiv" 6 "Loeseanforderung_aktiv" 7 "Loeseanforderung_durch_Fahrer" 8 "Abrutschen_erkannt" 9 "Halten_Standby_aktiv" 10 "Anfahren_Standby_aktiv" 14 "Init" 15 "Fehler";
VAL_ 261 HMS_Stillstand 0 "kein_Stillstand" 1 "Stillstand_frueh" 2 "Stillstand" 6 "Init" 7 "Fehler";
VAL_ 261 HMS_aktives_System 0 "kein_System__Init_Fehler" 1 "Fahreranforderung_aktiv" 2 "HMS_intern_aktiv" 3 "ACC_aktiv" 4 "Autohold_aktiv" 5 "HHC_aktiv" 6 "HVLM_aktiv" 7 "Getriebe_aktiv" 8 "EBKV_aktiv" 9 "ParkAssist_aktiv" 10 "ARA_aktiv" 12 "autonomous_Hold_aktiv" 13 "STA_aktiv" 14 "Motor_aktiv" 15 "EA_aktiv" 16 "VLK_aktiv";
VAL_ 261 VMM_Inkonsistenz_GE 0 "konsistent" 1 "nicht_konsistent";
VAL_ 261 VMM_Inkonsistenz_HVLM 0 "konsistent" 1 "nicht_konsistent";
VAL_ 261 HMS_Fehlerstatus 0 "kein_Fehler" 1 "Halten_nicht_moeglich" 2 "Sonderbetriebsmodus_aktiv" 3 "Systemeinschraenkung" 4 "Systemstoerung";
VAL_ 261 HMS_Index_Haltemoment 0 "Bremsmoment" 1 "Antriebsmoment";
VAL_ 261 HMS_Haltemoment 1022 "Init" 1023 "Fehler";
VAL_ 313 VZM_aktiver_Basisservice 0 "Keine_Aktivitaet" 1 "Bremsenkonditionierung" 2 "Bremsruck" 3 "Verzoegerungsregelung" 4 "Wegregelung";
VAL_ 313 VZM_Anhalteweg_nicht_verfuegbar 0 "verfuegbar" 1 "nicht_verfuegbar";
VAL_ 313 VZM_Fahrer_bremst 0 "Bremsdruckschwelle_nicht_ueberschritten" 1 "Bremsdruckschwelle_ueberschritten";
VAL_ 313 VZM_QBit_Fahrer_bremst 0 "gueltiger_Wert" 1 "Ersatz_Init_oder_Fehlerwert";
VAL_ 313 VMM_MKB_codiert 0 "MKB_nicht_codiert" 1 "MKB_codiert";
VAL_ 313 VMM_Inkonsistenz_EBKV 0 "konsistent" 1 "nicht_konsistent";
VAL_ 313 VMM_Notstopp_Status 0 "Init" 1 "verfuegbar" 2 "warten_auf_sekundaer_System" 3 "passiv_Ueberwachung" 4 "aktiv_ausgeloest" 7 "Fehler";
VAL_ 313 VZM_Warnruck_nicht_verfuegbar 0 "verfuegbar" 1 "nicht_verfuegbar";
VAL_ 313 VZM_Warnruckeln_nicht_verfuegbar 0 "verfuegbar" 1 "nicht_verfuegbar";
VAL_ 313 VZM_Bkd_nicht_verfuegbar 0 "verfuegbar" 1 "nicht_verfuegbar";
VAL_ 313 VMM_Bremslicht_defekt 0 "Bremslichter_nicht_defekt" 1 "Bremslichter_defekt";
VAL_ 313 VZM_Fahrer_bremst_deutlich 0 "Fahrer_bremst_nicht_deutlich" 1 "Fahrer_bremst_deutlich";
VAL_ 313 VZM_TSK_SRBM_Anf 0 "keine_Aktivitaet" 1 "Aktivitaet_durch_TSK";
VAL_ 313 VZM_TSK_SRBM_nicht_verfuegbar 0 "verfuegbar" 1 "nicht_verfuegbar";
VAL_ 313 VZM_Verz_Reg_aktiv 8 "Aktivitaet_durch_ARA" 0 "keine_Aktivitaet" 2 "Aktivitaet_durch_AWV_PCF" 3 "Aktivitaet_durch_EA" 4 "Aktivitaet_durch_TSK" 5 "Aktivitaet_durch_RCTA" 6 "Aktivitaet_durch_ParkAssist" 7 "Aktivitaet_durch_ACC" 9 "Aktivitaet_durch_NV" 10 "Aktivitaet_durch_KAS" 11 "Aktivitaet_durch_FAS_VK" 12 "Aktivitaet_durch_vESC" 13 "Aktivitaet_durch_KAM" 14 "Aktivitaet_durch_BRS_intern" 15 "Aktivitaet_durch_AEB" 16 "Aktivitaet_durch_MKB";
VAL_ 313 VZM_Verz_Reg_nicht_verfuegbar 0 "verfuegbar" 1 "nicht_verfuegbar";
VAL_ 313 VMM_Inkonsistenz_KAS 0 "konsistent" 1 "nicht_konsistent";
VAL_ 313 VMM_Bremslicht_unplausibel 0 "plausibel" 1 "unplausibel";
VAL_ 313 VMM_Inkonsistenz_ACC 0 "konsistent" 1 "nicht_konsistent";
VAL_ 313 VMM_Inkonsistenz_AWV_PCF 0 "konsistent" 1 "nicht_konsistent";
VAL_ 313 VMM_Inkonsistenz_ARA 0 "konsistent" 1 "nicht_konsistent";
VAL_ 313 VMM_Inkonsistenz_ParkAssist 0 "konsistent" 1 "nicht_konsistent";
VAL_ 313 VMM_Inkonsistenz_FAS_VK 0 "konsistent" 1 "nicht_konsistent";
VAL_ 313 VMM_Inkonsistenz_NV 0 "konsistent" 1 "nicht_konsistent";
VAL_ 313 VMM_Inkonsistenz_RCTA 0 "konsistent" 1 "nicht_konsistent";
VAL_ 313 VMM_Inkonsistenz_TSK 0 "konsistent" 1 "nicht_konsistent";
VAL_ 313 VMM_Inkonsistenz_MO 0 "konsistent" 1 "nicht_konsistent";
VAL_ 313 VMM_Inkonsistenz_AEB 0 "konsistent" 1 "nicht_konsistent";
VAL_ 313 VMM_Fahrer_Bremskraft_bestimmend 0 "Nicht_Bremskraft_bestimmend" 1 "Bremskraft_bestimmend";
VAL_ 313 VMM_Inkonsistenz_EA 0 "konsistent" 1 "nicht_konsistent";
VAL_ 313 VZM_Status_Wegregelung 0 "Inaktiv" 1 "Passiv" 2 "Aktiv" 3 "Passiv_Ueberwachend";
VAL_ 313 VZM_Verz_ASIL_Verfuegbarkeit 0 "Nicht_verfuegbar" 1 "Verfuegbar_ab_ASIL_QM" 2 "Verfuegbar_ab_ASIL_A" 3 "Verfuegbar_ab_ASIL_B" 4 "Verfuegbar_ab_ASIL_C";
VAL_ 313 VZM_aktives_System 0 "Kein_aktiver_Teilnehmer" 1 "VZM_intern" 2 "AWV_PCF" 3 "EA" 4 "TSK" 5 "RCTA" 6 "ParkAssist" 7 "ACC" 8 "ARA" 9 "NV" 10 "KAS" 11 "FAS_VK" 12 "vESC" 13 "KAM" 14 "reserviert" 15 "AEB" 16 "MKB";
VAL_ 313 VZM_Verz_Begrenzung 0 "keine_Begrenzung" 1 "Begrenzung_aktiv";
VAL_ 313 VZM_Systemstatus 0 "Initialisierung" 1 "Verfuegbar" 2 "Verfuegbar_eingeschr_Performance" 3 "Nicht_Verfuegbar" 4 "Fehler" 5 "Sonderbetriebsmodus";
VAL_ 313 VZM_SRBM_Soll 4094 "Init" 4095 "Fehler";
VAL_ 313 VZM_SRBM_Ist 4094 "Init" 4095 "Fehler";
VAL_ 313 VZM_SRBM_max_Gradient 126 "Init" 127 "Fehler";
VAL_ 313 VMM_Inkonsistenz_KAM 0 "konsistent" 1 "nicht_konsistent";
VAL_ 2463978663 VZE_Anzeigemodus 0 "EU_RDW" 1 "USA" 2 "Canada" 3 "China";
VAL_ 2463978663 VZE_Hinweistext 0 "kein_Hinweistext";
VAL_ 2463978663 VZE_Verkehrszeichen_Einheit 0 "kmh" 1 "mph";
VAL_ 2463978663 VZE_Anzeigeunterdrueck_Zeichen_3 0 "anzeigerelevant" 1 "nicht_anzeigerelevant";
VAL_ 2463978663 VZE_Anzeigeunterdrueck_Zeichen_2 0 "anzeigerelevant" 1 "nicht_anzeigerelevant";
VAL_ 2463978663 VZE_Verkehrszeichen_1 0 "kein_Verkehrszeichen";
VAL_ 2463978663 VZE_Verkehrszeichen_2 0 "kein_Verkehrszeichen";
VAL_ 2463978663 VZE_Verkehrszeichen_3 0 "kein_Verkehrszeichen";
VAL_ 2463978663 VZE_Warnung_Verkehrszeichen_1 0 "keine_Warnung_Initialwert_Fehlerwert" 1 "Warnung";
VAL_ 2463978663 VZE_Warnung_Verkehrszeichen_2 0 "keine_Warnung_Initialwert_Fehlerwert" 1 "Warnung";
VAL_ 2463978663 VZE_Warnung_Verkehrszeichen_3 0 "keine_Warnung_Initialwert_Fehlerwert" 1 "Warnung";
VAL_ 2463978663 VZE_Zusatzschild_1 0 "keine_Zusatzschild_Initialwert_Fehlerwert";
VAL_ 2463978663 VZE_Zusatzschild_2 0 "keine_Zusatzschild_Initialwert_Fehlerwert";
VAL_ 2463978663 VZE_Zusatzschild_3 0 "keine_Zusatzschild_Initialwert_Fehlerwert";
VAL_ 2463978663 VZE_Anzeigeunterdrueck_Zeichen_1 0 "anzeigerelevant" 1 "nicht_anzeigerelevant";
VAL_ 2463978663 VZE_Zeichen_01_KameraWied 0 "inaktiv" 1 "aktiv";
VAL_ 2463978663 VZE_Zeichen_02_KameraWied 0 "inaktiv" 1 "aktiv";
VAL_ 2463978663 VZE_Zeichen_03_KameraWied 0 "inaktiv" 1 "aktiv";
VAL_ 2463978663 VZE_Zeichen_01_Kamera 0 "nicht_erkannt" 1 "erkannt";
VAL_ 2463978663 VZE_Zeichen_01_Karte 0 "inaktiv" 1 "aktiv";
VAL_ 2463978663 VZE_Zeichen_01_Gesetz 0 "nicht_erkannt" 1 "erkannt";
VAL_ 2463978663 VZE_Zeichen_02_Kamera 0 "nicht_erkannt" 1 "erkannt";
VAL_ 2463978663 VZE_Zeichen_02_Karte 0 "inaktiv" 1 "aktiv";
VAL_ 2463978663 VZE_Zeichen_02_Gesetz 0 "nicht_erkannt" 1 "erkannt";
VAL_ 2463978663 VZE_Zeichen_03_Kamera 0 "nicht_erkannt" 1 "erkannt";
VAL_ 2463978663 VZE_Zeichen_03_Karte 0 "inaktiv" 1 "aktiv";
VAL_ 2463978663 VZE_Zeichen_03_Gesetz 0 "nicht_erkannt" 1 "erkannt";
VAL_ 2463978663 VZE_Gong 0 "Gong_deaktiv" 1 "Gong_aktiv";
VAL_ 2463978663 VZE_Anzeigeunterdrueck_Zeichen_5 0 "anzeigerelevant" 1 "nicht_anzeigerelevant";
VAL_ 2463978663 VZE_Zeichen_05_KameraWied 0 "inaktiv" 1 "aktiv";
VAL_ 2463978663 VZE_Zeichen_05_Kamera 0 "nicht_erkannt" 1 "erkannt";
VAL_ 2463978663 VZE_Verkehrszeichen_4 0 "kein_Verkehrszeichen";
VAL_ 2463978663 VZE_Verkehrszeichen_5 0 "kein_Verkehrszeichen";
VAL_ 2463978663 VZE_Anhaenger_Vmax 14 "Init" 15 "Fehler";
VAL_ 2463978663 VZE_Zeichen_04_Gesetz 0 "nicht_erkannt" 1 "erkannt";
VAL_ 2463978663 VZE_Zeichen_04_Kamera 0 "nicht_erkannt" 1 "erkannt";
VAL_ 2463978663 VZE_Zeichen_04_KameraWied 0 "inaktiv" 1 "aktiv";
VAL_ 2463978663 VZE_Zeichen_04_Karte 0 "inaktiv" 1 "aktiv";
VAL_ 2463978663 VZE_Warnung_Verkehrszeichen_4 0 "keine_Warnung_Initialwert_Fehlerwert" 1 "Warnung";
VAL_ 2463978663 VZE_Warnung_Verkehrszeichen_5 0 "keine_Warnung_Initialwert_Fehlerwert" 1 "Warnung";
VAL_ 2463978663 VZE_Zeichen_05_Gesetz 0 "nicht_erkannt" 1 "erkannt";
VAL_ 2463978663 VZE_Zusatzschild_4 0 "keine_Zusatzschild_Initialwert_Fehlerwert";
VAL_ 2463978663 VZE_Zusatzschild_5 0 "keine_Zusatzschild_Initialwert_Fehlerwert";
VAL_ 2463978663 VZE_Baustelle 0 "Keine_Baustelle" 1 "Baustelle_erkannt";
VAL_ 2463978663 VZE_Zeichen_05_Karte 0 "inaktiv" 1 "aktiv";
VAL_ 2463978663 VZE_Zeichen_05_Entfernung 0 "Init";
VAL_ 2463978663 VZE_Zeichen_05_Entfernung_StdA 0 "Init";
VAL_ 2463978663 VZE_Anzeigeunterdrueck_Zeichen_4 0 "anzeigerelevant" 1 "nicht_anzeigerelevant";
VAL_ 2463978663 VZE_Verkehrszeichen_6 0 "kein_Verkehrszeichen";
VAL_ 2463978663 VZE_Zusatzschild_6 0 "keine_Zusatzschild_Initialwert_Fehlerwert";
VAL_ 2463978663 VZE_Zeichen_06_Entfernung 0 "Init";
VAL_ 2463978663 VZE_Zeichen_06_Entfernung_StdA 0 "Init";
VAL_ 2463978663 VZE_Umweltinfo_Naesse 0 "inaktiv" 1 "aktiv";
VAL_ 2463978663 VZE_Umweltinfo_Nebel 0 "inaktiv" 1 "aktiv";
VAL_ 2463978663 VZE_Umweltinfo_Anhaengerbetrieb 0 "inaktiv" 1 "aktiv";
VAL_ 2463978663 VZE_Erweiterte_Information 0 "keine_Information";
VAL_ 2463978663 VZE_Tempowarnung_Status 0 "inaktiv" 1 "aktiv";
VAL_ 2463978663 VZE_Tempowarnung_Einheit 0 "kmh" 1 "mph";
VAL_ 2463978663 VZE_Tempowarnung_Offset 0 "Init";
VAL_ 2463978663 VZE_FoD_Status 0 "Init" 1 "Funktion_inaktiv" 2 "Funktion_aktiv";
VAL_ 2463978663 VZE_Anzeige_ZS_1 0 "Init";
VAL_ 2463978663 VZE_Anzeige_ZS_2 0 "Init";
VAL_ 2463978663 VZE_Anzeige_ZS_3 0 "Init";
VAL_ 2463978663 VZE_Hinweistext_03 0 "kein_Hinweistext";
VAL_ 2463978663 VZE_Land 0 "Init";
VAL_ 2463978663 VZE_Warnung_VZ_1 0 "keine_Warnung" 1 "Warnung";
VAL_ 2463978663 VZE_Warnung_VZ_2 0 "keine_Warnung" 1 "Warnung";
VAL_ 2463978663 VZE_Warnung_VZ_3 0 "keine_Warnung" 1 "Warnung";
VAL_ 2463978663 VZE_Anzeige_VZ_1 0 "kein_Verkehrszeichen";
VAL_ 2463978663 VZE_Anzeige_VZ_2 0 "kein_Verkehrszeichen";
VAL_ 2463978663 VZE_Anzeige_VZ_3 0 "kein_Verkehrszeichen";
VAL_ 181 WH_gespeicherte_Fahrstufe 0 "keine_Speicherung" 1 "P" 2 "R" 3 "N" 4 "D" 5 "S" 6 "Tipp_Gasse";
VAL_ 181 WH_Initialisierung 0 "keine Initphase" 1 "Initphase";
VAL_ 181 WH_SensorPos_roh 0 "Init" 1 "Pos_1" 2 "Pos_2" 3 "Pos_3" 4 "Pos_4" 5 "Pos_5" 6 "Pos_6" 7 "Pos_7" 8 "Pos_8" 9 "Pos_9" 10 "Pos_10" 11 "Pos_11" 12 "Pos_12" 13 "Pos_13" 14 "Pos_14" 15 "Fehler";
VAL_ 181 WH_SensorPos_roh_inv 0 "Fehler" 1 "Pos_14" 2 "Pos_13" 3 "Pos_12" 4 "Pos_11" 5 "Pos_10" 6 "Pos_9" 7 "Pos_8" 8 "Pos_7" 9 "Pos_6" 10 "Pos_5" 11 "Pos_4" 12 "Pos_3" 13 "Pos_2" 14 "Pos_1" 15 "Init";
VAL_ 181 WH_Test_Aktiv 0 "kein Testergebnis" 1 "Testergebnis";
VAL_ 181 WH_Ist_Haltemagnet 0 "Init__nicht_verbaut" 1 "haelt_nicht" 2 "haelt" 3 "Fehler";
VAL_ 181 WH_Variante 0 "Init" 1 "Rastierter_Waehlhebel" 2 "Tasten" 4 "Monostabil_2x2" 5 "Sport_Tasten" 6 "Monostabil_2x2_reduziert" 7 "Monostabil_2x2_Walzensegment";
VAL_ 181 WH_Entsperrtaste_02 0 "Init_nicht_verbaut" 1 "nicht_betaetigt" 2 "betaetigt" 3 "Fehler";
VAL_ 181 WH_P_Taste 0 "Init" 1 "nicht_betaetigt" 2 "betaetigt" 3 "Fehler";
VAL_ 181 WH_Ende_N_Haltephase 0 "nicht_aktiv" 1 "aktiv";
VAL_ 181 WH_Fahrstufe 8 "P" 0 "Init" 4 "nicht_betaetigt" 5 "D" 6 "N" 7 "R" 9 "N_ohne_Spotausleuchtung" 10 "Tipp_Plus" 11 "Tipp_Minus" 12 "S" 14 "Tipp_Gasse" 15 "Fehler";
VAL_ 181 WH_Status_Shiftlock 0 "Init" 2 "WH_freigegeben" 3 "WH_gesperrt" 6 "Shiftlock_nicht_verbaut" 7 "Fehler";
VAL_ 181 WH_Zustand_N_Haltephase 0 "inaktiv" 1 "aktiv__Timer_laeuft" 2 "beendet__Timer_abgelaufen" 3 "beendet__P_Taste_betaetigt";
VAL_ 2463978687 WH_Fehler_Haltemagnet_Status 0 "Test_nicht_durchgefuehrt" 1 "Test_durchgefuehrt";
VAL_ 2463978687 WH_Fehler_CRC_SBM 0 "Fehler_passiv" 1 "Fehler_aktiv";
VAL_ 2463978687 WH_Fehler_CRC_SBM_Status 0 "Test_nicht_durchgefuehrt" 1 "Test_durchgefuehrt";
VAL_ 2463978687 WH_Fehler_Timeout_SBM 0 "Fehler_passiv" 1 "Fehler_aktiv";
VAL_ 2463978687 WH_Fehler_Timeout_SBM_Status 0 "Test_nicht_durchgefuehrt" 1 "Test_durchgefuehrt";
VAL_ 2463978687 WH_Fehler_Ueberspannung 0 "Fehler_passiv" 1 "Fehler_aktiv";
VAL_ 2463978687 WH_Fehler_Ueberspannung_Status 0 "Test_nicht_durchgefuehrt" 1 "Test_durchgefuehrt";
VAL_ 2463978687 WH_Fehler_BZ_SBM 0 "Fehler_passiv" 1 "Fehler_aktiv";
VAL_ 2463978687 WH_Fehler_BZ_SBM_Status 0 "Test_nicht_durchgefuehrt" 1 "Test_durchgefuehrt";
VAL_ 2463978687 WH_Fehler_Unterspannung 0 "Fehler_passiv" 1 "Fehler_aktiv";
VAL_ 2463978687 WH_Fehler_Unterspannung_Status 0 "Test_nicht_durchgefuehrt" 1 "Test_durchgefuehrt";
VAL_ 2463978687 WH_Fehler_Ausleuchtung 0 "Fehler_passiv" 1 "Fehler_aktiv";
VAL_ 2463978687 WH_Fehler_Ausleuchtung_Status 0 "Test_nicht_durchgefuehrt" 1 "Test_durchgefuehrt";
VAL_ 2463978687 WH_Fehler_Entsperrtaste 0 "Fehler_passiv" 1 "Fehler_aktiv";
VAL_ 2463978687 WH_Fehler_Entsperrtaste_Status 0 "Test_nicht_durchgefuehrt" 1 "Test_durchgefuehrt";
VAL_ 2463978687 WH_Fehler_P_Taste 0 "Fehler_passiv" 1 "Fehler_aktiv";
VAL_ 2463978687 WH_Fehler_P_Taste_Status 0 "Test_nicht_durchgefuehrt" 1 "Test_durchgefuehrt";
VAL_ 2463978687 WH_Fehler_Sensor_einfach 0 "Fehler_passiv" 1 "Fehler_aktiv";
VAL_ 2463978687 WH_Fehler_Sensor_einfach_Status 0 "Test_nicht_durchgefuehrt" 1 "Test_durchgefuehrt";
VAL_ 2463978687 WH_Fehler_Sensor_mehrfach 0 "Fehler_passiv" 1 "Fehler_aktiv";
VAL_ 2463978687 WH_Fehler_Sensor_mehrfach_Status 0 "Test_nicht_durchgefuehrt" 1 "Test_durchgefuehrt";
VAL_ 2463978687 WH_Fehler_Shiftlock 0 "Fehler_passiv" 1 "Fehler_aktiv";
VAL_ 2463978687 WH_Fehler_Shiftlock_Status 0 "Test_nicht_durchgefuehrt" 1 "Test_durchgefuehrt";
VAL_ 916 WBA_Fahrstufe_02 0 "Zwischenstellung_keine_Position" 1 "Position_P" 2 "Position_R" 3 "Position_N" 4 "Position_D" 5 "Position_S" 6 "Position_M_Tippfunktion" 7 "Kurzzeit_M" 8 "Position_E" 9 "Position_MS" 10 "Position_S_Plus" 11 "Position_MS_Plus" 12 "Position_Offroad" 13 "Position_B";
VAL_ 916 WBA_ZielFahrstufe 0 "keine_Gangempfehlung_kein_Gang_eingelegt" 1 "Pfeil_nach_S" 2 "Pfeil_nach_D" 3 "Pfeil_nach_M" 4 "Pfeil_nach_E";
VAL_ 916 WBA_GE_Warnung_02 0 "keine_Anzeige" 1 "Fehlereskalationsstufe_I" 2 "Fehlereskalationsstufe_II" 3 "Weiterfahrt_nur_eingeschraenkt_moeglich__Kein_R_Gang" 4 "Getriebefehler_Weiterfahrt_nur_in_D_moeglich__P_bei_Motor_aus" 5 "Wegrollgefahr__P_nicht_moeglich" 6 "Paddlenotbetrieb_Schema+Warnung" 7 "Paddlenotbetrieb_Schema" 8 "Geschwindigkeitsbegrenzung_Notlauf" 9 "Fehlereskalationsst_o_Einschr" 10 "Fehlereskalationsstufe_v_Limit" 11 "Parksperre_Infostufe" 12 "Parksperre_Warnstufe_I" 13 "Parksperre_Warnstufe_II";
VAL_ 916 WBA_eing_Gang_02 0 "keine_Ganganzeige" 1 "Gang_1" 2 "Gang_2" 3 "Gang_3" 4 "Gang_4" 5 "Gang_5" 6 "Gang_6" 7 "Gang_7" 8 "Gang_8" 9 "Gang_9" 10 "Funktion_Ganganzeigeunterdrueckung" 11 "Gang_10";
VAL_ 916 WBA_GE_Texte 0 "keine_Anzeige" 1 "zum_Einlegen_einer_Fahrstufe_Fussbremse_betaetigen__ShiftLock_Information" 2 "zum_Einlegen_von_R_N_D_Fussbremse_betaetigen_und_Motor_starten" 3 "Wegrollgefahr_bitte_P_einlegen" 4 "Achtung_Zeitueberschreitung_P_wird_eingelegt" 5 "Wiederanmeldeprozedur_Bremse_betaetigen" 6 "P_nur_im_Stillstand_moeglich" 7 "Rennstart_aktiv";
VAL_ 916 WBA_Segeln_aktiv 0 "inaktiv" 1 "aktiv";
VAL_ 916 WBA_Schaltschema_02 0 "kein_Schaltschema" 1 "R_N_DS" 2 "R_N_ES" 3 "R_N_DB" 4 "R_N_D";
VAL_ 916 WBA_Schaltschema_FS_inaktiv 0 "alle_Fahrstufen_aktiv" 1 "Fahrstufe_Rueckwaerts_inaktiv" 2 "nur_P_und_N_aktiv" 3 "alle_Fahrstufen_inaktiv";
VAL_ 916 WBA_GE_Zusatzwarnungen 0 "keine_Anzeige" 1 "Getriebeueberhitzung_Warnstufe_I" 2 "Getriebeueberhitzung_Warnstufe_II" 3 "Getriebefehler_Bitte_anhalten_und_P_einlegen";
VAL_ 916 GE_Sollgang 0 "keine_Empfehlung" 1 "Gang_1" 2 "Gang_2" 3 "Gang_3" 4 "Gang_4" 5 "Gang_5" 6 "Gang_6" 7 "Gang_7" 8 "Gang_8" 9 "Gang_9" 11 "Gang_10";
VAL_ 916 GE_Tipschaltempf_verfuegbar 0 "nicht_verfuegbar" 1 "verfuegbar";
VAL_ 916 WBA_GE_Texte_02 0 "Keine_Anzeige" 1 "Fahrtrichtungswechsel_nur_nach_Stillstandt" 2 "Ladestecker_gesteckt" 3 "zusaetzlicher_Service_erforderlich" 4 "eLaunch_Aktiv" 5 "eLaunch_nicht_moeglich" 6 "WH_S_nicht_moeglich_Offroad" 7 "WH_S_nicht_moeglich_RangeMode";
VAL_ 916 WBA_Schaltschema_Tippgasse 0 "keine_Tippgasse_vorhanden" 1 "Tippgasse_vorhanden";
VAL_ 916 WBA_Schaltschema_Fahreraktion 0 "keine_Fahreraktion" 1 "Fahreraktion";
VAL_ 916 WBA_Schaltschema_FS_vorwaerts 0 "FS1_aktiv__FS2_moeglich" 1 "FS2_aktiv__FS1_moeglich" 2 "FS1_aktiv__FS2_nicht_moeglich" 3 "FS2_aktiv__FS1_nicht_moeglich";
VAL_ 916 WBA_Shiftlock_Lampe 0 "Shiftlock_Lampe_AUS" 1 "Shiftlock_Lampe_EIN";
VAL_ 916 WBA_Anforderung_Akustik 0 "Akustik_aus" 1 "Akustik_ein";
VAL_ 916 WBA_Blinken 0 "kein_WBA_Blinken" 1 "WBA_Blinken";
VAL_ 916 GE_Wiederstart_Anz_Std 0 "keine_Anzeige" 1 "Standard_Wiederstartgrund";
VAL_ 916 GE_Stoppverbot_Anz_01 0 "keine_Anzeige" 1 "Temperaturbedingung";
VAL_ 916 GE_Stoppverbot_Anz_02 0 "keine_Anzeige" 1 "Drucksensorausfall";
VAL_ 916 GE_Stoppverbot_Anz_03 0 "keine_Anzeige" 1 "Grundeinstellung";
VAL_ 916 GE_Stoppverbot_Anz_04 0 "keine_Anzeige" 1 "Demontagestellung";
VAL_ 916 GE_Stoppverbot_Anz_05 0 "keine_Anzeige" 1 "Eingeschraenkte_Fahrfunktion_Notlauf_Liegenbleiber";
VAL_ 916 GE_Stoppverbot_Anz_06 0 "keine_Anzeige" 1 "Stoppverbot_ueber_Applikation";
VAL_ 916 GE_Stoppverbot_Anz_07 0 "keine_Anzeige" 1 "Schaltung_aktiv";
VAL_ 916 GE_Stoppverbot_Anz_Std 0 "keine_Anzeige" 1 "Standard_Stoppvetogrund";
VAL_ 1361 WFS_Schluessel_Fahrberecht 0 "kein authorisierter Schluessel erkannt" 1 "aktive_Funkschluessel_Nr_01" 2 "aktive_Funkschluessel_Nr_02" 3 "aktive_Funkschluessel_Nr_03" 4 "aktive_Funkschluessel_Nr_04" 5 "aktive_Funkschluessel_Nr_05" 6 "aktive_Funkschluessel_Nr_06" 7 "aktive_Funkschluessel_Nr_07" 8 "aktive_Funkschluessel_Nr_08" 9 "ungueltig_09" 10 "ungueltig_10" 11 "ungueltig_11" 12 "ungueltig_12" 13 "ungueltig_13" 14 "ungueltig_14" 15 "digitaler_Schluessel_aktiv";
VAL_ 1361 WFS_Verbauinfo_ELV 0 "ELV_nicht_verbaut" 1 "ELV_verbaut";
VAL_ 1361 WFS_ID_Geb_autorisiert 0 "Schluessel_nicht_authorisiert" 1 "Schluessel authorisiert";
VAL_ 1361 WFS_ID_Geb_autorisiert_in_Kl15 0 "nicht_authorisiert_in_Kl15" 1 "authorisiert_in_Kl15";
VAL_ 1361 WFS_ID_Geb_steckt 0 "kein_Schluessel_im_Zuendschloss" 1 " Schluessel steckt im Zuendschloss";
VAL_ 1361 WFS_Safe 1 "WFS nicht deaktiviert";
VAL_ 1361 WFS_LZ 0 "nicht def." 1 "LZ 1" 2 "LZ 2" 3 "LZ 3";
VAL_ 1361 WFS_ELV_authorisiert 0 "ELV_nicht_authorisiert" 1 "ELV_authorisiert";
VAL_ 1361 WFS_LF_Aktiv 0 "Funktempfang_nicht_aktiv" 1 "LF_Funkempfang_aktiv";
VAL_ 1361 WFS_Betrieb_Lesespule 0 "keine_Schluesselkomm_Lesespule" 1 "Schluesselkomm_Lesespule";
VAL_ 1361 WFS_Klemmenfreigabe 0 "keine_Freigabe" 1 "Freigabe";
VAL_ 1361 WFS_Fahrerhinweise 0 "Keine_Anzeigeanforderung" 1 "Schuessel_Auth_niO" 2 "Notlauf_aktiv" 3 "Schluessel_Kessy_nicht_gefunden";
VAL_ 1361 WFS_Parken_Status 0 "Limitierung_inaktiv" 1 "Limitierung_aktiv" 2 "Abbruch";
VAL_ 1411 ZV_verriegeln_Anf 0 "nicht_betaetigt" 1 "betaetigt";
VAL_ 1411 ZV_STSG_HFS_Anf 0 "keine_Anforderung" 1 "Anforderung";
VAL_ 1411 ZV_STSG_HBFS_Anf 0 "keine_Anforderung" 1 "Anforderung";
VAL_ 1411 ZV_Anf_Challenge_Auth 0 "nicht_aktiv" 1 "aktiv";
VAL_ 1411 BCM_FH_Freigabe 1 "Funktionsfreigabe Fensterheber";
VAL_ 1411 BCM_Komfortfkt_Freigabe 0 "Komfortfunktion gesperrt" 1 "globale Freigabe der Komfortfunktion erteilt";
VAL_ 1411 BCM_HSK_Freigabe 0 "erlauben" 1 "sperren";
VAL_ 1411 BCM_Verdeck_Freigabe 0 "Verdeckbetrieb nicht erlaubt" 1 "Verdeckbetrieb erlaubt";
VAL_ 1411 ZV_verriegelt_intern_ist 1 "Fahrzeug innen verriegelt; Istzustand";
VAL_ 1411 ZV_verriegelt_extern_ist 1 "Fahrzeug_aussen_verriegelt_Istzustand";
VAL_ 1411 ZV_verriegelt_intern_soll 1 "Fahrzeug verriegelt intern; Sollzusstand";
VAL_ 1411 ZV_verriegelt_extern_soll 1 "Fahrzeug verriegelt extern; Sollzusstand";
VAL_ 1411 ZV_gesafet_extern_ist 1 "Fahrzeug aussen gesafet; Istzustand";
VAL_ 1411 ZV_gesafet_extern_soll 1 "Fahrzeug_aussen_gesafet_Sollzustand";
VAL_ 1411 ZV_Einzeltuerentriegelung 1 "Fahrzeug an Einzeltuer entriegelt";
VAL_ 1411 ZV_Heckeinzelentriegelung 1 "Heckdeckeleinzelentriegelung";
VAL_ 1411 ZV_FT_offen 1 "FT_geoeffnet";
VAL_ 1411 ZV_BT_offen 1 "BT_geoeffnet";
VAL_ 1411 ZV_HFS_offen 0 "geschlossen" 1 "offen";
VAL_ 1411 ZV_HBFS_offen 0 "geschlossen" 1 "offen";
VAL_ 1411 ZV_HD_offen 1 "Heckdeckel_auf";
VAL_ 1411 ZV_HS_offen 0 "Heckscheibe_geschlossen" 1 "Heckscheibe auf";
VAL_ 1411 IRUE_aktiv 0 "unscharf" 1 "scharf";
VAL_ 1411 DWA_aktiv 0 "unscharf" 1 "scharf";
VAL_ 1411 FFB_HDF_Taste 0 "Taste_nicht_betaetigt" 1 "HDF_Taste_am_Funkschluessel_betaetigt";
VAL_ 1411 FFB_Panik_Taste 0 "Taste_nicht_betaetigt" 1 "Panik_Taste_am_Funkschluessel_betaetigt";
VAL_ 1411 FFB_Auf_Taste 0 "Taste_nicht_betaetigt" 1 "Oeffnentaste_betaetigt";
VAL_ 1411 FFB_Zu_Taste 0 "Taste_nicht_betaetigt" 1 "Zu_Taste_am_Funkschluessel_betaetigt";
VAL_ 1411 FFB_CarFinder 0 "nicht aktiv" 1 "aktiv";
VAL_ 1411 FFB_Komfortoeffnen 0 "kein_Komfortoeffnen_empfangen" 1 "Komfortoeffnen ueber Funk empfangen";
VAL_ 1411 FFB_Komfortschliessen 0 "kein_Komfortschliessen_empfangen" 1 "Komfortschliessen ueber Funk empfangen";
VAL_ 1411 FBS_IDG_in_Reichweite 0 "ausser_Reichweite_bzw_nicht_ermittelbar" 1 "innerhalb_Reichweite";
VAL_ 1411 ZV_Schluessel_Zugang 0 "kein authorisierter Schluessel erkannt " 1 "aktive_Funkschluessel_Nr_01" 2 "aktive_Funkschluessel_Nr_02" 3 "aktive_Funkschluessel_Nr_03" 4 "aktive_Funkschluessel_Nr_04" 5 "aktive_Funkschluessel_Nr_05" 6 "aktive_Funkschluessel_Nr_06" 7 "aktive_Funkschluessel_Nr_07" 8 "aktive_Funkschluessel_Nr_08" 9 "ungueltig_09" 10 "ungueltig_10" 11 "ungueltig_11" 12 "ungueltig_12" 13 "ungueltig_13" 14 "ungueltig_14" 15 "ungueltig_15";
VAL_ 1411 ZV_SafeFunktion_aktiv 0 "inaktiv" 1 "aktiv";
VAL_ 1411 FBS_Warn_Schluessel_Batt 0 "i.O." 1 "defekt";
VAL_ 1411 ZV_Oeffnungsmodus 0 "globale_Oeffnung" 1 "ZV_mit_Einzeltuerentr" 2 "ZV_individuell_selektiv" 3 "ZV_seitenselektiv";
VAL_ 1411 ZV_ist_Zustand_verfuegbar 0 "nicht_verfuegbar" 1 "verfuegbar_alle_TSGs_am_Bus";
VAL_ 1411 IRUE_Taster_Fkts_LED 0 "LED_aus" 1 "LED_ein";
VAL_ 1411 ZV_Tankklappe_offen 0 "Tankklappe_geschlossen" 1 "Tankklappe_offen";
VAL_ 1411 ZV_Rollo_auf 0 "inaktiv" 1 "aktiv";
VAL_ 1411 ZV_Rollo_zu 0 "inaktiv" 1 "aktiv";
VAL_ 1411 ZV_SAD_auf 0 "inaktiv" 1 "aktiv";
VAL_ 1411 ZV_SAD_zu 0 "inaktiv" 1 "aktiv";
VAL_ 1411 ZV_verriegelt_soll 0 "Init" 1 "nicht_verriegelt" 2 "verriegelt";
